VERSION ""

NS_ :

BS_:

BU_: PowertrainControlModule AtmosphericSensor SafetyRestraintSystem2 Aftertreatment_2_GasOutlet Aftertreatment_2_GasIntake DieselParticulateFilterControl Turbocharger SafetyRestraintSystem1 CabDisplay2 Aftertreatment_1_GasOutlet Aftertreatment_1_GasIntake OnBoardDataLogger OffBoardDiagnosticTool2 OffBoardDiagnosticTool1 FileServer ParkingBrakeController SeatController2 FanDriveController SteeringColumnUnit CommunicationUnitRadio CommunicationUnitSatellite CommunicationUnitCellular PropulsionBatteryCharger ChassisController2 ChassisController1 EngineValveControl AuxiliaryHeater2 AuxiliaryHeater1 ClutchUnit RampControl InformationSystem1 SuspensionSystemController2 OilSensor VehicleDynamicStability ExhaustEmissionController TransmissionDisplay2 TransmissionDisplay1 ClimateControl2 WaterPumpController RearAxleSteeringController LightingOperatorControl SeatController1 IgnitionController2 IgnitionController1 TirePressureController CabController2 CabController1 PneumaticSystemController SuspensionSystemController1 HydraulicPumpController EnduranceBrakingSystem RetarderExhaustEngine2 OnBoardDiagnosticUnit HeadwayController RetarderExhaustEngine1 CabDisplay1 ManagementComputer VirtualTerminal OffVehicleGateway PowerTakeOffFront HitchControl AuxiliaryValveControl BodyController TractorTrailerBridge1 StarterSystem ElectricalSystem VehicleSecurity VehicleNavigation AerodynamicControl ElectricalChargingSystem ClimateControl1 TripRecorder InstrumentCluster SuspensionDriveAxle2 SuspensionDriveAxle1 SuspensionSteerAxle SteeringController FuelSystem CruiseControl RetarderDriveline RetarderEngine BrakesDriveAxle2 BrakesDriveAxle1 BrakesSystemController BrakesSteerAxle AxleDrive2 AxleDrive1 AxleSteering PowerTakeOff ShiftConsoleSecondary ShiftConsolePrimary Transmission2 Transmission1 Engine2 Engine1

BO_ 2566612990 MG2IAPL: 8 Vector__XXX
 SG_ TrqLimDueToMachineCharacter_0000 : 38|2@1+ (1,0) [0|3] "" Vector__XXX
 SG_ PLedDueToActiveSpdRateLmt : 36|2@1+ (1,0) [0|3] "" Vector__XXX
 SG_ PLedDueToActiveTrqRateLmt : 34|2@1+ (1,0) [0|3] "" Vector__XXX
 SG_ PLedDueToFaultCondition : 32|2@1+ (1,0) [0|3] "" Vector__XXX
 SG_ PLedDueToMotorTemp : 30|2@1+ (1,0) [0|3] "" Vector__XXX
 SG_ PLedDueToInvTemp : 28|2@1+ (1,0) [0|3] "" Vector__XXX
 SG_ PLedDueToSpdMin : 24|2@1+ (1,0) [0|3] "" Vector__XXX
 SG_ PLedDueToSpdMax : 22|2@1+ (1,0) [0|3] "" Vector__XXX
 SG_ PLedDueToTrqMin : 20|2@1+ (1,0) [0|3] "" Vector__XXX
 SG_ PLedDueToTrqMax : 18|2@1+ (1,0) [0|3] "" Vector__XXX
 SG_ PLedDueToDCSidePwrMin : 16|2@1+ (1,0) [0|3] "" Vector__XXX
 SG_ PLedDueToDCSidePwrMax : 14|2@1+ (1,0) [0|3] "" Vector__XXX
 SG_ PLedDueToMechPwrMin : 12|2@1+ (1,0) [0|3] "" Vector__XXX
 SG_ PLedDueToMechPwrMax : 10|2@1+ (1,0) [0|3] "" Vector__XXX
 SG_ PLedDueToDCSideVMin : 8|2@1+ (1,0) [0|3] "" Vector__XXX
 SG_ PLedDueToDCSideVMax : 6|2@1+ (1,0) [0|3] "" Vector__XXX
 SG_ PLedDueToDCSideCurMin : 4|2@1+ (1,0) [0|3] "" Vector__XXX
 SG_ PLedDueToDCSideCurMax : 2|2@1+ (1,0) [0|3] "" Vector__XXX
 SG_ PLedDueToUndefinedReason : 0|2@1+ (1,0) [0|3] "" Vector__XXX

BO_ 2633721598 VFSSM4NAMES: 104 Vector__XXX
 SG_ ReleaseZone2Name : 768|64@1+ (1,0) [0|255] "" Vector__XXX
 SG_ ReleaseZone1Name : 704|64@1+ (1,0) [0|255] "" Vector__XXX
 SG_ HeatZone2Name : 640|64@1+ (1,0) [0|255] "" Vector__XXX
 SG_ HeatZone1Name : 576|64@1+ (1,0) [0|255] "" Vector__XXX
 SG_ DetectorZone8Name : 512|64@1+ (1,0) [0|255] "" Vector__XXX
 SG_ DetectorZone7Name : 448|64@1+ (1,0) [0|255] "" Vector__XXX
 SG_ DetectorZone6Name : 384|64@1+ (1,0) [0|255] "" Vector__XXX
 SG_ DetectorZone5Name : 320|64@1+ (1,0) [0|255] "" Vector__XXX
 SG_ DetectorZone4Name : 256|64@1+ (1,0) [0|255] "" Vector__XXX
 SG_ DetectorZone3Name : 192|64@1+ (1,0) [0|255] "" Vector__XXX
 SG_ DetectorZone2Name : 128|64@1+ (1,0) [0|255] "" Vector__XXX
 SG_ DetectorZone1Name : 64|64@1+ (1,0) [0|255] "" Vector__XXX
 SG_ Name : 0|64@1+ (1,0) [0|255] "" Vector__XXX

BO_ 2633721342 VFSSM3NAMES: 104 Vector__XXX
 SG_ ReleaseZone2Name : 768|64@1+ (1,0) [0|255] "" Vector__XXX
 SG_ ReleaseZone1Name : 704|64@1+ (1,0) [0|255] "" Vector__XXX
 SG_ HeatZone2Name : 640|64@1+ (1,0) [0|255] "" Vector__XXX
 SG_ HeatZone1Name : 576|64@1+ (1,0) [0|255] "" Vector__XXX
 SG_ DetectorZone8Name : 512|64@1+ (1,0) [0|255] "" Vector__XXX
 SG_ DetectorZone7Name : 448|64@1+ (1,0) [0|255] "" Vector__XXX
 SG_ DetectorZone6Name : 384|64@1+ (1,0) [0|255] "" Vector__XXX
 SG_ DetectorZone5Name : 320|64@1+ (1,0) [0|255] "" Vector__XXX
 SG_ DetectorZone4Name : 256|64@1+ (1,0) [0|255] "" Vector__XXX
 SG_ DetectorZone3Name : 192|64@1+ (1,0) [0|255] "" Vector__XXX
 SG_ DetectorZone2Name : 128|64@1+ (1,0) [0|255] "" Vector__XXX
 SG_ DetectorZone1Name : 64|64@1+ (1,0) [0|255] "" Vector__XXX
 SG_ Name : 0|64@1+ (1,0) [0|255] "" Vector__XXX

BO_ 2633721086 VFSSM2NAMES: 104 Vector__XXX
 SG_ ReleaseZone2Name : 768|64@1+ (1,0) [0|255] "" Vector__XXX
 SG_ ReleaseZone1Name : 704|64@1+ (1,0) [0|255] "" Vector__XXX
 SG_ HeatZone2Name : 640|64@1+ (1,0) [0|255] "" Vector__XXX
 SG_ HeatZone1Name : 576|64@1+ (1,0) [0|255] "" Vector__XXX
 SG_ DetectorZone8Name : 512|64@1+ (1,0) [0|255] "" Vector__XXX
 SG_ DetectorZone7Name : 448|64@1+ (1,0) [0|255] "" Vector__XXX
 SG_ DetectorZone6Name : 384|64@1+ (1,0) [0|255] "" Vector__XXX
 SG_ DetectorZone5Name : 320|64@1+ (1,0) [0|255] "" Vector__XXX
 SG_ DetectorZone4Name : 256|64@1+ (1,0) [0|255] "" Vector__XXX
 SG_ DetectorZone3Name : 192|64@1+ (1,0) [0|255] "" Vector__XXX
 SG_ DetectorZone2Name : 128|64@1+ (1,0) [0|255] "" Vector__XXX
 SG_ DetectorZone1Name : 64|64@1+ (1,0) [0|255] "" Vector__XXX
 SG_ Name : 0|64@1+ (1,0) [0|255] "" Vector__XXX

BO_ 2633720830 VFSSM1NAMES: 104 Vector__XXX
 SG_ ReleaseZone2Name : 768|64@1+ (1,0) [0|255] "" Vector__XXX
 SG_ ReleaseZone1Name : 704|64@1+ (1,0) [0|255] "" Vector__XXX
 SG_ HeatZone2Name : 640|64@1+ (1,0) [0|255] "" Vector__XXX
 SG_ HeatZone1Name : 576|64@1+ (1,0) [0|255] "" Vector__XXX
 SG_ DetectorZone8Name : 512|64@1+ (1,0) [0|255] "" Vector__XXX
 SG_ DetectorZone7Name : 448|64@1+ (1,0) [0|255] "" Vector__XXX
 SG_ DetectorZone6Name : 384|64@1+ (1,0) [0|255] "" Vector__XXX
 SG_ DetectorZone5Name : 320|64@1+ (1,0) [0|255] "" Vector__XXX
 SG_ DetectorZone4Name : 256|64@1+ (1,0) [0|255] "" Vector__XXX
 SG_ DetectorZone3Name : 192|64@1+ (1,0) [0|255] "" Vector__XXX
 SG_ DetectorZone2Name : 128|64@1+ (1,0) [0|255] "" Vector__XXX
 SG_ DetectorZone1Name : 64|64@1+ (1,0) [0|255] "" Vector__XXX
 SG_ Name : 0|64@1+ (1,0) [0|255] "" Vector__XXX

BO_ 2633720574 VFSSM4AUX: 16 Vector__XXX
 SG_ SecondPwrV : 112|16@1+ (0.01,0) [0|642.55] "V" Vector__XXX
 SG_ PrimaryPwrV : 96|16@1+ (0.01,0) [0|642.55] "V" Vector__XXX
 SG_ PressSw2Data : 80|16@1+ (0.01,0) [0|642.55] "V" Vector__XXX
 SG_ PressSw1Data : 64|16@1+ (0.01,0) [0|642.55] "V" Vector__XXX
 SG_ ReleaseZone2Data : 48|16@1+ (0.01,0) [0|642.55] "V" Vector__XXX
 SG_ ReleaseZone1Data : 32|16@1+ (0.01,0) [0|642.55] "V" Vector__XXX
 SG_ HeatZone2Data : 16|16@1+ (0.01,0) [0|642.55] "V" Vector__XXX
 SG_ HeatZone1Data : 0|16@1+ (0.01,0) [0|642.55] "V" Vector__XXX

BO_ 2633720318 VFSSM3AUX: 16 Vector__XXX
 SG_ SecondPwrV : 112|16@1+ (0.01,0) [0|642.55] "V" Vector__XXX
 SG_ PrimaryPwrV : 96|16@1+ (0.01,0) [0|642.55] "V" Vector__XXX
 SG_ PressSw2Data : 80|16@1+ (0.01,0) [0|642.55] "V" Vector__XXX
 SG_ PressSw1Data : 64|16@1+ (0.01,0) [0|642.55] "V" Vector__XXX
 SG_ ReleaseZone2Data : 48|16@1+ (0.01,0) [0|642.55] "V" Vector__XXX
 SG_ ReleaseZone1Data : 32|16@1+ (0.01,0) [0|642.55] "V" Vector__XXX
 SG_ HeatZone2Data : 16|16@1+ (0.01,0) [0|642.55] "V" Vector__XXX
 SG_ HeatZone1Data : 0|16@1+ (0.01,0) [0|642.55] "V" Vector__XXX

BO_ 2633720062 VFSSM2AUX: 16 Vector__XXX
 SG_ SecondPwrV : 112|16@1+ (0.01,0) [0|642.55] "V" Vector__XXX
 SG_ PrimaryPwrV : 96|16@1+ (0.01,0) [0|642.55] "V" Vector__XXX
 SG_ PressSw2Data : 80|16@1+ (0.01,0) [0|642.55] "V" Vector__XXX
 SG_ PressSw1Data : 64|16@1+ (0.01,0) [0|642.55] "V" Vector__XXX
 SG_ ReleaseZone2Data : 48|16@1+ (0.01,0) [0|642.55] "V" Vector__XXX
 SG_ ReleaseZone1Data : 32|16@1+ (0.01,0) [0|642.55] "V" Vector__XXX
 SG_ HeatZone2Data : 16|16@1+ (0.01,0) [0|642.55] "V" Vector__XXX
 SG_ HeatZone1Data : 0|16@1+ (0.01,0) [0|642.55] "V" Vector__XXX

BO_ 2633719806 VFSSM1AUX: 16 Vector__XXX
 SG_ SecondPwrV : 112|16@1+ (0.01,0) [0|642.55] "V" Vector__XXX
 SG_ PrimaryPwrV : 96|16@1+ (0.01,0) [0|642.55] "V" Vector__XXX
 SG_ PressSw2Data : 80|16@1+ (0.01,0) [0|642.55] "V" Vector__XXX
 SG_ PressSw1Data : 64|16@1+ (0.01,0) [0|642.55] "V" Vector__XXX
 SG_ ReleaseZone2Data : 48|16@1+ (0.01,0) [0|642.55] "V" Vector__XXX
 SG_ ReleaseZone1Data : 32|16@1+ (0.01,0) [0|642.55] "V" Vector__XXX
 SG_ HeatZone2Data : 16|16@1+ (0.01,0) [0|642.55] "V" Vector__XXX
 SG_ HeatZone1Data : 0|16@1+ (0.01,0) [0|642.55] "V" Vector__XXX

BO_ 2633719550 VFSSM4DET: 24 Vector__XXX
 SG_ Detector8Data : 176|16@1+ (1,0) [0|255] "" Vector__XXX
 SG_ Detector8DetectorDataSLOT : 172|4@1+ (1,0) [0|15] "" Vector__XXX
 SG_ Detector8DetectorType : 168|4@1+ (1,0) [0|15] "" Vector__XXX
 SG_ Detector7Data : 152|16@1+ (1,0) [0|255] "" Vector__XXX
 SG_ Detector7DetectorDataSLOT : 148|4@1+ (1,0) [0|15] "" Vector__XXX
 SG_ Detector7DetectorType : 144|4@1+ (1,0) [0|15] "" Vector__XXX
 SG_ Detector6Data : 128|16@1+ (1,0) [0|255] "" Vector__XXX
 SG_ Detector6DetectorDataSLOT : 124|4@1+ (1,0) [0|15] "" Vector__XXX
 SG_ Detector6DetectorType : 120|4@1+ (1,0) [0|15] "" Vector__XXX
 SG_ Detector5Data : 104|16@1+ (1,0) [0|255] "" Vector__XXX
 SG_ Detector5DetectorDataSLOT : 100|4@1+ (1,0) [0|15] "" Vector__XXX
 SG_ Detector5DetectorType : 96|4@1+ (1,0) [0|15] "" Vector__XXX
 SG_ Detector4Data : 80|16@1+ (1,0) [0|255] "" Vector__XXX
 SG_ Detector4DetectorDataSLOT : 76|4@1+ (1,0) [0|15] "" Vector__XXX
 SG_ Detector4DetectorType : 72|4@1+ (1,0) [0|15] "" Vector__XXX
 SG_ Detector3Data : 56|16@1+ (1,0) [0|255] "" Vector__XXX
 SG_ Detector3DetectorDataSLOT : 52|4@1+ (1,0) [0|15] "" Vector__XXX
 SG_ Detector3DetectorType : 48|4@1+ (1,0) [0|15] "" Vector__XXX
 SG_ Detector2Data : 32|16@1+ (1,0) [0|255] "" Vector__XXX
 SG_ Detector2DetectorDataSLOT : 28|4@1+ (1,0) [0|15] "" Vector__XXX
 SG_ Detector2DetectorType : 24|4@1+ (1,0) [0|15] "" Vector__XXX
 SG_ Detector1Data : 8|16@1+ (1,0) [0|255] "" Vector__XXX
 SG_ Detector1DetectorDataSLOT : 4|4@1+ (1,0) [0|15] "" Vector__XXX
 SG_ Detector1DetectorType : 0|4@1+ (1,0) [0|15] "" Vector__XXX

BO_ 2633719294 VFSSM3DET: 24 Vector__XXX
 SG_ Detector8Data : 176|16@1+ (1,0) [0|255] "" Vector__XXX
 SG_ Detector8DetectorDataSLOT : 172|4@1+ (1,0) [0|15] "" Vector__XXX
 SG_ Detector8DetectorType : 168|4@1+ (1,0) [0|15] "" Vector__XXX
 SG_ Detector7Data : 152|16@1+ (1,0) [0|255] "" Vector__XXX
 SG_ Detector7DetectorDataSLOT : 148|4@1+ (1,0) [0|15] "" Vector__XXX
 SG_ Detector7DetectorType : 144|4@1+ (1,0) [0|15] "" Vector__XXX
 SG_ Detector6Data : 128|16@1+ (1,0) [0|255] "" Vector__XXX
 SG_ Detector6DetectorDataSLOT : 124|4@1+ (1,0) [0|15] "" Vector__XXX
 SG_ Detector6DetectorType : 120|4@1+ (1,0) [0|15] "" Vector__XXX
 SG_ Detector5Data : 104|16@1+ (1,0) [0|255] "" Vector__XXX
 SG_ Detector5DetectorDataSLOT : 100|4@1+ (1,0) [0|15] "" Vector__XXX
 SG_ Detector5DetectorType : 96|4@1+ (1,0) [0|15] "" Vector__XXX
 SG_ Detector4Data : 80|16@1+ (1,0) [0|255] "" Vector__XXX
 SG_ Detector4DetectorDataSLOT : 76|4@1+ (1,0) [0|15] "" Vector__XXX
 SG_ Detector4DetectorType : 72|4@1+ (1,0) [0|15] "" Vector__XXX
 SG_ Detector3Data : 56|16@1+ (1,0) [0|255] "" Vector__XXX
 SG_ Detector3DetectorDataSLOT : 52|4@1+ (1,0) [0|15] "" Vector__XXX
 SG_ Detector3DetectorType : 48|4@1+ (1,0) [0|15] "" Vector__XXX
 SG_ Detector2Data : 32|16@1+ (1,0) [0|255] "" Vector__XXX
 SG_ Detector2DetectorDataSLOT : 28|4@1+ (1,0) [0|15] "" Vector__XXX
 SG_ Detector2DetectorType : 24|4@1+ (1,0) [0|15] "" Vector__XXX
 SG_ Detector1Data : 8|16@1+ (1,0) [0|255] "" Vector__XXX
 SG_ Detector1DetectorDataSLOT : 4|4@1+ (1,0) [0|15] "" Vector__XXX
 SG_ Detector1DetectorType : 0|4@1+ (1,0) [0|15] "" Vector__XXX

BO_ 2633719038 VFSSM2DET: 24 Vector__XXX
 SG_ Detector8Data : 176|16@1+ (1,0) [0|255] "" Vector__XXX
 SG_ Detector8DetectorDataSLOT : 172|4@1+ (1,0) [0|15] "" Vector__XXX
 SG_ Detector8DetectorType : 168|4@1+ (1,0) [0|15] "" Vector__XXX
 SG_ Detector7Data : 152|16@1+ (1,0) [0|255] "" Vector__XXX
 SG_ Detector7DetectorDataSLOT : 148|4@1+ (1,0) [0|15] "" Vector__XXX
 SG_ Detector7DetectorType : 144|4@1+ (1,0) [0|15] "" Vector__XXX
 SG_ Detector6Data : 128|16@1+ (1,0) [0|255] "" Vector__XXX
 SG_ Detector6DetectorDataSLOT : 124|4@1+ (1,0) [0|15] "" Vector__XXX
 SG_ Detector6DetectorType : 120|4@1+ (1,0) [0|15] "" Vector__XXX
 SG_ Detector5Data : 104|16@1+ (1,0) [0|255] "" Vector__XXX
 SG_ Detector5DetectorDataSLOT : 100|4@1+ (1,0) [0|15] "" Vector__XXX
 SG_ Detector5DetectorType : 96|4@1+ (1,0) [0|15] "" Vector__XXX
 SG_ Detector4Data : 80|16@1+ (1,0) [0|255] "" Vector__XXX
 SG_ Detector4DetectorDataSLOT : 76|4@1+ (1,0) [0|15] "" Vector__XXX
 SG_ Detector4DetectorType : 72|4@1+ (1,0) [0|15] "" Vector__XXX
 SG_ Detector3Data : 56|16@1+ (1,0) [0|255] "" Vector__XXX
 SG_ Detector3DetectorDataSLOT : 52|4@1+ (1,0) [0|15] "" Vector__XXX
 SG_ Detector3DetectorType : 48|4@1+ (1,0) [0|15] "" Vector__XXX
 SG_ Detector2Data : 32|16@1+ (1,0) [0|255] "" Vector__XXX
 SG_ Detector2DetectorDataSLOT : 28|4@1+ (1,0) [0|15] "" Vector__XXX
 SG_ Detector2DetectorType : 24|4@1+ (1,0) [0|15] "" Vector__XXX
 SG_ Detector1Data : 8|16@1+ (1,0) [0|255] "" Vector__XXX
 SG_ Detector1DetectorDataSLOT : 4|4@1+ (1,0) [0|15] "" Vector__XXX
 SG_ Detector1DetectorType : 0|4@1+ (1,0) [0|15] "" Vector__XXX

BO_ 2633718782 VFSSM1DET: 24 Vector__XXX
 SG_ Detector8Data : 176|16@1+ (1,0) [0|255] "" Vector__XXX
 SG_ Detector8DetectorDataSLOT : 172|4@1+ (1,0) [0|15] "" Vector__XXX
 SG_ Detector8DetectorType : 168|4@1+ (1,0) [0|15] "" Vector__XXX
 SG_ Detector7Data : 152|16@1+ (1,0) [0|255] "" Vector__XXX
 SG_ Detector7DetectorDataSLOT : 148|4@1+ (1,0) [0|15] "" Vector__XXX
 SG_ Detector7DetectorType : 144|4@1+ (1,0) [0|15] "" Vector__XXX
 SG_ Detector6Data : 128|16@1+ (1,0) [0|255] "" Vector__XXX
 SG_ Detector6DetectorDataSLOT : 124|4@1+ (1,0) [0|15] "" Vector__XXX
 SG_ Detector6DetectorType : 120|4@1+ (1,0) [0|15] "" Vector__XXX
 SG_ Detector5Data : 104|16@1+ (1,0) [0|255] "" Vector__XXX
 SG_ Detector5DetectorDataSLOT : 100|4@1+ (1,0) [0|15] "" Vector__XXX
 SG_ Detector5DetectorType : 96|4@1+ (1,0) [0|15] "" Vector__XXX
 SG_ Detector4Data : 80|16@1+ (1,0) [0|255] "" Vector__XXX
 SG_ Detector4DetectorDataSLOT : 76|4@1+ (1,0) [0|15] "" Vector__XXX
 SG_ Detector4DetectorType : 72|4@1+ (1,0) [0|15] "" Vector__XXX
 SG_ Detector3Data : 56|16@1+ (1,0) [0|255] "" Vector__XXX
 SG_ Detector3DetectorDataSLOT : 52|4@1+ (1,0) [0|15] "" Vector__XXX
 SG_ Detector3DetectorType : 48|4@1+ (1,0) [0|15] "" Vector__XXX
 SG_ Detector2Data : 32|16@1+ (1,0) [0|255] "" Vector__XXX
 SG_ Detector2DetectorDataSLOT : 28|4@1+ (1,0) [0|15] "" Vector__XXX
 SG_ Detector2DetectorType : 24|4@1+ (1,0) [0|15] "" Vector__XXX
 SG_ Detector1Data : 8|16@1+ (1,0) [0|255] "" Vector__XXX
 SG_ Detector1DetectorDataSLOT : 4|4@1+ (1,0) [0|15] "" Vector__XXX
 SG_ Detector1DetectorType : 0|4@1+ (1,0) [0|15] "" Vector__XXX

BO_ 2566609662 HVESP1CFG: 19 Vector__XXX
 SG_ NomRatedCapacity : 128|24@1+ (0.001,0) [0|16449.535] "kWh" Vector__XXX
 SG_ CellMinVLmt : 120|8@1+ (0.02044,0) [0|5.11] "V" Vector__XXX
 SG_ CellMaxVLmt : 112|8@1+ (0.02044,0) [0|5.11] "V" Vector__XXX
 SG_ RecommendedMinOperatingTemp : 96|16@1+ (0.03125,-273) [-273|1734.96875] "°C" Vector__XXX
 SG_ RecommendedMaxOperatingTemp : 80|16@1+ (0.03125,-273) [-273|1734.96875] "°C" Vector__XXX
 SG_ RecommendedMaxStOfCharge : 64|16@1+ (0.0015625,0) [0|100.3984375] "%" Vector__XXX
 SG_ RecommendedMinStOfCharge : 48|16@1+ (0.0015625,0) [0|100.3984375] "%" Vector__XXX
 SG_ RecommendedMaxOperatingV : 32|16@1+ (0.05,0) [0|3212.75] "V" Vector__XXX
 SG_ RecommendedMinOperatingV : 16|16@1+ (0.05,0) [0|3212.75] "V" Vector__XXX
 SG_ NomV : 0|16@1+ (0.05,0) [0|3212.75] "V" Vector__XXX

BO_ 2633718270 HVESP1HIST: 19 Vector__XXX
 SG_ TotalEnergyOut : 120|32@1+ (1,0) [0|4211081215] "kWh" Vector__XXX
 SG_ TotalEnergyInput : 88|32@1+ (1,0) [0|4211081215] "kWh" Vector__XXX
 SG_ TotalAccumulatedCharge : 56|32@1+ (100,0) [0|421108121500] "Ah" Vector__XXX
 SG_ TotalEnergyThroughput : 24|32@1+ (100,0) [0|421108121500] "Wh" Vector__XXX
 SG_ ContactorOpenUnderLoadCount : 8|16@1+ (1,0) [0|64255] "" Vector__XXX
 SG_ StOfHealth : 0|8@1+ (0.4,0) [0|100] "%" Vector__XXX

BO_ 2566609150 HVESP2CFG: 19 Vector__XXX
 SG_ NomRatedCapacity : 128|24@1+ (0.001,0) [0|16449.535] "kWh" Vector__XXX
 SG_ CellMinVLmt : 120|8@1+ (0.02044,0) [0|5.11] "V" Vector__XXX
 SG_ CellMaxVLmt : 112|8@1+ (0.02044,0) [0|5.11] "V" Vector__XXX
 SG_ RecommendedMinOperatingTemp : 96|16@1+ (0.03125,-273) [-273|1734.96875] "°C" Vector__XXX
 SG_ RecommendedMaxOperatingTemp : 80|16@1+ (0.03125,-273) [-273|1734.96875] "°C" Vector__XXX
 SG_ RecommendedMaxStOfCharge : 64|16@1+ (0.0015625,0) [0|100.3984375] "%" Vector__XXX
 SG_ RecommendedMinStOfCharge : 48|16@1+ (0.0015625,0) [0|100.3984375] "%" Vector__XXX
 SG_ RecommendedMaxOperatingV : 32|16@1+ (0.05,0) [0|3212.75] "V" Vector__XXX
 SG_ RecommendedMinOperatingV : 16|16@1+ (0.05,0) [0|3212.75] "V" Vector__XXX
 SG_ NomV : 0|16@1+ (0.05,0) [0|3212.75] "V" Vector__XXX

BO_ 2633717758 HVESP2HIST: 19 Vector__XXX
 SG_ TotalEnergyOut : 120|32@1+ (1,0) [0|4211081215] "kWh" Vector__XXX
 SG_ TotalEnergyInput : 88|32@1+ (1,0) [0|4211081215] "kWh" Vector__XXX
 SG_ TotalAccumulatedCharge : 56|32@1+ (100,0) [0|421108121500] "Ah" Vector__XXX
 SG_ TotalEnergyThroughput : 24|32@1+ (100,0) [0|421108121500] "Wh" Vector__XXX
 SG_ ContactorOpenUnderLoadCount : 8|16@1+ (1,0) [0|64255] "" Vector__XXX
 SG_ StOfHealth : 0|8@1+ (0.4,0) [0|100] "%" Vector__XXX

BO_ 2566608638 HVESP3CFG: 19 Vector__XXX
 SG_ NomRatedCapacity : 128|24@1+ (0.001,0) [0|16449.535] "kWh" Vector__XXX
 SG_ CellMinVLmt : 120|8@1+ (0.02044,0) [0|5.11] "V" Vector__XXX
 SG_ CellMaxVLmt : 112|8@1+ (0.02044,0) [0|5.11] "V" Vector__XXX
 SG_ RecommendedMinOperatingTemp : 96|16@1+ (0.03125,-273) [-273|1734.96875] "°C" Vector__XXX
 SG_ RecommendedMaxOperatingTemp : 80|16@1+ (0.03125,-273) [-273|1734.96875] "°C" Vector__XXX
 SG_ RecommendedMaxStOfCharge : 64|16@1+ (0.0015625,0) [0|100.3984375] "%" Vector__XXX
 SG_ RecommendedMinStOfCharge : 48|16@1+ (0.0015625,0) [0|100.3984375] "%" Vector__XXX
 SG_ RecommendedMaxOperatingV : 32|16@1+ (0.05,0) [0|3212.75] "V" Vector__XXX
 SG_ RecommendedMinOperatingV : 16|16@1+ (0.05,0) [0|3212.75] "V" Vector__XXX
 SG_ NomV : 0|16@1+ (0.05,0) [0|3212.75] "V" Vector__XXX

BO_ 2633717246 HVESP3HIST: 19 Vector__XXX
 SG_ TotalEnergyOut : 120|32@1+ (1,0) [0|4211081215] "kWh" Vector__XXX
 SG_ TotalEnergyInput : 88|32@1+ (1,0) [0|4211081215] "kWh" Vector__XXX
 SG_ TotalAccumulatedCharge : 56|32@1+ (100,0) [0|421108121500] "Ah" Vector__XXX
 SG_ TotalEnergyThroughput : 24|32@1+ (100,0) [0|421108121500] "Wh" Vector__XXX
 SG_ ContactorOpenUnderLoadCount : 8|16@1+ (1,0) [0|64255] "" Vector__XXX
 SG_ StOfHealth : 0|8@1+ (0.4,0) [0|100] "%" Vector__XXX

BO_ 2566608126 HVESP4CFG: 19 Vector__XXX
 SG_ NomRatedCapacity : 128|24@1+ (0.001,0) [0|16449.535] "kWh" Vector__XXX
 SG_ CellMinVLmt : 120|8@1+ (0.02044,0) [0|5.11] "V" Vector__XXX
 SG_ CellMaxVLmt : 112|8@1+ (0.02044,0) [0|5.11] "V" Vector__XXX
 SG_ RecommendedMinOperatingTemp : 96|16@1+ (0.03125,-273) [-273|1734.96875] "°C" Vector__XXX
 SG_ RecommendedMaxOperatingTemp : 80|16@1+ (0.03125,-273) [-273|1734.96875] "°C" Vector__XXX
 SG_ RecommendedMaxStOfCharge : 64|16@1+ (0.0015625,0) [0|100.3984375] "%" Vector__XXX
 SG_ RecommendedMinStOfCharge : 48|16@1+ (0.0015625,0) [0|100.3984375] "%" Vector__XXX
 SG_ RecommendedMaxOperatingV : 32|16@1+ (0.05,0) [0|3212.75] "V" Vector__XXX
 SG_ RecommendedMinOperatingV : 16|16@1+ (0.05,0) [0|3212.75] "V" Vector__XXX
 SG_ NomV : 0|16@1+ (0.05,0) [0|3212.75] "V" Vector__XXX

BO_ 2633716734 HVESP4HIST: 19 Vector__XXX
 SG_ TotalEnergyOut : 120|32@1+ (1,0) [0|4211081215] "kWh" Vector__XXX
 SG_ TotalEnergyInput : 88|32@1+ (1,0) [0|4211081215] "kWh" Vector__XXX
 SG_ TotalAccumulatedCharge : 56|32@1+ (100,0) [0|421108121500] "Ah" Vector__XXX
 SG_ TotalEnergyThroughput : 24|32@1+ (100,0) [0|421108121500] "Wh" Vector__XXX
 SG_ ContactorOpenUnderLoadCount : 8|16@1+ (1,0) [0|64255] "" Vector__XXX
 SG_ StOfHealth : 0|8@1+ (0.4,0) [0|100] "%" Vector__XXX

BO_ 2566607614 HVESP5CFG: 19 Vector__XXX
 SG_ NomRatedCapacity : 128|24@1+ (0.001,0) [0|16449.535] "kWh" Vector__XXX
 SG_ CellMinVLmt : 120|8@1+ (0.02044,0) [0|5.11] "V" Vector__XXX
 SG_ CellMaxVLmt : 112|8@1+ (0.02044,0) [0|5.11] "V" Vector__XXX
 SG_ RecommendedMinOperatingTemp : 96|16@1+ (0.03125,-273) [-273|1734.96875] "°C" Vector__XXX
 SG_ RecommendedMaxOperatingTemp : 80|16@1+ (0.03125,-273) [-273|1734.96875] "°C" Vector__XXX
 SG_ RecommendedMaxStOfCharge : 64|16@1+ (0.0015625,0) [0|100.3984375] "%" Vector__XXX
 SG_ RecommendedMinStOfCharge : 48|16@1+ (0.0015625,0) [0|100.3984375] "%" Vector__XXX
 SG_ RecommendedMaxOperatingV : 32|16@1+ (0.05,0) [0|3212.75] "V" Vector__XXX
 SG_ RecommendedMinOperatingV : 16|16@1+ (0.05,0) [0|3212.75] "V" Vector__XXX
 SG_ NomV : 0|16@1+ (0.05,0) [0|3212.75] "V" Vector__XXX

BO_ 2633716222 HVESP5HIST: 19 Vector__XXX
 SG_ TotalEnergyOut : 120|32@1+ (1,0) [0|4211081215] "kWh" Vector__XXX
 SG_ TotalEnergyInput : 88|32@1+ (1,0) [0|4211081215] "kWh" Vector__XXX
 SG_ TotalAccumulatedCharge : 56|32@1+ (100,0) [0|421108121500] "Ah" Vector__XXX
 SG_ TotalEnergyThroughput : 24|32@1+ (100,0) [0|421108121500] "Wh" Vector__XXX
 SG_ ContactorOpenUnderLoadCount : 8|16@1+ (1,0) [0|64255] "" Vector__XXX
 SG_ StOfHealth : 0|8@1+ (0.4,0) [0|100] "%" Vector__XXX

BO_ 2566607102 HVESP6CFG: 19 Vector__XXX
 SG_ NomRatedCapacity : 128|24@1+ (0.001,0) [0|16449.535] "kWh" Vector__XXX
 SG_ CellMinVLmt : 120|8@1+ (0.02044,0) [0|5.11] "V" Vector__XXX
 SG_ CellMaxVLmt : 112|8@1+ (0.02044,0) [0|5.11] "V" Vector__XXX
 SG_ RecommendedMinOperatingTemp : 96|16@1+ (0.03125,-273) [-273|1734.96875] "°C" Vector__XXX
 SG_ RecommendedMaxOperatingTemp : 80|16@1+ (0.03125,-273) [-273|1734.96875] "°C" Vector__XXX
 SG_ RecommendedMaxStOfCharge : 64|16@1+ (0.0015625,0) [0|100.3984375] "%" Vector__XXX
 SG_ RecommendedMinStOfCharge : 48|16@1+ (0.0015625,0) [0|100.3984375] "%" Vector__XXX
 SG_ RecommendedMaxOperatingV : 32|16@1+ (0.05,0) [0|3212.75] "V" Vector__XXX
 SG_ RecommendedMinOperatingV : 16|16@1+ (0.05,0) [0|3212.75] "V" Vector__XXX
 SG_ NomV : 0|16@1+ (0.05,0) [0|3212.75] "V" Vector__XXX

BO_ 2633715710 HVESP6HIST: 19 Vector__XXX
 SG_ TotalEnergyOut : 120|32@1+ (1,0) [0|4211081215] "kWh" Vector__XXX
 SG_ TotalEnergyInput : 88|32@1+ (1,0) [0|4211081215] "kWh" Vector__XXX
 SG_ TotalAccumulatedCharge : 56|32@1+ (100,0) [0|421108121500] "Ah" Vector__XXX
 SG_ TotalEnergyThroughput : 24|32@1+ (100,0) [0|421108121500] "Wh" Vector__XXX
 SG_ ContactorOpenUnderLoadCount : 8|16@1+ (1,0) [0|64255] "" Vector__XXX
 SG_ StOfHealth : 0|8@1+ (0.4,0) [0|100] "%" Vector__XXX

BO_ 2499497726 HCI1: 8 Vector__XXX
 SG_ LeverDetentPosStatus : 16|2@1+ (1,0) [0|3] "" Vector__XXX
 SG_ LeverPos : 0|16@1+ (0.005,-150) [-100|100] "%" Vector__XXX

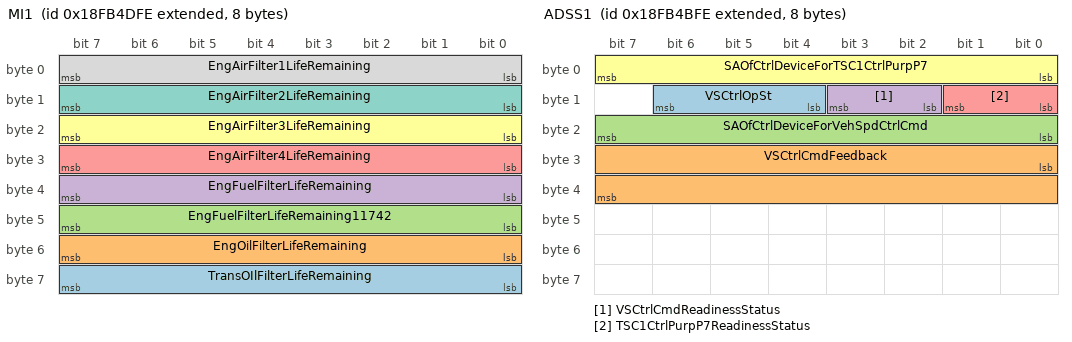
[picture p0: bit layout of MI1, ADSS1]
BO_ 2566606334 MI1: 8 Vector__XXX
 SG_ TransOIlFilterLifeRemaining : 56|8@1+ (0.4,0) [0|100] "%" Vector__XXX
 SG_ EngOilFilterLifeRemaining : 48|8@1+ (0.4,0) [0|100] "%" Vector__XXX
 SG_ EngFuelFilterLifeRemaining11742 : 40|8@1+ (0.4,0) [0|100] "%" Vector__XXX
 SG_ EngFuelFilterLifeRemaining : 32|8@1+ (0.4,0) [0|100] "%" Vector__XXX
 SG_ EngAirFilter4LifeRemaining : 24|8@1+ (0.4,0) [0|100] "%" Vector__XXX
 SG_ EngAirFilter3LifeRemaining : 16|8@1+ (0.4,0) [0|100] "%" Vector__XXX
 SG_ EngAirFilter2LifeRemaining : 8|8@1+ (0.4,0) [0|100] "%" Vector__XXX
 SG_ EngAirFilter1LifeRemaining : 0|8@1+ (0.4,0) [0|100] "%" Vector__XXX

BO_ 2566606078 CCSI2: 8 Vector__XXX
 SG_ A_CCompressorPwr : 16|16@1+ (0.5,0) [0|32127.5] "W" Vector__XXX
 SG_ HtrPwr : 0|16@1+ (2,0) [0|128510] "W" Vector__XXX

BO_ 2566605822 ADSS1: 8 Vector__XXX
 SG_ VSCtrlOpSt : 12|3@1+ (1,0) [0|7] "" Vector__XXX
 SG_ VSCtrlCmdFeedback : 24|16@1+ (0.00390625,0) [0|250.99609375] "km/h" Vector__XXX
 SG_ SAOfCtrlDeviceForVehSpdCtrlCmd : 16|8@1+ (1,0) [0|255] "" Vector__XXX
 SG_ VSCtrlCmdReadinessStatus : 10|2@1+ (1,0) [0|3] "" Vector__XXX
 SG_ TSC1CtrlPurpP7ReadinessStatus : 8|2@1+ (1,0) [0|3] "" Vector__XXX
 SG_ SAOfCtrlDeviceForTSC1CtrlPurpP7 : 0|8@1+ (1,0) [0|255] "" Vector__XXX

BO_ 2566605566 MG3IAPL: 8 Vector__XXX
 SG_ TrqLimDueToMachineCharacter_0001 : 38|2@1+ (1,0) [0|3] "" Vector__XXX
 SG_ PLedDueToActiveSpdRateLmt : 36|2@1+ (1,0) [0|3] "" Vector__XXX
 SG_ PLedDueToActiveTrqRateLmt : 34|2@1+ (1,0) [0|3] "" Vector__XXX
 SG_ PLedDueToFaultCondition : 32|2@1+ (1,0) [0|3] "" Vector__XXX
 SG_ PLedDueToMotorTemp : 30|2@1+ (1,0) [0|3] "" Vector__XXX
 SG_ PLedDueToInvTemp : 28|2@1+ (1,0) [0|3] "" Vector__XXX
 SG_ PLedDueToSpdMin : 24|2@1+ (1,0) [0|3] "" Vector__XXX
 SG_ PLedDueToSpdMax : 22|2@1+ (1,0) [0|3] "" Vector__XXX
 SG_ PLedDueToTrqMin : 20|2@1+ (1,0) [0|3] "" Vector__XXX
 SG_ PLedDueToTrqMax : 18|2@1+ (1,0) [0|3] "" Vector__XXX
 SG_ PLedDueToDCSidePwrMin : 16|2@1+ (1,0) [0|3] "" Vector__XXX
 SG_ PLedDueToDCSidePwrMax : 14|2@1+ (1,0) [0|3] "" Vector__XXX
 SG_ PLedDueToMechPwrMin : 12|2@1+ (1,0) [0|3] "" Vector__XXX
 SG_ PLedDueToMechPwrMax : 10|2@1+ (1,0) [0|3] "" Vector__XXX
 SG_ PLedDueToDCSideVMin : 8|2@1+ (1,0) [0|3] "" Vector__XXX
 SG_ PLedDueToDCSideVMax : 6|2@1+ (1,0) [0|3] "" Vector__XXX
 SG_ PLedDueToDCSideCurMin : 4|2@1+ (1,0) [0|3] "" Vector__XXX
 SG_ PLedDueToDCSideCurMax : 2|2@1+ (1,0) [0|3] "" Vector__XXX
 SG_ PLedDueToUndefinedReason : 0|2@1+ (1,0) [0|3] "" Vector__XXX

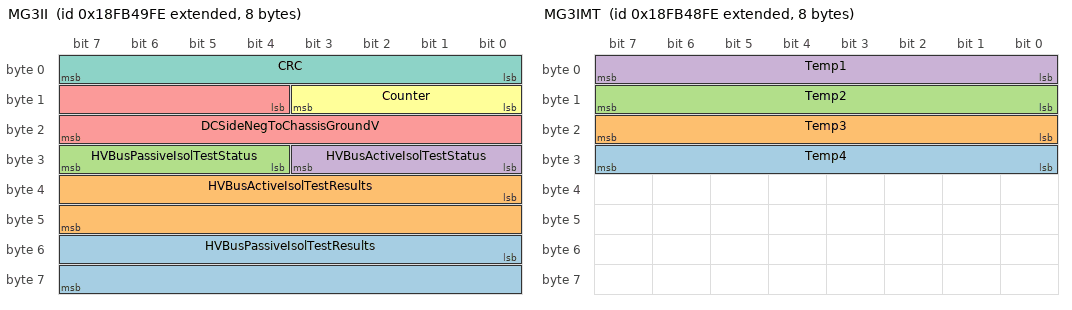
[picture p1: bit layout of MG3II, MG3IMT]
BO_ 2566605310 MG3II: 8 Vector__XXX
 SG_ HVBusPassiveIsolTestResults : 48|16@1+ (0.1,0) [0|6425.5] "Ohm/V" Vector__XXX
 SG_ HVBusActiveIsolTestResults : 32|16@1+ (0.1,0) [0|6425.5] "Ohm/V" Vector__XXX
 SG_ HVBusPassiveIsolTestStatus : 28|4@1+ (1,0) [0|15] "" Vector__XXX
 SG_ HVBusActiveIsolTestStatus : 24|4@1+ (1,0) [0|15] "" Vector__XXX
 SG_ DCSideNegToChassisGroundV : 12|12@1+ (0.0625,-125) [-125|125.9375] "%" Vector__XXX
 SG_ Counter : 8|4@1+ (1,0) [0|15] "" Vector__XXX
 SG_ CRC : 0|8@1+ (1,0) [0|255] "" Vector__XXX

BO_ 2566605054 MG3IMT: 8 Vector__XXX
 SG_ Temp4 : 24|8@1+ (1,-40) [-40|210] "°C" Vector__XXX
 SG_ Temp3 : 16|8@1+ (1,-40) [-40|210] "°C" Vector__XXX
 SG_ Temp2 : 8|8@1+ (1,-40) [-40|210] "°C" Vector__XXX
 SG_ Temp1 : 0|8@1+ (1,-40) [-40|210] "°C" Vector__XXX

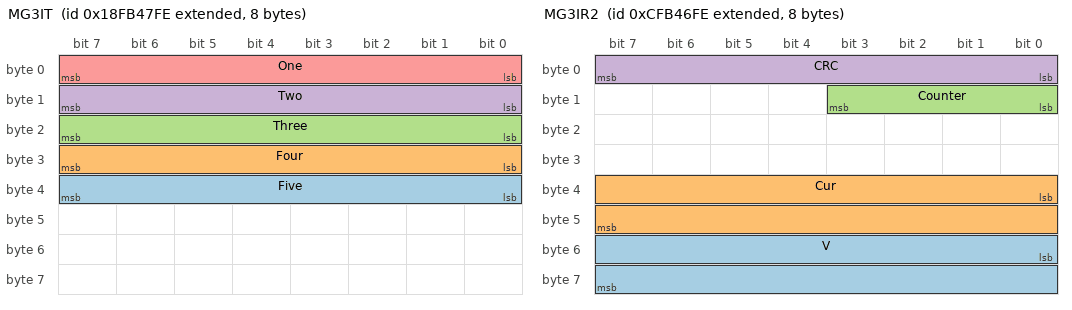
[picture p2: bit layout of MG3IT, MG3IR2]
BO_ 2566604798 MG3IT: 8 Vector__XXX
 SG_ Five : 32|8@1+ (1,-40) [-40|210] "°C" Vector__XXX
 SG_ Four : 24|8@1+ (1,-40) [-40|210] "°C" Vector__XXX
 SG_ Three : 16|8@1+ (1,-40) [-40|210] "°C" Vector__XXX
 SG_ Two : 8|8@1+ (1,-40) [-40|210] "°C" Vector__XXX
 SG_ One : 0|8@1+ (1,-40) [-40|210] "°C" Vector__XXX

BO_ 2365277950 MG3IR2: 8 Vector__XXX
 SG_ V : 48|16@1+ (0.125,0) [0|8031.875] "V" Vector__XXX
 SG_ Cur : 32|16@1+ (0.125,0) [0|8031.875] "A" Vector__XXX
 SG_ Counter : 8|4@1+ (1,0) [0|15] "" Vector__XXX
 SG_ CRC : 0|8@1+ (1,0) [0|255] "" Vector__XXX

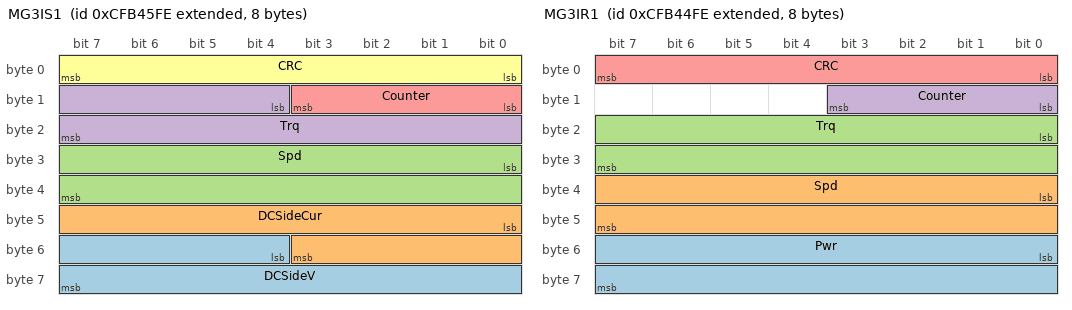
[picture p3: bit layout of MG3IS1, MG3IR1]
BO_ 2365277694 MG3IS1: 8 Vector__XXX
 SG_ DCSideV : 52|12@1+ (0.0625,-125) [-125|125.9375] "%" Vector__XXX
 SG_ DCSideCur : 40|12@1+ (0.0625,-125) [-125|125.9375] "%" Vector__XXX
 SG_ Spd : 24|16@1+ (0.00390625,-125) [-125|125.99609375] "%" Vector__XXX
 SG_ Trq : 12|12@1+ (0.0625,-125) [-125|125.9375] "%" Vector__XXX
 SG_ Counter : 8|4@1+ (1,0) [0|15] "" Vector__XXX
 SG_ CRC : 0|8@1+ (1,0) [0|255] "" Vector__XXX

BO_ 2365277438 MG3IR1: 8 Vector__XXX
 SG_ Pwr : 48|16@1+ (0.0625,0) [0|4015.9375] "kW" Vector__XXX
 SG_ Spd : 32|16@1+ (4,0) [0|257020] "rpm" Vector__XXX
 SG_ Trq : 16|16@1+ (0.5,0) [0|32127.5] "Nm" Vector__XXX
 SG_ Counter : 8|4@1+ (1,0) [0|15] "" Vector__XXX
 SG_ CRC : 0|8@1+ (1,0) [0|255] "" Vector__XXX

BO_ 2566603774 MG4IAPL: 8 Vector__XXX
 SG_ TrqLimDueToMachineCharacter_0002 : 38|2@1+ (1,0) [0|3] "" Vector__XXX
 SG_ PLedDueToActiveSpdRateLmt : 36|2@1+ (1,0) [0|3] "" Vector__XXX
 SG_ PLedDueToActiveTrqRateLmt : 34|2@1+ (1,0) [0|3] "" Vector__XXX
 SG_ PLedDueToFaultCondition : 32|2@1+ (1,0) [0|3] "" Vector__XXX
 SG_ PLedDueToMotorTemp : 30|2@1+ (1,0) [0|3] "" Vector__XXX
 SG_ PLedDueToInvTemp : 28|2@1+ (1,0) [0|3] "" Vector__XXX
 SG_ PLedDueToSpdMin : 24|2@1+ (1,0) [0|3] "" Vector__XXX
 SG_ PLedDueToSpdMax : 22|2@1+ (1,0) [0|3] "" Vector__XXX
 SG_ PLedDueToTrqMin : 20|2@1+ (1,0) [0|3] "" Vector__XXX
 SG_ PLedDueToTrqMax : 18|2@1+ (1,0) [0|3] "" Vector__XXX
 SG_ PLedDueToDCSidePwrMin : 16|2@1+ (1,0) [0|3] "" Vector__XXX
 SG_ PLedDueToDCSidePwrMax : 14|2@1+ (1,0) [0|3] "" Vector__XXX
 SG_ PLedDueToMechPwrMin : 12|2@1+ (1,0) [0|3] "" Vector__XXX
 SG_ PLedDueToMechPwrMax : 10|2@1+ (1,0) [0|3] "" Vector__XXX
 SG_ PLedDueToDCSideVMin : 8|2@1+ (1,0) [0|3] "" Vector__XXX
 SG_ PLedDueToDCSideVMax : 6|2@1+ (1,0) [0|3] "" Vector__XXX
 SG_ PLedDueToDCSideCurMin : 4|2@1+ (1,0) [0|3] "" Vector__XXX
 SG_ PLedDueToDCSideCurMax : 2|2@1+ (1,0) [0|3] "" Vector__XXX
 SG_ PLedDueToUndefinedReason : 0|2@1+ (1,0) [0|3] "" Vector__XXX

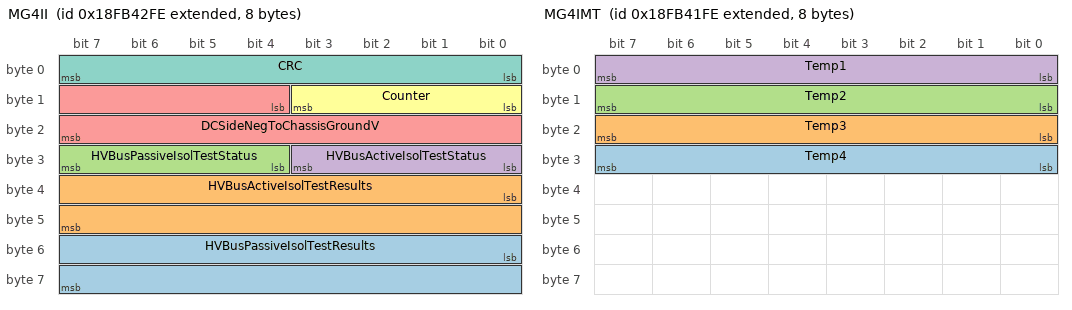
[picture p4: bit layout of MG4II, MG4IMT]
BO_ 2566603518 MG4II: 8 Vector__XXX
 SG_ HVBusPassiveIsolTestResults : 48|16@1+ (0.1,0) [0|6425.5] "Ohm/V" Vector__XXX
 SG_ HVBusActiveIsolTestResults : 32|16@1+ (0.1,0) [0|6425.5] "Ohm/V" Vector__XXX
 SG_ HVBusPassiveIsolTestStatus : 28|4@1+ (1,0) [0|15] "" Vector__XXX
 SG_ HVBusActiveIsolTestStatus : 24|4@1+ (1,0) [0|15] "" Vector__XXX
 SG_ DCSideNegToChassisGroundV : 12|12@1+ (0.0625,-125) [-125|125.9375] "%" Vector__XXX
 SG_ Counter : 8|4@1+ (1,0) [0|15] "" Vector__XXX
 SG_ CRC : 0|8@1+ (1,0) [0|255] "" Vector__XXX

BO_ 2566603262 MG4IMT: 8 Vector__XXX
 SG_ Temp4 : 24|8@1+ (1,-40) [-40|210] "°C" Vector__XXX
 SG_ Temp3 : 16|8@1+ (1,-40) [-40|210] "°C" Vector__XXX
 SG_ Temp2 : 8|8@1+ (1,-40) [-40|210] "°C" Vector__XXX
 SG_ Temp1 : 0|8@1+ (1,-40) [-40|210] "°C" Vector__XXX

CM_ BO_ 2566612990 "Motor/Generator 2 Inverter Active Power Limits
Sent by this Motor/Generator Inverter instance and contains the current operating conditions of the inverter.  This message would be received by a controller application that is responsible for ...";
CM_ SG_ 2566612990 TrqLimDueToMachineCharacter_0000 "Output torque is being limited due to SPN 9062 [Torque] approaching or exceeding a motor design characteristic.  For example, for permanent magnet machines, this would be in the field weakening area.
00b = No torque limit for this reason
01b = ...";
CM_ SG_ 2566612990 PLedDueToActiveSpdRateLmt "Output power is being limited due to exceeding internally defined speed rate limit(s) or SPN 10834 [Inverter Rate Limits Request Absolute Speed Rate Limit].
00b = No power limit for this reason
01b = Power limited for this reason
10b = Error
11b ...";
CM_ SG_ 2566612990 PLedDueToActiveTrqRateLmt "Output power is being limited due to exceeding internally defined torque rate limit(s) or SPN 10835 [Inverter Rate Limits Request Absolute Torque Rate Limit].
00b = No power limit for this reason
01b = Power limited for this reason
10b = Error
 ...";
CM_ SG_ 2566612990 PLedDueToFaultCondition "Output power is being limited due to an fault condition that requires a torque limitation to prevent further damage (e.g. “limp home mode”).  For example, this could be in case of temperature sensor defects.  Typically, this parameter would be ...";
CM_ SG_ 2566612990 PLedDueToMotorTemp "Output power is being limited due to one or more motor temperature(s), see SPNs 9060 and 10286 through 10288 [Motor Temperature 1-4] approaching or exceeding internally defined limit(s).
00b = No power limit for this reason
01b = Power limited for ...";
CM_ SG_ 2566612990 PLedDueToInvTemp "Output power is being limited due to one or more inverter temperature(s), see SPNs 10282 through 10285 [Inverter Temperature 1-4] approaching or exceeding internally defined limit(s).
00b = No power limit for this reason
01b = Power limited for ...";
CM_ SG_ 2566612990 PLedDueToSpdMin "Output power is being limited due to SPN 9058 [Speed] approaching or falling below the SPN 10265 [Inverter Limits Active Speed Minimum].

00b = No power limit for this reason
01b = Power limited for this reason
10b = Error
11b = Not Available";
CM_ SG_ 2566612990 PLedDueToSpdMax "Output power is being limited due to SPN 9058 [Speed] approaching or exceeding the SPN 10264 [Inverter Limits Active Speed Maximum].

00b = No power limit for this reason
01b = Power limited for this reason
10b = Error
11b = Not Available";
CM_ SG_ 2566612990 PLedDueToTrqMin "Output power is being limited due to SPN 9062 [Torque] approaching or falling below the SPN 10263 [Inverter Limits Active Torque Minimum].

00b = No power limit for this reason
01b = Power limited for this reason
10b = Error
11b = Not Available";
CM_ SG_ 2566612990 PLedDueToTrqMax "Output power is being limited due to SPN 9062 [Torque] approaching or exceeding the SPN 10262 [Inverter Limits Active Torque Maximum].

00b = No power limit for this reason
01b = Power limited for this reason
10b = Error
11b = Not Available";
CM_ SG_ 2566612990 PLedDueToDCSidePwrMin "Output power is being limited due to DC Side Power (product of SPN 10241 [Inverter DC Side Current] and SPN 9102 [Inverter DC Side Voltage]) approaching or falling below the SPN 10253 [Inverter Limits Active DC Side Power Minimum].
00b = No power ...";
CM_ SG_ 2566612990 PLedDueToDCSidePwrMax "Output power is being limited due to DC Side Power (product of SPN 10241 [Inverter DC Side Current] and SPN 9102 [Inverter DC Side Voltage]) approaching or exceeding the SPN 10252 [Inverter Limits Active DC Side Power Maximum].
00b = No power limit ...";
CM_ SG_ 2566612990 PLedDueToMechPwrMin "Output power is being limited due to Mechanical Power (product of SPN 9062 [Torque] and SPN 9058 [Speed]) approaching or falling below the SPN 10251 [Inverter Limits Active Mechanical Power Minimum].
00b = No power limit for this reason
01b = ...";
CM_ SG_ 2566612990 PLedDueToMechPwrMax "Output power is being limited due to Mechanical Power (product of SPN 9062 [Torque] and SPN 9058 [Speed]) approaching or exceeding the SPN 10250 [Inverter Limits Active Mechanical Power Maximum].
00b = No power limit for this reason
01b = Power ...";
CM_ SG_ 2566612990 PLedDueToDCSideVMin "Output power is being limited due to SPN 9102 [Inverter DC Side Voltage] approaching or falling below the SPN 10279 [Inverter Limits Active DC Side Voltage Minimum].
00b = No power limit for this reason
01b = Power limited for this reason
10b = ...";
CM_ SG_ 2566612990 PLedDueToDCSideVMax "Output power is being limited due to SPN 9102 [Inverter DC Side Voltage] approaching or exceeding the SPN 10278 [Inverter Limits Active DC Side Voltage Maximum].
00b = No power limit for this reason
01b = Power limited for this reason
10b = Error
 ...";
CM_ SG_ 2566612990 PLedDueToDCSideCurMin "Output power is being limited due to SPN 10241 [Inverter DC Side Current] approaching or falling below the SPN 10281 [Inverter Limits Active DC Side Current Minimum].
00b = No power limit for this reason
01b = Power limited for this reason
10b = ...";
CM_ SG_ 2566612990 PLedDueToDCSideCurMax "Output power is being limited due to SPN 10241 [Inverter DC Side Current] approaching or exceeding the SPN 10280 [Inverter Limits Active DC Side Current Maximum].
00b = No power limit for this reason
01b = Power limited for this reason
10b = ...";
CM_ SG_ 2566612990 PLedDueToUndefinedReason "Output power is being limited due to an undefined reason.

00b = No power limit for this reason
01b = Power limited for this reason
10b = Error
11b = Not Available";
CM_ BO_ 2633721598 "Vehicle Fire Suppression System Module 4 Names
Reports system specific names for the VFSS module, detector zones, and release zones for Module (or system zone) 4. These names are assigned by the vehicle OEM as a part of the system configuration.";
CM_ SG_ 2633721598 ReleaseZone2Name "Descriptive name for release zone 2 of module 4.";
CM_ SG_ 2633721598 ReleaseZone1Name "Descriptive name for release zone 1 of module 4.";
CM_ SG_ 2633721598 HeatZone2Name "Descriptive name for heat zone 2 of module 4.";
CM_ SG_ 2633721598 HeatZone1Name "Descriptive name for heat zone 1 of module 4.";
CM_ SG_ 2633721598 DetectorZone8Name "Descriptive name for detector zone 8 of module 4.";
CM_ SG_ 2633721598 DetectorZone7Name "Descriptive name for detector zone 7 of module 4.";
CM_ SG_ 2633721598 DetectorZone6Name "Descriptive name for detector zone 6 of module 4.";
CM_ SG_ 2633721598 DetectorZone5Name "Descriptive name for detector zone 5 of module 4.";
CM_ SG_ 2633721598 DetectorZone4Name "Descriptive name for detector zone 4 of module 4.";
CM_ SG_ 2633721598 DetectorZone3Name "Descriptive name for detector zone 3 of module 4.";
CM_ SG_ 2633721598 DetectorZone2Name "Descriptive name for detector zone 2 of module 4.";
CM_ SG_ 2633721598 DetectorZone1Name "Descriptive name for detector zone 1 of module 4.";
CM_ SG_ 2633721598 Name "Descriptive name for the VFSS module/zone 4.";
CM_ BO_ 2633721342 "Vehicle Fire Suppression System Module 3 Names
Reports system specific names for the VFSS module, detector zones, and release zones for Module (or system zone) 3. These names are assigned by the vehicle OEM as a part of the system configuration.";
CM_ SG_ 2633721342 ReleaseZone2Name "Descriptive name for release zone 2 of module 3.";
CM_ SG_ 2633721342 ReleaseZone1Name "Descriptive name for release zone 1 of module 3.";
CM_ SG_ 2633721342 HeatZone2Name "Descriptive name for heat zone 2 of module 3.";
CM_ SG_ 2633721342 HeatZone1Name "Descriptive name for heat zone 1 of module 3.";
CM_ SG_ 2633721342 DetectorZone8Name "Descriptive name for detector zone 8 of module 3.";
CM_ SG_ 2633721342 DetectorZone7Name "Descriptive name for detector zone 7 of module 3.";
CM_ SG_ 2633721342 DetectorZone6Name "Descriptive name for detector zone 6 of module 3.";
CM_ SG_ 2633721342 DetectorZone5Name "Descriptive name for detector zone 5 of module 3.";
CM_ SG_ 2633721342 DetectorZone4Name "Descriptive name for detector zone 4 of module 3.";
CM_ SG_ 2633721342 DetectorZone3Name "Descriptive name for detector zone 3 of module 3.";
CM_ SG_ 2633721342 DetectorZone2Name "Descriptive name for detector zone 2 of module 3.";
CM_ SG_ 2633721342 DetectorZone1Name "Descriptive name for detector zone 1 of module 3.";
CM_ SG_ 2633721342 Name "Descriptive name for the VFSS module/zone 3.";
CM_ BO_ 2633721086 "Vehicle Fire Suppression System Module 2 Names
Reports system specific names for the VFSS module, detector zones, and release zones for Module (or system zone) 2. These names are assigned by the vehicle OEM as a part of the system configuration.";
CM_ SG_ 2633721086 ReleaseZone2Name "Descriptive name for release zone 2 of module 2.";
CM_ SG_ 2633721086 ReleaseZone1Name "Descriptive name for release zone 1 of module 2.";
CM_ SG_ 2633721086 HeatZone2Name "Descriptive name for heat zone 2 of module 2.";
CM_ SG_ 2633721086 HeatZone1Name "Descriptive name for heat zone 1 of module 2.";
CM_ SG_ 2633721086 DetectorZone8Name "Descriptive name for detector zone 8 of module 2.";
CM_ SG_ 2633721086 DetectorZone7Name "Descriptive name for detector zone 7 of module 2.";
CM_ SG_ 2633721086 DetectorZone6Name "Descriptive name for detector zone 6 of module 2.";
CM_ SG_ 2633721086 DetectorZone5Name "Descriptive name for detector zone 5 of module 2.";
CM_ SG_ 2633721086 DetectorZone4Name "Descriptive name for detector zone 4 of module 2.";
CM_ SG_ 2633721086 DetectorZone3Name "Descriptive name for detector zone 3 of module 2.";
CM_ SG_ 2633721086 DetectorZone2Name "Descriptive name for detector zone 2 of module 2.";
CM_ SG_ 2633721086 DetectorZone1Name "Descriptive name for detector zone 1 of module 2.";
CM_ SG_ 2633721086 Name "Descriptive name for the VFSS module/zone 2.";
CM_ BO_ 2633720830 "Vehicle Fire Suppression System Module 1 Names
Reports system specific names for the VFSS module, detector zones, and release zones for Module (or system zone) 1. These names are assigned by the vehicle OEM as a part of the system configuration.";
CM_ SG_ 2633720830 ReleaseZone2Name "Descriptive name for release zone 2 of module 1.";
CM_ SG_ 2633720830 ReleaseZone1Name "Descriptive name for release zone 1 of module 1.";
CM_ SG_ 2633720830 HeatZone2Name "Descriptive name for heat zone 2 of module 1.";
CM_ SG_ 2633720830 HeatZone1Name "Descriptive name for heat zone 1 of module 1.";
CM_ SG_ 2633720830 DetectorZone8Name "Descriptive name for detector zone 8 of module 1.";
CM_ SG_ 2633720830 DetectorZone7Name "Descriptive name for detector zone 7 of module 1.";
CM_ SG_ 2633720830 DetectorZone6Name "Descriptive name for detector zone 6 of module 1.";
CM_ SG_ 2633720830 DetectorZone5Name "Descriptive name for detector zone 5 of module 1.";
CM_ SG_ 2633720830 DetectorZone4Name "Descriptive name for detector zone 4 of module 1.";
CM_ SG_ 2633720830 DetectorZone3Name "Descriptive name for detector zone 3 of module 1.";
CM_ SG_ 2633720830 DetectorZone2Name "Descriptive name for detector zone 2 of module 1.";
CM_ SG_ 2633720830 DetectorZone1Name "Descriptive name for detector zone 1 of module 1.";
CM_ SG_ 2633720830 Name "Descriptive name for the VFSS module/zone 1.";
CM_ BO_ 2633720574 "Vehicle Fire Suppression System Module 4 Auxilliary Data
Reports the auxilliary zone supervisory values for Module (or system zone) 4.";
CM_ SG_ 2633720574 SecondPwrV "Current measured value for secondary power voltage of module 4.";
CM_ SG_ 2633720574 PrimaryPwrV "Current measured value for primary power voltage of module 4.";
CM_ SG_ 2633720574 PressSw2Data "Current measured value for pressure switch 2 of module 4.";
CM_ SG_ 2633720574 PressSw1Data "Current measured value for pressure switch 1 of module 4.";
CM_ SG_ 2633720574 ReleaseZone2Data "Current measured value for release zone 2 of module 4.";
CM_ SG_ 2633720574 ReleaseZone1Data "Current measured value for release zone 1 of module 4.";
CM_ SG_ 2633720574 HeatZone2Data "Current measured value for heat zone 2 of module 4.";
CM_ SG_ 2633720574 HeatZone1Data "Current measured value for heat zone 1 of module 4.";
CM_ BO_ 2633720318 "Vehicle Fire Suppression System Module 3 Auxilliary Data
Reports the auxilliary zone supervisory values for Module (or system zone) 3.";
CM_ SG_ 2633720318 SecondPwrV "Current measured value for secondary power voltage of module 3.";
CM_ SG_ 2633720318 PrimaryPwrV "Current measured value for primary power voltage of module 3.";
CM_ SG_ 2633720318 PressSw2Data "Current measured value for pressure switch 2 of module 3.";
CM_ SG_ 2633720318 PressSw1Data "Current measured value for pressure switch 1 of module 3.";
CM_ SG_ 2633720318 ReleaseZone2Data "Current measured value for release zone 2 of module 3.";
CM_ SG_ 2633720318 ReleaseZone1Data "Current measured value for release zone 1 of module 3.";
CM_ SG_ 2633720318 HeatZone2Data "Current measured value for heat zone 2 of module 3.";
CM_ SG_ 2633720318 HeatZone1Data "Current measured value for heat zone 1 of module 3.";
CM_ BO_ 2633720062 "Vehicle Fire Suppression System Module 2 Auxilliary Data
Reports the auxilliary zone supervisory values for Module (or system zone) 2.";
CM_ SG_ 2633720062 SecondPwrV "Current measured value for secondary power voltage of module 2.";
CM_ SG_ 2633720062 PrimaryPwrV "Current measured value for primary power voltage of module 2.";
CM_ SG_ 2633720062 PressSw2Data "Current measured value for pressure switch 2 of module 2.";
CM_ SG_ 2633720062 PressSw1Data "Current measured value for pressure switch 1 of module 2.";
CM_ SG_ 2633720062 ReleaseZone2Data "Current measured value for release zone 2 of module 2.";
CM_ SG_ 2633720062 ReleaseZone1Data "Current measured value for release zone 1 of module 2.";
CM_ SG_ 2633720062 HeatZone2Data "Current measured value for heat zone 2 of module 2.";
CM_ SG_ 2633720062 HeatZone1Data "Current measured value for heat zone 1 of module 2.";
CM_ BO_ 2633719806 "Vehicle Fire Suppression System Module 1 Auxilliary Data
Reports the auxilliary zone supervisory values for Module (or system zone) 1.";
CM_ SG_ 2633719806 SecondPwrV "Current measured value for secondary power voltage of module 1.";
CM_ SG_ 2633719806 PrimaryPwrV "Current measured value for primary power voltage of module 1.";
CM_ SG_ 2633719806 PressSw2Data "Current measured value for pressure switch 2 of module 1.";
CM_ SG_ 2633719806 PressSw1Data "Current measured value for pressure switch 1 of module 1.";
CM_ SG_ 2633719806 ReleaseZone2Data "Current measured value for release zone 2 of module 1.";
CM_ SG_ 2633719806 ReleaseZone1Data "Current measured value for release zone 1 of module 1.";
CM_ SG_ 2633719806 HeatZone2Data "Current measured value for heat zone 2 of module 1.";
CM_ SG_ 2633719806 HeatZone1Data "Current measured value for heat zone 1 of module 1.";
CM_ BO_ 2633719550 "Vehicle Fire Suppression System Module 4 Detector Data
Reports the current detector sensor values for up to 8 detectors associated to Module (or system zone) 4.   The data for each detector identifies the detector type, the detector data SLOT, and ...";
CM_ SG_ 2633719550 Detector8Data "Current measured value for detector 8 of module 4, encoded per the SAE J1939 SLOT specified in SPN 10939 (VFSS Module 4 Detector 8 Detector Data SLOT) .";
CM_ SG_ 2633719550 Detector8DetectorDataSLOT "The SAE SLOT encoding used for data reported in SPN 10871 (VFSS Module 4 Detector 8 Data) for this detector instance of this module.
0 = SAEev03 (voltage)
1 = SAEpc07 (percent)
2 = SAEtp02 (temperature)
3 = SAEpr12 (pressure)
4 = SAE reserved
 ...";
CM_ SG_ 2633719550 Detector8DetectorType "The type of detector for detector 8 of module 4.
0 = Analog thermal sensor
1 = Analog gas sensor
2 = Analog optical sensor
3 = Heat detector
4 = Manual release switch
5 = SAE Reserved
6 = SAE Reserved
7 = SAE Reserved
8 = SAE Reserved
9 = ...";
CM_ SG_ 2633719550 Detector7Data "Current measured value for detector 7 of module 4, encoded per the SAE J1939 SLOT specified in SPN 10936 (VFSS Module 4 Detector 7 Detector Data SLOT) .";
CM_ SG_ 2633719550 Detector7DetectorDataSLOT "The SAE SLOT encoding used for data reported in SPN 10871 (VFSS Module 4 Detector 7 Data) for this detector instance of this module.
0 = SAEev03 (voltage)
1 = SAEpc07 (percent)
2 = SAEtp02 (temperature)
3 = SAEpr12 (pressure)
4 = SAE reserved
 ...";
CM_ SG_ 2633719550 Detector7DetectorType "The type of detector for detector 7 of module 4.
0 = Analog thermal sensor
1 = Analog gas sensor
2 = Analog optical sensor
3 = Heat detector
4 = Manual release switch
5 = SAE Reserved
6 = SAE Reserved
7 = SAE Reserved
8 = SAE Reserved
9 = ...";
CM_ SG_ 2633719550 Detector6Data "Current measured value for detector 6 of module 4, encoded per the SAE J1939 SLOT specified in SPN 10933 (VFSS Module 4 Detector 6 Detector Data SLOT) .";
CM_ SG_ 2633719550 Detector6DetectorDataSLOT "The SAE SLOT encoding used for data reported in SPN 10871 (VFSS Module 4 Detector 6 Data) for this detector instance of this module.
0 = SAEev03 (voltage)
1 = SAEpc07 (percent)
2 = SAEtp02 (temperature)
3 = SAEpr12 (pressure)
4 = SAE reserved
 ...";
CM_ SG_ 2633719550 Detector6DetectorType "The type of detector for detector 6 of module 4.
0 = Analog thermal sensor
1 = Analog gas sensor
2 = Analog optical sensor
3 = Heat detector
4 = Manual release switch
5 = SAE Reserved
6 = SAE Reserved
7 = SAE Reserved
8 = SAE Reserved
9 = ...";
CM_ SG_ 2633719550 Detector5Data "Current measured value for detector 5 of module 4, encoded per the SAE J1939 SLOT specified in SPN 10930 (VFSS Module 4 Detector 5 Detector Data SLOT) .";
CM_ SG_ 2633719550 Detector5DetectorDataSLOT "The SAE SLOT encoding used for data reported in SPN 10871 (VFSS Module 4 Detector 5 Data) for this detector instance of this module.
0 = SAEev03 (voltage)
1 = SAEpc07 (percent)
2 = SAEtp02 (temperature)
3 = SAEpr12 (pressure)
4 = SAE reserved
 ...";
CM_ SG_ 2633719550 Detector5DetectorType "The type of detector for detector 5 of module 4.
0 = Analog thermal sensor
1 = Analog gas sensor
2 = Analog optical sensor
3 = Heat detector
4 = Manual release switch
5 = SAE Reserved
6 = SAE Reserved
7 = SAE Reserved
8 = SAE Reserved
9 = ...";
CM_ SG_ 2633719550 Detector4Data "Current measured value for detector 4 of module 4, encoded per the SAE J1939 SLOT specified in SPN 10927 (VFSS Module 4 Detector 4 Detector Data SLOT) .";
CM_ SG_ 2633719550 Detector4DetectorDataSLOT "The SAE SLOT encoding used for data reported in SPN 10871 (VFSS Module 4 Detector 4 Data) for this detector instance of this module.
0 = SAEev03 (voltage)
1 = SAEpc07 (percent)
2 = SAEtp02 (temperature)
3 = SAEpr12 (pressure)
4 = SAE reserved
 ...";
CM_ SG_ 2633719550 Detector4DetectorType "The type of detector for detector 4 of module 4.
0 = Analog thermal sensor
1 = Analog gas sensor
2 = Analog optical sensor
3 = Heat detector
4 = Manual release switch
5 = SAE Reserved
6 = SAE Reserved
7 = SAE Reserved
8 = SAE Reserved
9 = ...";
CM_ SG_ 2633719550 Detector3Data "Current measured value for detector 3 of module 4, encoded per the SAE J1939 SLOT specified in SPN 10924 (VFSS Module 4 Detector 3 Detector Data SLOT) .";
CM_ SG_ 2633719550 Detector3DetectorDataSLOT "The SAE SLOT encoding used for data reported in SPN 10871 (VFSS Module 4 Detector 3 Data) for this detector instance of this module.
0 = SAEev03 (voltage)
1 = SAEpc07 (percent)
2 = SAEtp02 (temperature)
3 = SAEpr12 (pressure)
4 = SAE reserved
 ...";
CM_ SG_ 2633719550 Detector3DetectorType "The type of detector for detector 3 of module 4.
0 = Analog thermal sensor
1 = Analog gas sensor
2 = Analog optical sensor
3 = Heat detector
4 = Manual release switch
5 = SAE Reserved
6 = SAE Reserved
7 = SAE Reserved
8 = SAE Reserved
9 = ...";
CM_ SG_ 2633719550 Detector2Data "Current measured value for detector 2 of module 4, encoded per the SAE J1939 SLOT specified in SPN 10921 (VFSS Module 4 Detector 2 Detector Data SLOT) .";
CM_ SG_ 2633719550 Detector2DetectorDataSLOT "The SAE SLOT encoding used for data reported in SPN 10871 (VFSS Module 4 Detector 2 Data) for this detector instance of this module.
0 = SAEev03 (voltage)
1 = SAEpc07 (percent)
2 = SAEtp02 (temperature)
3 = SAEpr12 (pressure)
4 = SAE reserved
 ...";
CM_ SG_ 2633719550 Detector2DetectorType "The type of detector for detector 2 of module 4.
0 = Analog thermal sensor
1 = Analog gas sensor
2 = Analog optical sensor
3 = Heat detector
4 = Manual release switch
5 = SAE Reserved
6 = SAE Reserved
7 = SAE Reserved
8 = SAE Reserved
9 = ...";
CM_ SG_ 2633719550 Detector1Data "Current measured value for detector 1 of module 4, encoded per the SAE J1939 SLOT specified in SPN 10918 (VFSS Module 4 Detector 1 Detector Data SLOT) .";
CM_ SG_ 2633719550 Detector1DetectorDataSLOT "The SAE SLOT encoding used for data reported in SPN 10871 (VFSS Module 4 Detector 1 Data) for this detector instance of this module.
0 = SAEev03 (voltage)
1 = SAEpc07 (percent)
2 = SAEtp02 (temperature)
3 = SAEpr12 (pressure)
4 = SAE reserved
 ...";
CM_ SG_ 2633719550 Detector1DetectorType "The type of detector for detector 1 of module 4.
0 = Analog thermal sensor
1 = Analog gas sensor
2 = Analog optical sensor
3 = Heat detector
4 = Manual release switch
5 = SAE Reserved
6 = SAE Reserved
7 = SAE Reserved
8 = SAE Reserved
9 = ...";
CM_ BO_ 2633719294 "Vehicle Fire Suppression System Module 3 Detector Data
Reports the current detector sensor values for up to 8 detectors associated to Module (or system zone) 3.   The data for each detector identifies the detector type, the detector data SLOT, and ...";
CM_ SG_ 2633719294 Detector8Data "Current measured value for detector 1 of module 3, encoded per the SAE J1939 SLOT specified in SPN 10915 (VFSS Module 3 Detector 18Detector Data SLOT) .";
CM_ SG_ 2633719294 Detector8DetectorDataSLOT "The SAE SLOT encoding used for data reported in SPN 10871 (VFSS Module 3 Detector 8 Data) for this detector instance of this module.
0 = SAEev03 (voltage)
1 = SAEpc07 (percent)
2 = SAEtp02 (temperature)
3 = SAEpr12 (pressure)
4 = SAE reserved
 ...";
CM_ SG_ 2633719294 Detector8DetectorType "The type of detector for detector 8 of module 3.
0 = Analog thermal sensor
1 = Analog gas sensor
2 = Analog optical sensor
3 = Heat detector
4 = Manual release switch
5 = SAE Reserved
6 = SAE Reserved
7 = SAE Reserved
8 = SAE Reserved
9 = ...";
CM_ SG_ 2633719294 Detector7Data "Current measured value for detector 7 of module 3, encoded per the SAE J1939 SLOT specified in SPN 10914 (VFSS Module 3 Detector 7 Detector Data SLOT) .";
CM_ SG_ 2633719294 Detector7DetectorDataSLOT "The SAE SLOT encoding used for data reported in SPN 10871 (VFSS Module 3 Detector 7 Data) for this detector instance of this module.
0 = SAEev03 (voltage)
1 = SAEpc07 (percent)
2 = SAEtp02 (temperature)
3 = SAEpr12 (pressure)
4 = SAE reserved
 ...";
CM_ SG_ 2633719294 Detector7DetectorType "The type of detector for detector 7 of module 3.
0 = Analog thermal sensor
1 = Analog gas sensor
2 = Analog optical sensor
3 = Heat detector
4 = Manual release switch
5 = SAE Reserved
6 = SAE Reserved
7 = SAE Reserved
8 = SAE Reserved
9 = ...";
CM_ SG_ 2633719294 Detector6Data "Current measured value for detector 6 of module 3, encoded per the SAE J1939 SLOT specified in SPN 10909 (VFSS Module 3 Detector 6 Detector Data SLOT) .";
CM_ SG_ 2633719294 Detector6DetectorDataSLOT "The SAE SLOT encoding used for data reported in SPN 10871 (VFSS Module 3 Detector 6 Data) for this detector instance of this module.
0 = SAEev03 (voltage)
1 = SAEpc07 (percent)
2 = SAEtp02 (temperature)
3 = SAEpr12 (pressure)
4 = SAE reserved
 ...";
CM_ SG_ 2633719294 Detector6DetectorType "The type of detector for detector 6 of module 3.
0 = Analog thermal sensor
1 = Analog gas sensor
2 = Analog optical sensor
3 = Heat detector
4 = Manual release switch
5 = SAE Reserved
6 = SAE Reserved
7 = SAE Reserved
8 = SAE Reserved
9 = ...";
CM_ SG_ 2633719294 Detector5Data "Current measured value for detector 5 of module 3, encoded per the SAE J1939 SLOT specified in SPN 10906 (VFSS Module 3 Detector 5 Detector Data SLOT) .";
CM_ SG_ 2633719294 Detector5DetectorDataSLOT "The SAE SLOT encoding used for data reported in SPN 10871 (VFSS Module 3 Detector 5 Data) for this detector instance of this module.
0 = SAEev03 (voltage)
1 = SAEpc07 (percent)
2 = SAEtp02 (temperature)
3 = SAEpr12 (pressure)
4 = SAE reserved
 ...";
CM_ SG_ 2633719294 Detector5DetectorType "The type of detector for detector 5 of module 3.
0 = Analog thermal sensor
1 = Analog gas sensor
2 = Analog optical sensor
3 = Heat detector
4 = Manual release switch
5 = SAE Reserved
6 = SAE Reserved
7 = SAE Reserved
8 = SAE Reserved
9 = ...";
CM_ SG_ 2633719294 Detector4Data "Current measured value for detector 4 of module 3, encoded per the SAE J1939 SLOT specified in SPN 10903 (VFSS Module 3 Detector 4 Detector Data SLOT) .";
CM_ SG_ 2633719294 Detector4DetectorDataSLOT "The SAE SLOT encoding used for data reported in SPN 10871 (VFSS Module 3 Detector 4 Data) for this detector instance of this module.
0 = SAEev03 (voltage)
1 = SAEpc07 (percent)
2 = SAEtp02 (temperature)
3 = SAEpr12 (pressure)
4 = SAE reserved
 ...";
CM_ SG_ 2633719294 Detector4DetectorType "The type of detector for detector 4 of module 3.
0 = Analog thermal sensor
1 = Analog gas sensor
2 = Analog optical sensor
3 = Heat detector
4 = Manual release switch
5 = SAE Reserved
6 = SAE Reserved
7 = SAE Reserved
8 = SAE Reserved
9 = ...";
CM_ SG_ 2633719294 Detector3Data "Current measured value for detector 3 of module 3, encoded per the SAE J1939 SLOT specified in SPN 10900 (VFSS Module 3 Detector 3 Detector Data SLOT) .";
CM_ SG_ 2633719294 Detector3DetectorDataSLOT "The SAE SLOT encoding used for data reported in SPN 10871 (VFSS Module 3 Detector 3 Data) for this detector instance of this module.
0 = SAEev03 (voltage)
1 = SAEpc07 (percent)
2 = SAEtp02 (temperature)
3 = SAEpr12 (pressure)
4 = SAE reserved
 ...";
CM_ SG_ 2633719294 Detector3DetectorType "The type of detector for detector 3 of module 3.
0 = Analog thermal sensor
1 = Analog gas sensor
2 = Analog optical sensor
3 = Heat detector
4 = Manual release switch
5 = SAE Reserved
6 = SAE Reserved
7 = SAE Reserved
8 = SAE Reserved
9 = ...";
CM_ SG_ 2633719294 Detector2Data "Current measured value for detector 2 of module 3, encoded per the SAE J1939 SLOT specified in SPN 10897 (VFSS Module 3 Detector 2 Detector Data SLOT) .";
CM_ SG_ 2633719294 Detector2DetectorDataSLOT "The SAE SLOT encoding used for data reported in SPN 10871 (VFSS Module 3 Detector 2 Data) for this detector instance of this module.
0 = SAEev03 (voltage)
1 = SAEpc07 (percent)
2 = SAEtp02 (temperature)
3 = SAEpr12 (pressure)
4 = SAE reserved
 ...";
CM_ SG_ 2633719294 Detector2DetectorType "The type of detector for detector 2 of module 3.
0 = Analog thermal sensor
1 = Analog gas sensor
2 = Analog optical sensor
3 = Heat detector
4 = Manual release switch
5 = SAE Reserved
6 = SAE Reserved
7 = SAE Reserved
8 = SAE Reserved
9 = ...";
CM_ SG_ 2633719294 Detector1Data "Current measured value for detector 1 of module 3, encoded per the SAE J1939 SLOT specified in SPN 10894 (VFSS Module 3 Detector 1 Detector Data SLOT) .";
CM_ SG_ 2633719294 Detector1DetectorDataSLOT "The SAE SLOT encoding used for data reported in SPN 10871 (VFSS Module 3 Detector 1 Data) for this detector instance of this module.
0 = SAEev03 (voltage)
1 = SAEpc07 (percent)
2 = SAEtp02 (temperature)
3 = SAEpr12 (pressure)
4 = SAE reserved
 ...";
CM_ SG_ 2633719294 Detector1DetectorType "The type of detector for detector 1 of module 3.
0 = Analog thermal sensor
1 = Analog gas sensor
2 = Analog optical sensor
3 = Heat detector
4 = Manual release switch
5 = SAE Reserved
6 = SAE Reserved
7 = SAE Reserved
8 = SAE Reserved
9 = ...";
CM_ BO_ 2633719038 "Vehicle Fire Suppression System Module 2 Detector Data
Reports the current detector sensor values for up to 8 detectors associated to Module (or system zone) 2.   The data for each detector identifies the detector type, the detector data SLOT, and ...";
CM_ SG_ 2633719038 Detector8Data "Current measured value for detector 8 of module 2, encoded per the SAE J1939 SLOT specified in SPN 10891 (VFSS Module 2 Detector 8 Detector Data SLOT) .";
CM_ SG_ 2633719038 Detector8DetectorDataSLOT "The SAE SLOT encoding used for data reported in SPN 10871 (VFSS Module 2 Detector 8 Data) for this detector instance of this module.
0 = SAEev03 (voltage)
1 = SAEpc07 (percent)
2 = SAEtp02 (temperature)
3 = SAEpr12 (pressure)
4 = SAE reserved
 ...";
CM_ SG_ 2633719038 Detector8DetectorType "The type of detector for detector 8 of module 2.
0 = Analog thermal sensor
1 = Analog gas sensor
2 = Analog optical sensor
3 = Heat detector
4 = Manual release switch
5 = SAE Reserved
6 = SAE Reserved
7 = SAE Reserved
8 = SAE Reserved
9 = ...";
CM_ SG_ 2633719038 Detector7Data "Current measured value for detector 7 of module 2, encoded per the SAE J1939 SLOT specified in SPN 10888 (VFSS Module 2 Detector 7 Detector Data SLOT) .";
CM_ SG_ 2633719038 Detector7DetectorDataSLOT "The SAE SLOT encoding used for data reported in SPN 10871 (VFSS Module 2 Detector 7 Data) for this detector instance of this module.
0 = SAEev03 (voltage)
1 = SAEpc07 (percent)
2 = SAEtp02 (temperature)
3 = SAEpr12 (pressure)
4 = SAE reserved
 ...";
CM_ SG_ 2633719038 Detector7DetectorType "The type of detector for detector 7 of module 2.
0 = Analog thermal sensor
1 = Analog gas sensor
2 = Analog optical sensor
3 = Heat detector
4 = Manual release switch
5 = SAE Reserved
6 = SAE Reserved
7 = SAE Reserved
8 = SAE Reserved
9 = ...";
CM_ SG_ 2633719038 Detector6Data "Current measured value for detector 6 of module 2, encoded per the SAE J1939 SLOT specified in SPN 10885 (VFSS Module 2 Detector 6 Detector Data SLOT) .";
CM_ SG_ 2633719038 Detector6DetectorDataSLOT "The SAE SLOT encoding used for data reported in SPN 10871 (VFSS Module 2 Detector 6 Data) for this detector instance of this module.
0 = SAEev03 (voltage)
1 = SAEpc07 (percent)
2 = SAEtp02 (temperature)
3 = SAEpr12 (pressure)
4 = SAE reserved
 ...";
CM_ SG_ 2633719038 Detector6DetectorType "The type of detector for detector 6 of module 2.
0 = Analog thermal sensor
1 = Analog gas sensor
2 = Analog optical sensor
3 = Heat detector
4 = Manual release switch
5 = SAE Reserved
6 = SAE Reserved
7 = SAE Reserved
8 = SAE Reserved
9 = ...";
CM_ SG_ 2633719038 Detector5Data "Current measured value for detector 5 of module 2, encoded per the SAE J1939 SLOT specified in SPN 10882 (VFSS Module 2 Detector 5 Detector Data SLOT) .";
CM_ SG_ 2633719038 Detector5DetectorDataSLOT "The SAE SLOT encoding used for data reported in SPN 10871 (VFSS Module 2 Detector 5 Data) for this detector instance of this module.
0 = SAEev03 (voltage)
1 = SAEpc07 (percent)
2 = SAEtp02 (temperature)
3 = SAEpr12 (pressure)
4 = SAE reserved
 ...";
CM_ SG_ 2633719038 Detector5DetectorType "The type of detector for detector 5 of module 2.
0 = Analog thermal sensor
1 = Analog gas sensor
2 = Analog optical sensor
3 = Heat detector
4 = Manual release switch
5 = SAE Reserved
6 = SAE Reserved
7 = SAE Reserved
8 = SAE Reserved
9 = ...";
CM_ SG_ 2633719038 Detector4Data "Current measured value for detector 4 of module 2, encoded per the SAE J1939 SLOT specified in SPN 10879 (VFSS Module 2 Detector 4 Detector Data SLOT) .";
CM_ SG_ 2633719038 Detector4DetectorDataSLOT "The SAE SLOT encoding used for data reported in SPN 10871 (VFSS Module 2 Detector 4 Data) for this detector instance of this module.
0 = SAEev03 (voltage)
1 = SAEpc07 (percent)
2 = SAEtp02 (temperature)
3 = SAEpr12 (pressure)
4 = SAE reserved
 ...";
CM_ SG_ 2633719038 Detector4DetectorType "The type of detector for detector 4 of module 2.
0 = Analog thermal sensor
1 = Analog gas sensor
2 = Analog optical sensor
3 = Heat detector
4 = Manual release switch
5 = SAE Reserved
6 = SAE Reserved
7 = SAE Reserved
8 = SAE Reserved
9 = ...";
CM_ SG_ 2633719038 Detector3Data "Current measured value for detector 3 of module 2, encoded per the SAE J1939 SLOT specified in SPN 10876 (VFSS Module 2 Detector 3 Detector Data SLOT) .";
CM_ SG_ 2633719038 Detector3DetectorDataSLOT "The SAE SLOT encoding used for data reported in SPN 10871 (VFSS Module 2 Detector 3 Data) for this detector instance of this module.
0 = SAEev03 (voltage)
1 = SAEpc07 (percent)
2 = SAEtp02 (temperature)
3 = SAEpr12 (pressure)
4 = SAE reserved
 ...";
CM_ SG_ 2633719038 Detector3DetectorType "The type of detector for detector 3 of module 2.
0 = Analog thermal sensor
1 = Analog gas sensor
2 = Analog optical sensor
3 = Heat detector
4 = Manual release switch
5 = SAE Reserved
6 = SAE Reserved
7 = SAE Reserved
8 = SAE Reserved
9 = ...";
CM_ SG_ 2633719038 Detector2Data "Current measured value for detector 2 of module 2, encoded per the SAE J1939 SLOT specified in SPN 10873 (VFSS Module 2 Detector 2 Detector Data SLOT) .";
CM_ SG_ 2633719038 Detector2DetectorDataSLOT "The SAE SLOT encoding used for data reported in SPN 10871 (VFSS Module 2 Detector 2 Data) for this detector instance of this module.
0 = SAEev03 (voltage)
1 = SAEpc07 (percent)
2 = SAEtp02 (temperature)
3 = SAEpr12 (pressure)
4 = SAE reserved
 ...";
CM_ SG_ 2633719038 Detector2DetectorType "The type of detector for detector 2 of module 2.
0 = Analog thermal sensor
1 = Analog gas sensor
2 = Analog optical sensor
3 = Heat detector
4 = Manual release switch
5 = SAE Reserved
6 = SAE Reserved
7 = SAE Reserved
8 = SAE Reserved
9 = ...";
CM_ SG_ 2633719038 Detector1Data "Current measured value for detector 1 of module 2, encoded per the SAE J1939 SLOT specified in SPN 10870 (VFSS Module 2 Detector 1 Detector Data SLOT) .";
CM_ SG_ 2633719038 Detector1DetectorDataSLOT "The SAE SLOT encoding used for data reported in SPN 10871 (VFSS Module 2 Detector 1 Data) for this detector instance of this module.
0 = SAEev03 (voltage)
1 = SAEpc07 (percent)
2 = SAEtp02 (temperature)
3 = SAEpr12 (pressure)
4 = SAE reserved
 ...";
CM_ SG_ 2633719038 Detector1DetectorType "The type of detector for detector 1 of module 2.
0 = Analog thermal sensor
1 = Analog gas sensor
2 = Analog optical sensor
3 = Heat detector
4 = Manual release switch
5 = SAE Reserved
6 = SAE Reserved
7 = SAE Reserved
8 = SAE Reserved
9 = ...";
CM_ BO_ 2633718782 "Vehicle Fire Suppression System Module 1 Detector Data
Reports the current detector sensor values for up to 8 detectors associated to Module (or system zone) 1.   The data for each detector identifies the detector type, the detector data SLOT, and ...";
CM_ SG_ 2633718782 Detector8Data "Current measured value for detector 8 of module 1, encoded per the SAE J1939 SLOT specified in SPN 10867 (VFSS Module 1 Detector 8 Detector Data SLOT) .";
CM_ SG_ 2633718782 Detector8DetectorDataSLOT "The SAE SLOT encoding used for data reported in SPN 10868 (VFSS Module 1 Detector 8 Data) for this detector instance of this module.
0 = SAEev03 (voltage)
1 = SAEpc07 (percent)
2 = SAEtp02 (temperature)
3 = SAEpr12 (pressure)
4 = SAE reserved
 ...";
CM_ SG_ 2633718782 Detector8DetectorType "The type of detector for detector 8 of module 1.
0 = Analog thermal sensor
1 = Analog gas sensor
2 = Analog optical sensor
3 = Heat detector
4 = Manual release switch
5 = SAE Reserved
6 = SAE Reserved
7 = SAE Reserved
8 = SAE Reserved
9 = ...";
CM_ SG_ 2633718782 Detector7Data "Current measured value for detector 7 of module 1, encoded per the SAE J1939 SLOT specified in SPN 10864 (VFSS Module 1 Detector 7 Detector Data SLOT) .";
CM_ SG_ 2633718782 Detector7DetectorDataSLOT "The SAE SLOT encoding used for data reported in SPN 10865 (VFSS Module 1 Detector 7 Data) for this detector instance of this module.
0 = SAEev03 (voltage)
1 = SAEpc07 (percent)
2 = SAEtp02 (temperature)
3 = SAEpr12 (pressure)
4 = SAE reserved
 ...";
CM_ SG_ 2633718782 Detector7DetectorType "The type of detector for detector 7 of module 1.
0 = Analog thermal sensor
1 = Analog gas sensor
2 = Analog optical sensor
3 = Heat detector
4 = Manual release switch
5 = SAE Reserved
6 = SAE Reserved
7 = SAE Reserved
8 = SAE Reserved
9 = ...";
CM_ SG_ 2633718782 Detector6Data "Current measured value for detector 6 of module 1, encoded per the SAE J1939 SLOT specified in SPN 10861 (VFSS Module 1 Detector 6 Detector Data SLOT) .";
CM_ SG_ 2633718782 Detector6DetectorDataSLOT "The SAE SLOT encoding used for data reported in SPN 10861 (VFSS Module 1 Detector 6 Data) for this detector instance of this module.
0 = SAEev03 (voltage)
1 = SAEpc07 (percent)
2 = SAEtp02 (temperature)
3 = SAEpr12 (pressure)
4 = SAE reserved
 ...";
CM_ SG_ 2633718782 Detector6DetectorType "The type of detector for detector 6 of module 1.
0 = Analog thermal sensor
1 = Analog gas sensor
2 = Analog optical sensor
3 = Heat detector
4 = Manual release switch
5 = SAE Reserved
6 = SAE Reserved
7 = SAE Reserved
8 = SAE Reserved
9 = ...";
CM_ SG_ 2633718782 Detector5Data "Current measured value for detector 5 of module 1, encoded per the SAE J1939 SLOT specified in SPN 10858 (VFSS Module 1 Detector 5 Detector Data SLOT) .";
CM_ SG_ 2633718782 Detector5DetectorDataSLOT "The SAE SLOT encoding used for data reported in SPN 10859 (VFSS Module 1 Detector 5 Data) for this detector instance of this module.
0 = SAEev03 (voltage)
1 = SAEpc07 (percent)
2 = SAEtp02 (temperature)
3 = SAEpr12 (pressure)
4 = SAE reserved
 ...";
CM_ SG_ 2633718782 Detector5DetectorType "The type of detector for detector 5 of module 1.
0 = Analog thermal sensor
1 = Analog gas sensor
2 = Analog optical sensor
3 = Heat detector
4 = Manual release switch
5 = SAE Reserved
6 = SAE Reserved
7 = SAE Reserved
8 = SAE Reserved
9 = ...";
CM_ SG_ 2633718782 Detector4Data "Current measured value for detector 4 of module 1, encoded per the SAE J1939 SLOT specified in SPN 10855 (VFSS Module 1 Detector 4 Detector Data SLOT) .";
CM_ SG_ 2633718782 Detector4DetectorDataSLOT "The SAE SLOT encoding used for data reported in SPN 10856 (VFSS Module 1 Detector 4 Data) for this detector instance of this module.
0 = SAEev03 (voltage)
1 = SAEpc07 (percent)
2 = SAEtp02 (temperature)
3 = SAEpr12 (pressure)
4 = SAE reserved
 ...";
CM_ SG_ 2633718782 Detector4DetectorType "The type of detector for detector 4 of module 1.
0 = Analog thermal sensor
1 = Analog gas sensor
2 = Analog optical sensor
3 = Heat detector
4 = Manual release switch
5 = SAE Reserved
6 = SAE Reserved
7 = SAE Reserved
8 = SAE Reserved
9 = ...";
CM_ SG_ 2633718782 Detector3Data "Current measured value for detector 3 of module 1, encoded per the SAE J1939 SLOT specified in SPN 10852 (VFSS Module 1 Detector 3 Detector Data SLOT) .";
CM_ SG_ 2633718782 Detector3DetectorDataSLOT "The SAE SLOT encoding used for data reported in SPN 10853 (VFSS Module 1 Detector 3 Data) for this detector instance of this module.
0 = SAEev03 (voltage)
1 = SAEpc07 (percent)
2 = SAEtp02 (temperature)
3 = SAEpr12 (pressure)
4 = SAE reserved
 ...";
CM_ SG_ 2633718782 Detector3DetectorType "The type of detector for detector 3 of module 1.
0 = Analog thermal sensor
1 = Analog gas sensor
2 = Analog optical sensor
3 = Heat detector
4 = Manual release switch
5 = SAE Reserved
6 = SAE Reserved
7 = SAE Reserved
8 = SAE Reserved
9 = ...";
CM_ SG_ 2633718782 Detector2Data "Current measured value for detector 1 of module 2, encoded per the SAE J1939 SLOT specified in SPN 10849 (VFSS Module 1 Detector 2 Detector Data SLOT) .";
CM_ SG_ 2633718782 Detector2DetectorDataSLOT "The SAE SLOT encoding used for data reported in SPN 10848 (VFSS Module 1 Detector 2 Data) for this detector instance of this module.
0 = SAEev03 (voltage)
1 = SAEpc07 (percent)
2 = SAEtp02 (temperature)
3 = SAEpr12 (pressure)
4 = SAE reserved
 ...";
CM_ SG_ 2633718782 Detector2DetectorType "The type of detector for detector 2 of module 1.
0 = Analog thermal sensor
1 = Analog gas sensor
2 = Analog optical sensor
3 = Heat detector
4 = Manual release switch
5 = SAE Reserved
6 = SAE Reserved
7 = SAE Reserved
8 = SAE Reserved
9 = ...";
CM_ SG_ 2633718782 Detector1Data "Current measured value for detector 1 of module 1, encoded per the SAE J1939 SLOT specified in SPN 10846 (VFSS Module 1 Detector 1 Detector Data SLOT) .";
CM_ SG_ 2633718782 Detector1DetectorDataSLOT "The SAE SLOT encoding used for data reported in SPN 10847 (VFSS Module 1 Detector 1 Data) for this detector instance of this module.
0 = SAEev03 (voltage)
1 = SAEpc07 (percent)
2 = SAEtp02 (temperature)
3 = SAEpr12 (pressure)
4 = SAE reserved
 ...";
CM_ SG_ 2633718782 Detector1DetectorType "The type of detector for detector 1 of module 1.
0 = Analog thermal sensor
1 = Analog gas sensor
2 = Analog optical sensor
3 = Heat detector
4 = Manual release switch
5 = SAE Reserved
6 = SAE Reserved
7 = SAE Reserved
8 = SAE Reserved
9 = ...";
CM_ BO_ 2566609662 "High Voltage Energy Storage Pack 1 Configuration
Configuration data for High Voltage Energy Storage Pack 1.  Note that configuration data should not dynamically change during vehicle operation.";
CM_ SG_ 2566609662 NomRatedCapacity "Per the HVES manufacturer, this is the manufacturer's nominal rated capacity of this instance of the energy storage system.  The rated capacity does not change over the life of the HVES.
This parameter is for one of multiple packs in an HVESS.  If ...";
CM_ SG_ 2566609662 CellMinVLmt "Per the HVES manufacturer, this is the minimum cell voltage for this High Voltage Energy Storage Pack instance operation.  Operating below this value may damage HVES hardware, or compromise HVES life.
This parameter is for one of multiple packs in ...";
CM_ SG_ 2566609662 CellMaxVLmt "Per the HVES manufacturer, this is the maximum cell voltage for this High Voltage Energy Storage Pack instance operation.  Operating above this value may damage HVES hardware, or compromise HVES life.
This parameter is for one of multiple packs in ...";
CM_ SG_ 2566609662 RecommendedMinOperatingTemp "Per the HVES manufacturer, this is the recommended minimum temperature for this High Voltage Energy Storage Pack instance operation.  Operating below this value may damage HVES hardware, or compromise HVES life.
This parameter is for one of ...";
CM_ SG_ 2566609662 RecommendedMaxOperatingTemp "Per the HVES manufacturer, this is the recommended maximum temperature for this High Voltage Energy Storage Pack instance operation.  Operating above this value may damage HVES hardware, or compromise HVES life.
This parameter is for one of ...";
CM_ SG_ 2566609662 RecommendedMaxStOfCharge "Per the HVES manufacturer, this is the recommended maximum state of charge for this High Voltage Energy Storage Pack instance operation.  Operating above this value may compromise HVES life.
This parameter is for one of multiple packs in an HVESS ...";
CM_ SG_ 2566609662 RecommendedMinStOfCharge "Per the HVES manufacturer, this is the recommended minimum state of charge for this High Voltage Energy Storage Pack instance operation.  Operating below this value may compromise HVES life.
This parameter is for one of multiple packs in an HVESS ...";
CM_ SG_ 2566609662 RecommendedMaxOperatingV "Per the HVES manufacturer, this is the maximum recommended voltage level for this High Voltage Energy Storage Pack instance operation.  Operating above this value may compromise HVES life.
This parameter is for one of multiple packs in an HVESS ...";
CM_ SG_ 2566609662 RecommendedMinOperatingV "Per the HVES manufacturer, this is the minimum recommended voltage level for this High Voltage Energy Storage Pack instance operation.  Operating below this value may compromise HVES life.
This parameter is for one of multiple packs in an HVESS ...";
CM_ SG_ 2566609662 NomV "Per the HVES manufacturer, this is the nominal operating voltage of this High Voltage Energy Storage Pack instance, e.g. “300V” or “600V”.
This parameter is for one of multiple packs in an HVESS.  If there is only one pack in the system, the HVESS ...";
CM_ BO_ 2633718270 "High Voltage Energy Storage Pack 1 History
Historical data for High Voltage Energy Storage Pack 1.";
CM_ SG_ 2633718270 TotalEnergyOut "The cumulative energy which has flowed out of this High Voltage Energy Storage Pack instance over the lifetime of the battery pack. This parameter is the sum of the Energy out of this HVES instance. This value is reset when the pack is replaced. For ...";
CM_ SG_ 2633718270 TotalEnergyInput "The cumulative energy which has flowed into this High Voltage Energy Storage Pack instance over the lifetime of the battery pack. This parameter is the sum of the Energy into this HVES instance.
This value is reset when the pack is replaced. For ...";
CM_ SG_ 2633718270 TotalAccumulatedCharge "The total accumulated amp hours which have flowed through this High Voltage Energy Storage Pack instance.  This parameter is the sum of the absolute values of the Ampere hours into and out of this HVES instance.
This parameter is for one of ...";
CM_ SG_ 2633718270 TotalEnergyThroughput "The total energy throughput which has flowed through this High Voltage Energy Storage Pack instance.  This parameter is the sum of the absolute values of the Energy into and out of this HVES instance.
This parameter is for one of multiple packs in ...";
CM_ SG_ 2633718270 ContactorOpenUnderLoadCount "This signal represents the number of times the contactors inside this High Voltage Energy Storage Pack instance have opened while current is flowing through them.  The current level (that determines if an opening event will be counted) shall be ...";
CM_ SG_ 2633718270 StOfHealth "This signal represents the expected remaining \"Life\" of this High Voltage Energy Storage Pack instance, in percent.  Battery life is a manufacturer-specific measure of how well the energy storage system is functioning relative to its nominal (rated) ...";
CM_ BO_ 2566609150 "High Voltage Energy Storage Pack 2 Configuration
Configuration data for High Voltage Energy Storage Pack 2.  Note that configuration data should not dynamically change during vehicle operation.";
CM_ SG_ 2566609150 NomRatedCapacity "Per the HVES manufacturer, this is the manufacturer's nominal rated capacity of this instance of the energy storage system.  The rated capacity does not change over the life of the HVES.
This parameter is for one of multiple packs in an HVESS.  If ...";
CM_ SG_ 2566609150 CellMinVLmt "Per the HVES manufacturer, this is the minimum cell voltage for this High Voltage Energy Storage Pack instance operation.  Operating below this value may damage HVES hardware, or compromise HVES life.
This parameter is for one of multiple packs in ...";
CM_ SG_ 2566609150 CellMaxVLmt "Per the HVES manufacturer, this is the maximum cell voltage for this High Voltage Energy Storage Pack instance operation.  Operating above this value may damage HVES hardware, or compromise HVES life.
This parameter is for one of multiple packs in ...";
CM_ SG_ 2566609150 RecommendedMinOperatingTemp "Per the HVES manufacturer, this is the recommended minimum temperature for this High Voltage Energy Storage Pack instance operation.  Operating below this value may damage HVES hardware, or compromise HVES life.
This parameter is for one of ...";
CM_ SG_ 2566609150 RecommendedMaxOperatingTemp "Per the HVES manufacturer, this is the recommended maximum temperature for this High Voltage Energy Storage Pack instance operation.  Operating above this value may damage HVES hardware, or compromise HVES life.
This parameter is for one of ...";
CM_ SG_ 2566609150 RecommendedMaxStOfCharge "Per the HVES manufacturer, this is the recommended maximum state of charge for this High Voltage Energy Storage Pack instance operation.  Operating above this value may compromise HVES life.
This parameter is for one of multiple packs in an HVESS ...";
CM_ SG_ 2566609150 RecommendedMinStOfCharge "Per the HVES manufacturer, this is the recommended minimum state of charge for this High Voltage Energy Storage Pack instance operation.  Operating below this value may compromise HVES life.
This parameter is for one of multiple packs in an HVESS ...";
CM_ SG_ 2566609150 RecommendedMaxOperatingV "Per the HVES manufacturer, this is the maximum recommended voltage level for this High Voltage Energy Storage Pack instance operation.  Operating above this value may compromise HVES life.
This parameter is for one of multiple packs in an HVESS ...";
CM_ SG_ 2566609150 RecommendedMinOperatingV "Per the HVES manufacturer, this is the minimum recommended voltage level for this High Voltage Energy Storage Pack instance operation.  Operating below this value may compromise HVES life.
This parameter is for one of multiple packs in an HVESS ...";
CM_ SG_ 2566609150 NomV "Per the HVES manufacturer, this is the nominal operating voltage of this High Voltage Energy Storage Pack instance, e.g. “300V” or “600V”.
This parameter is for one of multiple packs in an HVESS.  If there is only one pack in the system, the HVESS ...";
CM_ BO_ 2633717758 "High Voltage Energy Storage Pack 2 History
Historical data for High Voltage Energy Storage Pack 2.";
CM_ SG_ 2633717758 TotalEnergyOut "The cumulative energy which has flowed out of this High Voltage Energy Storage Pack instance over the lifetime of the battery pack. This parameter is the sum of the Energy out of this HVES instance. This value is reset when the pack is replaced. For ...";
CM_ SG_ 2633717758 TotalEnergyInput "The cumulative energy which has flowed into this High Voltage Energy Storage Pack instance over the lifetime of the battery pack. This parameter is the sum of the Energy into this HVES instance.
This value is reset when the pack is replaced. For ...";
CM_ SG_ 2633717758 TotalAccumulatedCharge "The total accumulated amp hours which have flowed through this High Voltage Energy Storage Pack instance.  This parameter is the sum of the absolute values of the Ampere hours into and out of this HVES instance.
This parameter is for one of ...";
CM_ SG_ 2633717758 TotalEnergyThroughput "The total energy throughput which has flowed through this High Voltage Energy Storage Pack instance.  This parameter is the sum of the absolute values of the Energy into and out of this HVES instance.
This parameter is for one of multiple packs in ...";
CM_ SG_ 2633717758 ContactorOpenUnderLoadCount "This signal represents the number of times the contactors inside this High Voltage Energy Storage Pack instance have opened while current is flowing through them.  The current level (that determines if an opening event will be counted) shall be ...";
CM_ SG_ 2633717758 StOfHealth "This signal represents the expected remaining \"Life\" of this High Voltage Energy Storage Pack instance, in percent.  Battery life is a manufacturer-specific measure of how well the energy storage system is functioning relative to its nominal (rated) ...";
CM_ BO_ 2566608638 "High Voltage Energy Storage Pack 3 Configuration
Configuration data for High Voltage Energy Storage Pack 3.  Note that configuration data should not dynamically change during vehicle operation.";
CM_ SG_ 2566608638 NomRatedCapacity "Per the HVES manufacturer, this is the manufacturer's nominal rated capacity of this instance of the energy storage system.  The rated capacity does not change over the life of the HVES.
This parameter is for one of multiple packs in an HVESS.  If ...";
CM_ SG_ 2566608638 CellMinVLmt "Per the HVES manufacturer, this is the minimum cell voltage for this High Voltage Energy Storage Pack instance operation.  Operating below this value may damage HVES hardware, or compromise HVES life.
This parameter is for one of multiple packs in ...";
CM_ SG_ 2566608638 CellMaxVLmt "Per the HVES manufacturer, this is the maximum cell voltage for this High Voltage Energy Storage Pack instance operation.  Operating above this value may damage HVES hardware, or compromise HVES life.
This parameter is for one of multiple packs in ...";
CM_ SG_ 2566608638 RecommendedMinOperatingTemp "Per the HVES manufacturer, this is the recommended minimum temperature for this High Voltage Energy Storage Pack instance operation.  Operating below this value may damage HVES hardware, or compromise HVES life.
This parameter is for one of ...";
CM_ SG_ 2566608638 RecommendedMaxOperatingTemp "Per the HVES manufacturer, this is the recommended maximum temperature for this High Voltage Energy Storage Pack instance operation.  Operating above this value may damage HVES hardware, or compromise HVES life.
This parameter is for one of ...";
CM_ SG_ 2566608638 RecommendedMaxStOfCharge "Per the HVES manufacturer, this is the recommended maximum state of charge for this High Voltage Energy Storage Pack instance operation.  Operating above this value may compromise HVES life.
This parameter is for one of multiple packs in an HVESS ...";
CM_ SG_ 2566608638 RecommendedMinStOfCharge "Per the HVES manufacturer, this is the recommended minimum state of charge for this High Voltage Energy Storage Pack instance operation.  Operating below this value may compromise HVES life.
This parameter is for one of multiple packs in an HVESS ...";
CM_ SG_ 2566608638 RecommendedMaxOperatingV "Per the HVES manufacturer, this is the maximum recommended voltage level for this High Voltage Energy Storage Pack instance operation.  Operating above this value may compromise HVES life.
This parameter is for one of multiple packs in an HVESS ...";
CM_ SG_ 2566608638 RecommendedMinOperatingV "Per the HVES manufacturer, this is the minimum recommended voltage level for this High Voltage Energy Storage Pack instance operation.  Operating below this value may compromise HVES life.
This parameter is for one of multiple packs in an HVESS ...";
CM_ SG_ 2566608638 NomV "Per the HVES manufacturer, this is the nominal operating voltage of this High Voltage Energy Storage Pack instance, e.g. “300V” or “600V”.
This parameter is for one of multiple packs in an HVESS.  If there is only one pack in the system, the HVESS ...";
CM_ BO_ 2633717246 "High Voltage Energy Storage Pack 3 History
Historical data for High Voltage Energy Storage Pack 3.";
CM_ SG_ 2633717246 TotalEnergyOut "The cumulative energy which has flowed out of this High Voltage Energy Storage Pack instance over the lifetime of the battery pack. This parameter is the sum of the Energy out of this HVES instance. This value is reset when the pack is replaced. For ...";
CM_ SG_ 2633717246 TotalEnergyInput "The cumulative energy which has flowed into this High Voltage Energy Storage Pack instance over the lifetime of the battery pack. This parameter is the sum of the Energy into this HVES instance.
This value is reset when the pack is replaced. For ...";
CM_ SG_ 2633717246 TotalAccumulatedCharge "The total accumulated amp hours which have flowed through this High Voltage Energy Storage Pack instance.  This parameter is the sum of the absolute values of the Ampere hours into and out of this HVES instance.
This parameter is for one of ...";
CM_ SG_ 2633717246 TotalEnergyThroughput "The total energy throughput which has flowed through this High Voltage Energy Storage Pack instance.  This parameter is the sum of the absolute values of the Energy into and out of this HVES instance.
This parameter is for one of multiple packs in ...";
CM_ SG_ 2633717246 ContactorOpenUnderLoadCount "This signal represents the number of times the contactors inside this High Voltage Energy Storage Pack instance have opened while current is flowing through them.  The current level (that determines if an opening event will be counted) shall be ...";
CM_ SG_ 2633717246 StOfHealth "This signal represents the expected remaining \"Life\" of this High Voltage Energy Storage Pack instance, in percent.  Battery life is a manufacturer-specific measure of how well the energy storage system is functioning relative to its nominal (rated) ...";
CM_ BO_ 2566608126 "High Voltage Energy Storage Pack 4 Configuration
Configuration data for High Voltage Energy Storage Pack 4.  Note that configuration data should not dynamically change during vehicle operation.";
CM_ SG_ 2566608126 NomRatedCapacity "Per the HVES manufacturer, this is the manufacturer's nominal rated capacity of this instance of the energy storage system.  The rated capacity does not change over the life of the HVES.
This parameter is for one of multiple packs in an HVESS.  If ...";
CM_ SG_ 2566608126 CellMinVLmt "Per the HVES manufacturer, this is the minimum cell voltage for this High Voltage Energy Storage Pack instance operation.  Operating below this value may damage HVES hardware, or compromise HVES life.
This parameter is for one of multiple packs in ...";
CM_ SG_ 2566608126 CellMaxVLmt "Per the HVES manufacturer, this is the maximum cell voltage for this High Voltage Energy Storage Pack instance operation.  Operating above this value may damage HVES hardware, or compromise HVES life.
This parameter is for one of multiple packs in ...";
CM_ SG_ 2566608126 RecommendedMinOperatingTemp "Per the HVES manufacturer, this is the recommended minimum temperature for this High Voltage Energy Storage Pack instance operation.  Operating below this value may damage HVES hardware, or compromise HVES life.
This parameter is for one of ...";
CM_ SG_ 2566608126 RecommendedMaxOperatingTemp "Per the HVES manufacturer, this is the recommended maximum temperature for this High Voltage Energy Storage Pack instance operation.  Operating above this value may damage HVES hardware, or compromise HVES life.
This parameter is for one of ...";
CM_ SG_ 2566608126 RecommendedMaxStOfCharge "Per the HVES manufacturer, this is the recommended maximum state of charge for this High Voltage Energy Storage Pack instance operation.  Operating above this value may compromise HVES life.
This parameter is for one of multiple packs in an HVESS ...";
CM_ SG_ 2566608126 RecommendedMinStOfCharge "Per the HVES manufacturer, this is the recommended minimum state of charge for this High Voltage Energy Storage Pack instance operation.  Operating below this value may compromise HVES life.
This parameter is for one of multiple packs in an HVESS ...";
CM_ SG_ 2566608126 RecommendedMaxOperatingV "Per the HVES manufacturer, this is the maximum recommended voltage level for this High Voltage Energy Storage Pack instance operation.  Operating above this value may compromise HVES life.
This parameter is for one of multiple packs in an HVESS ...";
CM_ SG_ 2566608126 RecommendedMinOperatingV "Per the HVES manufacturer, this is the minimum recommended voltage level for this High Voltage Energy Storage Pack instance operation.  Operating below this value may compromise HVES life.
This parameter is for one of multiple packs in an HVESS ...";
CM_ SG_ 2566608126 NomV "Per the HVES manufacturer, this is the nominal operating voltage of this High Voltage Energy Storage Pack instance, e.g. “300V” or “600V”.
This parameter is for one of multiple packs in an HVESS.  If there is only one pack in the system, the HVESS ...";
CM_ BO_ 2633716734 "High Voltage Energy Storage Pack 4 History
Historical data for High Voltage Energy Storage Pack 4.";
CM_ SG_ 2633716734 TotalEnergyOut "The cumulative energy which has flowed out of this High Voltage Energy Storage Pack instance over the lifetime of the battery pack. This parameter is the sum of the Energy out of this HVES instance. This value is reset when the pack is replaced. For ...";
CM_ SG_ 2633716734 TotalEnergyInput "The cumulative energy which has flowed into this High Voltage Energy Storage Pack instance over the lifetime of the battery pack. This parameter is the sum of the Energy into this HVES instance.
This value is reset when the pack is replaced. For ...";
CM_ SG_ 2633716734 TotalAccumulatedCharge "The total accumulated amp hours which have flowed through this High Voltage Energy Storage Pack instance.  This parameter is the sum of the absolute values of the Ampere hours into and out of this HVES instance.
This parameter is for one of ...";
CM_ SG_ 2633716734 TotalEnergyThroughput "The total energy throughput which has flowed through this High Voltage Energy Storage Pack instance.  This parameter is the sum of the absolute values of the Energy into and out of this HVES instance.
This parameter is for one of multiple packs in ...";
CM_ SG_ 2633716734 ContactorOpenUnderLoadCount "This signal represents the number of times the contactors inside this High Voltage Energy Storage Pack instance have opened while current is flowing through them.  The current level (that determines if an opening event will be counted) shall be ...";
CM_ SG_ 2633716734 StOfHealth "This signal represents the expected remaining \"Life\" of this High Voltage Energy Storage Pack instance, in percent.  Battery life is a manufacturer-specific measure of how well the energy storage system is functioning relative to its nominal (rated) ...";
CM_ BO_ 2566607614 "High Voltage Energy Storage Pack 5 Configuration
Configuration data for High Voltage Energy Storage Pack 5.  Note that configuration data should not dynamically change during vehicle operation.";
CM_ SG_ 2566607614 NomRatedCapacity "Per the HVES manufacturer, this is the manufacturer's nominal rated capacity of this instance of the energy storage system.  The rated capacity does not change over the life of the HVES.
This parameter is for one of multiple packs in an HVESS.  If ...";
CM_ SG_ 2566607614 CellMinVLmt "Per the HVES manufacturer, this is the minimum cell voltage for this High Voltage Energy Storage Pack instance operation.  Operating below this value may damage HVES hardware, or compromise HVES life.
This parameter is for one of multiple packs in ...";
CM_ SG_ 2566607614 CellMaxVLmt "Per the HVES manufacturer, this is the maximum cell voltage for this High Voltage Energy Storage Pack instance operation.  Operating above this value may damage HVES hardware, or compromise HVES life.
This parameter is for one of multiple packs in ...";
CM_ SG_ 2566607614 RecommendedMinOperatingTemp "Per the HVES manufacturer, this is the recommended minimum temperature for this High Voltage Energy Storage Pack instance operation.  Operating below this value may damage HVES hardware, or compromise HVES life.
This parameter is for one of ...";
CM_ SG_ 2566607614 RecommendedMaxOperatingTemp "Per the HVES manufacturer, this is the recommended maximum temperature for this High Voltage Energy Storage Pack instance operation.  Operating above this value may damage HVES hardware, or compromise HVES life.
This parameter is for one of ...";
CM_ SG_ 2566607614 RecommendedMaxStOfCharge "Per the HVES manufacturer, this is the recommended maximum state of charge for this High Voltage Energy Storage Pack instance operation.  Operating above this value may compromise HVES life.
This parameter is for one of multiple packs in an HVESS ...";
CM_ SG_ 2566607614 RecommendedMinStOfCharge "Per the HVES manufacturer, this is the recommended minimum state of charge for this High Voltage Energy Storage Pack instance operation.  Operating below this value may compromise HVES life.
This parameter is for one of multiple packs in an HVESS ...";
CM_ SG_ 2566607614 RecommendedMaxOperatingV "Per the HVES manufacturer, this is the maximum recommended voltage level for this High Voltage Energy Storage Pack instance operation.  Operating above this value may compromise HVES life.
This parameter is for one of multiple packs in an HVESS ...";
CM_ SG_ 2566607614 RecommendedMinOperatingV "Per the HVES manufacturer, this is the minimum recommended voltage level for this High Voltage Energy Storage Pack instance operation.  Operating below this value may compromise HVES life.
This parameter is for one of multiple packs in an HVESS ...";
CM_ SG_ 2566607614 NomV "Per the HVES manufacturer, this is the nominal operating voltage of this High Voltage Energy Storage Pack instance, e.g. “300V” or “600V”.
This parameter is for one of multiple packs in an HVESS.  If there is only one pack in the system, the HVESS ...";
CM_ BO_ 2633716222 "High Voltage Energy Storage Pack 5 History
Historical data for High Voltage Energy Storage Pack 5.";
CM_ SG_ 2633716222 TotalEnergyOut "The cumulative energy which has flowed out of this High Voltage Energy Storage Pack instance over the lifetime of the battery pack. This parameter is the sum of the Energy out of this HVES instance. This value is reset when the pack is replaced. For ...";
CM_ SG_ 2633716222 TotalEnergyInput "The cumulative energy which has flowed into this High Voltage Energy Storage Pack instance over the lifetime of the battery pack. This parameter is the sum of the Energy into this HVES instance.
This value is reset when the pack is replaced. For ...";
CM_ SG_ 2633716222 TotalAccumulatedCharge "The total accumulated amp hours which have flowed through this High Voltage Energy Storage Pack instance.  This parameter is the sum of the absolute values of the Ampere hours into and out of this HVES instance.
This parameter is for one of ...";
CM_ SG_ 2633716222 TotalEnergyThroughput "The total energy throughput which has flowed through this High Voltage Energy Storage Pack instance.  This parameter is the sum of the absolute values of the Energy into and out of this HVES instance.
This parameter is for one of multiple packs in ...";
CM_ SG_ 2633716222 ContactorOpenUnderLoadCount "This signal represents the number of times the contactors inside this High Voltage Energy Storage Pack instance have opened while current is flowing through them.  The current level (that determines if an opening event will be counted) shall be ...";
CM_ SG_ 2633716222 StOfHealth "This signal represents the expected remaining \"Life\" of this High Voltage Energy Storage Pack instance, in percent.  Battery life is a manufacturer-specific measure of how well the energy storage system is functioning relative to its nominal (rated) ...";
CM_ BO_ 2566607102 "High Voltage Energy Storage Pack 6 Configuration
Configuration data for High Voltage Energy Storage Pack 6.  Note that configuration data should not dynamically change during vehicle operation.";
CM_ SG_ 2566607102 NomRatedCapacity "Per the HVES manufacturer, this is the manufacturer's nominal rated capacity of this instance of the energy storage system.  The rated capacity does not change over the life of the HVES.
This parameter is for one of multiple packs in an HVESS.  If ...";
CM_ SG_ 2566607102 CellMinVLmt "Per the HVES manufacturer, this is the minimum cell voltage for this High Voltage Energy Storage Pack instance operation.  Operating below this value may damage HVES hardware, or compromise HVES life.
This parameter is for one of multiple packs in ...";
CM_ SG_ 2566607102 CellMaxVLmt "Per the HVES manufacturer, this is the maximum cell voltage for this High Voltage Energy Storage Pack instance operation.  Operating above this value may damage HVES hardware, or compromise HVES life.
This parameter is for one of multiple packs in ...";
CM_ SG_ 2566607102 RecommendedMinOperatingTemp "Per the HVES manufacturer, this is the recommended minimum temperature for this High Voltage Energy Storage Pack instance operation.  Operating below this value may damage HVES hardware, or compromise HVES life.
This parameter is for one of ...";
CM_ SG_ 2566607102 RecommendedMaxOperatingTemp "Per the HVES manufacturer, this is the recommended maximum temperature for this High Voltage Energy Storage Pack instance operation.  Operating above this value may damage HVES hardware, or compromise HVES life.
This parameter is for one of ...";
CM_ SG_ 2566607102 RecommendedMaxStOfCharge "Per the HVES manufacturer, this is the recommended maximum state of charge for this High Voltage Energy Storage Pack instance operation.  Operating above this value may compromise HVES life.
This parameter is for one of multiple packs in an HVESS ...";
CM_ SG_ 2566607102 RecommendedMinStOfCharge "Per the HVES manufacturer, this is the recommended minimum state of charge for this High Voltage Energy Storage Pack instance operation.  Operating below this value may compromise HVES life.
This parameter is for one of multiple packs in an HVESS ...";
CM_ SG_ 2566607102 RecommendedMaxOperatingV "Per the HVES manufacturer, this is the maximum recommended voltage level for this High Voltage Energy Storage Pack instance operation.  Operating above this value may compromise HVES life.
This parameter is for one of multiple packs in an HVESS ...";
CM_ SG_ 2566607102 RecommendedMinOperatingV "Per the HVES manufacturer, this is the minimum recommended voltage level for this High Voltage Energy Storage Pack instance operation.  Operating below this value may compromise HVES life.
This parameter is for one of multiple packs in an HVESS ...";
CM_ SG_ 2566607102 NomV "Per the HVES manufacturer, this is the nominal operating voltage of this High Voltage Energy Storage Pack instance, e.g. “300V” or “600V”.
This parameter is for one of multiple packs in an HVESS.  If there is only one pack in the system, the HVESS ...";
CM_ BO_ 2633715710 "High Voltage Energy Storage Pack 6 History
Historical data for High Voltage Energy Storage Pack 6.";
CM_ SG_ 2633715710 TotalEnergyOut "The cumulative energy which has flowed out of this High Voltage Energy Storage Pack instance over the lifetime of the battery pack. This parameter is the sum of the Energy out of this HVES instance. This value is reset when the pack is replaced. For ...";
CM_ SG_ 2633715710 TotalEnergyInput "The cumulative energy which has flowed into this High Voltage Energy Storage Pack instance over the lifetime of the battery pack. This parameter is the sum of the Energy into this HVES instance.  This value is reset when the pack is replaced. For ...";
CM_ SG_ 2633715710 TotalAccumulatedCharge "The total accumulated amp hours which have flowed through this High Voltage Energy Storage Pack instance.  This parameter is the sum of the absolute values of the Ampere hours into and out of this HVES instance.
This parameter is for one of ...";
CM_ SG_ 2633715710 TotalEnergyThroughput "The total energy throughput which has flowed through this High Voltage Energy Storage Pack instance.  This parameter is the sum of the absolute values of the Energy into and out of this HVES instance.
This parameter is for one of multiple packs in ...";
CM_ SG_ 2633715710 ContactorOpenUnderLoadCount "This signal represents the number of times the contactors inside this High Voltage Energy Storage Pack instance have opened while current is flowing through them.  The current level (that determines if an opening event will be counted) shall be ...";
CM_ SG_ 2633715710 StOfHealth "This signal represents the expected remaining \"Life\" of this High Voltage Energy Storage Pack instance, in percent.  Battery life is a manufacturer-specific measure of how well the energy storage system is functioning relative to its nominal (rated) ...";
CM_ BO_ 2499497726 "Hoist Control Information
Hoist operation commands from the hoist lever which defines the operator intended hoist operation.";
CM_ SG_ 2499497726 LeverDetentPosStatus "The status of the hoist lever (used for a dump body) in the detent position for either direction of travel.  

00b = Not in the Detent Position
01b = In the Detent Position
10b = Error Indicator
11b = Not Available";
CM_ SG_ 2499497726 LeverPos "The position of the operator's hoist control lever (used for a dump body) relative to travel from a neutral (center) position.
Position value of 0 indicates the lever is in the neutral (central) position where no hoist movement is requested ...";
CM_ BO_ 2566606334 "Maintenance Information
Used to transmit maintenance information of a machine.";
CM_ SG_ 2566606334 TransOIlFilterLifeRemaining "Signal which indicates an actual life remaining in percent of the transmission oil filter.  0% represents no life remaining in the filter and 100% represents a new filter with full life remaining.";
CM_ SG_ 2566606334 EngOilFilterLifeRemaining "Signal which indicates an actual life remaining in percent of the engine oil filter.  0% represents no life remaining in the filter and 100% represents a new filter with full life remaining.";
CM_ SG_ 2566606334 EngFuelFilterLifeRemaining11742 "Signal which indicates an actual life remaining in percent of the engine suction side fuel filter.  0% represents no life remaining in the filter and 100% represents a new filter with full life remaining.";
CM_ SG_ 2566606334 EngFuelFilterLifeRemaining "Signal which indicates an actual life remaining in percent of the engine fuel filter.  0% represents no life remaining in the filter and 100% represents a new filter with full life remaining.";
CM_ SG_ 2566606334 EngAirFilter4LifeRemaining "Signal which indicates an actual life remaining in percent of the engine air filter #4. 0% represents no life remaining in the filter and 100% represents a new filter with full life remaining.";
CM_ SG_ 2566606334 EngAirFilter3LifeRemaining "Signal which indicates an actual life remaining in percent of the engine air filter #3. 0% represents no life remaining in the filter and 100% represents a new filter with full life remaining.";
CM_ SG_ 2566606334 EngAirFilter2LifeRemaining "Signal which indicates an actual life remaining in percent of the engine air filter #2. 0% represents no life remaining in the filter and 100% represents a new filter with full life remaining.";
CM_ SG_ 2566606334 EngAirFilter1LifeRemaining "Signal which indicates an actual life remaining in percent of the engine air filter #1. 0% represents no life remaining in the filter and 100% represents a new filter with full life remaining.";
CM_ BO_ 2566606078 "Cab Climate System Information 2
This message contains measurement and condition information from cab HVAC components.";
CM_ SG_ 2566606078 A_CCompressorPwr "Electrical power consumed by the Cab A/C Compressor.";
CM_ SG_ 2566606078 HtrPwr "Electrical power consumed by the cab heater.";
CM_ BO_ 2566605822 "Automated Driving System Status 1
Sent by a controller application which is under control of an automated driving system.";
CM_ SG_ 2566605822 VSCtrlOpSt "Used to indicate the operation status of the application responding to the ADS Vehicle Speed Control Command (SPN 15248).
000b = ADS Vehicle Speed Control Command Not Active
001b = Maximum Positive Torque
010b = Normal Mode
011b = Maximum ...";
CM_ SG_ 2566605822 VSCtrlCmdFeedback "This parameter represents the current vehicle speed commanded by the automated driving system (ADS) via ADS Vehicle Speed Control Command (SPN 15248).

Note: 0xFB00 denotes no ADS Vehicle Speed Control is being commanded.";
CM_ SG_ 2566605822 SAOfCtrlDeviceForVehSpdCtrlCmd "The receiving application is currently acting upon the ADS Vehicle Speed Control Command (SPN 15248) of the automated driving system (ADS) from this source address.
Note:
254 (FEh) indicates this parameter is supported, but ADS Vehicle Speed ...";
CM_ SG_ 2566605822 VSCtrlCmdReadinessStatus "Used to indicate the recipient's state of readiness for responding to ADS Vehicle Speed Control Command (SPN 15248) of the automated driving system (ADS).

00b = Not Ready
01b = Ready
10b = Error
11b = Not Available";
CM_ SG_ 2566605822 TSC1CtrlPurpP7ReadinessStatus "This parameter is used to indicate an application's state of readiness for responding to TSC1 Control Purpose P7 (see SPN 3350) messages.

00b = Not Ready
01b = Ready
10b = Error
11b = Not Available/Not Supported.";
CM_ SG_ 2566605822 SAOfCtrlDeviceForTSC1CtrlPurpP7 "THe source address of the SAE J1939 device that is currently sending a TSC1 message with control purpose P7 that is actively controlling or limiting the power system output.
254 (FEh) indicates this parameter is supported, but no device is ...";
CM_ BO_ 2566605566 "Motor/Generator 3 Inverter Active Power Limits
Sent by this Motor/Generator Inverter instance and contains the current operating conditions of the inverter.  This message would be received by a controller application that is responsible for ...";
CM_ SG_ 2566605566 TrqLimDueToMachineCharacter_0001 "Output torque is being limited due to SPN 11803 [Torque] approaching or exceeding a motor design characteristic.  For example, for permanent magnet machines, this would be in the field weakening area.
00b = No torque limit for this reason
01b = ...";
CM_ SG_ 2566605566 PLedDueToActiveSpdRateLmt "Output power is being limited due to exceeding internally defined speed rate limit(s) or SPN 11906 [Inverter Rate Limits Request Absolute Speed Rate Limit].
00b = No power limit for this reason
01b = Power limited for this reason
10b = Error
11b ...";
CM_ SG_ 2566605566 PLedDueToActiveTrqRateLmt "Output power is being limited due to exceeding internally defined torque rate limit(s) or SPN 11907 [Inverter Rate Limits Request Absolute Torque Rate Limit].
00b = No power limit for this reason
01b = Power limited for this reason
10b = Error
 ...";
CM_ SG_ 2566605566 PLedDueToFaultCondition "Output power is being limited due to an fault condition that requires a torque limitation to prevent further damage (e.g. “limp home mode”).  For example, this could be in case of temperature sensor defects.  Typically, this parameter would be ...";
CM_ SG_ 2566605566 PLedDueToMotorTemp "Output power is being limited due to one or more motor temperature(s), see SPNs 11802 and 11871 through 11873 [Motor Temperature 1-4] approaching or exceeding internally defined limit(s).
00b = No power limit for this reason
01b = Power limited ...";
CM_ SG_ 2566605566 PLedDueToInvTemp "Output power is being limited due to one or more inverter temperature(s), see SPNs 11867 through 11870 [Inverter Temperature 1-4] approaching or exceeding internally defined limit(s).
00b = No power limit for this reason
01b = Power limited for ...";
CM_ SG_ 2566605566 PLedDueToSpdMin "Output power is being limited due to SPN 11801 [Speed] approaching or falling below the SPN 11850 [Inverter Limits Active Speed Minimum].

00b = No power limit for this reason
01b = Power limited for this reason
10b = Error
11b = Not Available";
CM_ SG_ 2566605566 PLedDueToSpdMax "Output power is being limited due to SPN 11801 [Speed] approaching or exceeding the SPN 11849 [Inverter Limits Active Speed Maximum].

00b = No power limit for this reason
01b = Power limited for this reason
10b = Error
11b = Not Available";
CM_ SG_ 2566605566 PLedDueToTrqMin "Output power is being limited due to SPN 11803 [Torque] approaching or falling below the SPN 11848 [Inverter Limits Active Torque Minimum].
00b = No power limit for this reason
01b = Power limited for this reason
10b = Error
11b = Not Available
 ...";
CM_ SG_ 2566605566 PLedDueToTrqMax "Output power is being limited due to SPN 11803 [Torque] approaching or exceeding the SPN 11847 [Inverter Limits Active Torque Maximum].

00b = No power limit for this reason
01b = Power limited for this reason
10b = Error
11b = Not Available";
CM_ SG_ 2566605566 PLedDueToDCSidePwrMin "Output power is being limited due to DC Side Power (product of SPN 11826 [Inverter DC Side Current] and SPN 11804 [Inverter DC Side Voltage]) approaching or falling below the SPN 11838 [Inverter Limits Active DC Side Power Minimum].
00b = No power ...";
CM_ SG_ 2566605566 PLedDueToDCSidePwrMax "Output power is being limited due to DC Side Power (product of SPN 11826 [Inverter DC Side Current] and SPN 11804 [Inverter DC Side Voltage]) approaching or exceeding the SPN 11837 [Inverter Limits Active DC Side Power Maximum].
00b = No power ...";
CM_ SG_ 2566605566 PLedDueToMechPwrMin "Output power is being limited due to Mechanical Power (product of SPN 11803 [Torque] and SPN 11801 [Speed]) approaching or falling below the SPN 11836 [Inverter Limits Active Mechanical Power Minimum].
00b = No power limit for this reason
01b = ...";
CM_ SG_ 2566605566 PLedDueToMechPwrMax "Output power is being limited due to Mechanical Power (product of SPN 11803 [Torque] and SPN 11801 [Speed]) approaching or exceeding the SPN 11835 [Inverter Limits Active Mechanical Power Maximum].
00b = No power limit for this reason
01b = Power ...";
CM_ SG_ 2566605566 PLedDueToDCSideVMin "Output power is being limited due to SPN 11804 [Inverter DC Side Voltage] approaching or falling below the SPN 11864 [Inverter Limits Active DC Side Voltage Minimum].
00b = No power limit for this reason
01b = Power limited for this reason
10b = ...";
CM_ SG_ 2566605566 PLedDueToDCSideVMax "Output power is being limited due to SPN 11804 [Inverter DC Side Voltage] approaching or exceeding the SPN 11863 [Inverter Limits Active DC Side Voltage Maximum].
00b = No power limit for this reason
01b = Power limited for this reason
10b = ...";
CM_ SG_ 2566605566 PLedDueToDCSideCurMin "Output power is being limited due to SPN 11826 [Inverter DC Side Current] approaching or falling below the SPN 11866 [Inverter Limits Active DC Side Current Minimum].
00b = No power limit for this reason
01b = Power limited for this reason
10b = ...";
CM_ SG_ 2566605566 PLedDueToDCSideCurMax "Output power is being limited due to SPN 11826 [Inverter DC Side Current] approaching or exceeding the SPN 11865 [Inverter Limits Active DC Side Current Maximum].
00b = No power limit for this reason
01b = Power limited for this reason
10b = ...";
CM_ SG_ 2566605566 PLedDueToUndefinedReason "Output power is being limited due to an undefined reason.

00b = No power limit for this reason
01b = Power limited for this reason
10b = Error
11b = Not Available";
CM_ BO_ 2566605310 "Motor/Generator 3 Inverter Isolation Integrity
The electrical isolation Integrity status of the Inverter.  Some examples of use would be for a hybrid or electric vehicle propulsion motor or generator.";
CM_ SG_ 2566605310 HVBusPassiveIsolTestResults "The isolation resistance that resulted from the High-Voltage Bus Passive Isolation Test.
See SPN 11886 [High-Voltage Bus Passive Isolation Test Status] for test status and SPN 11879 [High-Voltage Bus Passive Isolation Test Command] for the command ...";
CM_ SG_ 2566605310 HVBusActiveIsolTestResults "The isolation resistance that resulted from the High-Voltage Bus Active Isolation Test.
See SPN 11885 [High-Voltage Bus Active Isolation Test Status] for test status and SPN 11878 [High-Voltage Bus Active Isolation Test Command] for the command to ...";
CM_ SG_ 2566605310 HVBusPassiveIsolTestStatus "Status of the high-voltage bus electrical passive isolation test as performed by this instance of the Motor/Generator.
0000b = No test requested / No test in process
0001b = Test requested but not yet in process
0010b = Test in process
0011b = ...";
CM_ SG_ 2566605310 HVBusActiveIsolTestStatus "Status of the high-voltage bus electrical active isolation test as performed by this instance of the Motor/Generator.
0000b = No test requested / No test in process
0001b = Test requested but not yet in process
0010b = Test in process
0011b = ...";
CM_ SG_ 2566605310 DCSideNegToChassisGroundV "The voltage level of the high voltage DC side, as measured by the inverter between the negative side of the High Voltage DC Side input and the chassis of the inverter enclosure.  This voltage can be used for system level monitoring of DC Side High ...";
CM_ SG_ 2566605310 Counter "The message counter is used to detect situations where the transmitting ECU malfunction repeats the same frame all the time. The receiver of the information may use the counter parameter to detect this situation. The transmitting device will ...";
CM_ SG_ 2566605310 CRC "The CRC is defined as follows:
• Length: 8 bits
• Polynomial: x^8+x^5+x^3+x^2+x+1
• Initial Value: FFh
• Input Data Reflection: Not reflected
• Result Data Reflection: Not reflected
• XOR value: FFh
SAE makes no claim of the functional safety ...";
CM_ BO_ 2566605054 "Motor/Generator 3 Inverter Motor Temperature
Motor Temperature Status Message";
CM_ SG_ 2566605054 Temp4 "The exact location of this temperature can be defined by the manufacturer.  It is intended to located somewhere on the motor.";
CM_ SG_ 2566605054 Temp3 "The exact location of this temperature can be defined by the manufacturer.  It is intended to located somewhere on the motor.";
CM_ SG_ 2566605054 Temp2 "The exact location of this temperature can be defined by the manufacturer.  It is intended to located somewhere on the motor.";
CM_ SG_ 2566605054 Temp1 "The exact location of this temperature can be defined by the manufacturer.  It is intended to located somewhere on the motor.";
CM_ BO_ 2566604798 "Motor/Generator 3 Inverter Temperature
Inverter Temperature Status Message";
CM_ SG_ 2566604798 Five "The exact location of this temperature can be defined by the manufacturer. It is intended to be located somewhere on the inverter.";
CM_ SG_ 2566604798 Four "The exact location of this temperature can be defined by the manufacturer.  It is intended to be located somewhere on the inverter.";
CM_ SG_ 2566604798 Three "The exact location of this temperature can be defined by the manufacturer.  It is intended to be located somewhere on the inverter.";
CM_ SG_ 2566604798 Two "The exact location of this temperature can be defined by the manufacturer.  It is intended to be located somewhere on the inverter.";
CM_ SG_ 2566604798 One "The exact location of this temperature can be defined by the manufacturer.  It is intended to be located somewhere on the inverter.";
CM_ BO_ 2365277950 "Motor/Generator 3 Inverter Reference 2
The electrical reference values from this inverter.";
CM_ SG_ 2365277950 V "This value is used for converting inverter voltage in percent to units of Volts (RMS or DC).
(Value in Volts) = (Percent Value)/(100%) * (Reference Voltage)
For example, if this parameter has a value of 400 V and the percent value is equal to 75%, ...";
CM_ SG_ 2365277950 Cur "This value is used for converting inverter current in percent to units of Amps (RMS or DC).
(Value in Amps) = (Percent Value)/(100%) * (Reference Current)
For example, if this parameter has a value of 200 A and the percent value is equal to 75%, ...";
CM_ SG_ 2365277950 Counter "The message counter is used to detect situations where the transmitting ECU malfunction repeats the same frame all the time. The receiver of the information may use the counter parameter to detect this situation. The transmitting device will ...";
CM_ SG_ 2365277950 CRC "The CRC is defined as follows:
• Length: 8 bits
• Polynomial: x^8+x^5+x^3+x^2+x+1
• Initial Value: FFh
• Input Data Reflection: Not reflected
• Result Data Reflection: Not reflected
• XOR value: FFh
SAE makes no claim of the functional safety ...";
CM_ BO_ 2365277694 "Motor/Generator 3 Inverter Status 1
First Status Message from the Inverter.  Some examples of use would be for a hybrid or electric vehicle propulsion motor or generator.";
CM_ SG_ 2365277694 DCSideV "The measured or estimated DC side voltage.  

Refer to SPN 11854 [Reference Voltage] to convert % to Volts.";
CM_ SG_ 2365277694 DCSideCur "This is the DC side current of the inverter.
Refer to SPN 11853 [Reference Current] to convert % to Amps.
While motoring, the current is defined as positive.  For example, in a hybrid propulsion system, positive current flows from the HVES through ...";
CM_ SG_ 2365277694 Spd "The measured or estimated motor speed.  This refers to the motor rotor output and excludes any gearbox that may be attached to the motor.   

Refer to SPN 11822 [Reference Speed] to convert % to rpm.";
CM_ SG_ 2365277694 Trq "The measured or estimated motor torque.  This refers to the motor rotor output and excludes any gearbox that may be attached to the motor.
Refer to SPN 11821 [Reference Torque] to convert % to Nm.
The motor is generating when SPN 11801 [Speed] and ...";
CM_ SG_ 2365277694 Counter "The message counter is used to detect situations where the transmitting ECU malfunction repeats the same frame all the time. The receiver of the information may use the counter parameter to detect this situation. The transmitting device will ...";
CM_ SG_ 2365277694 CRC "The CRC is defined as follows:
• Length: 8 bits
• Polynomial: x^8+x^5+x^3+x^2+x+1
• Initial Value: FFh
• Input Data Reflection: Not reflected
• Result Data Reflection: Not reflected
• XOR value: FFh
SAE makes no claim of the functional safety ...";
CM_ BO_ 2365277438 "Motor/Generator 3 Inverter Reference 1
The torque and speed reference values from this inverter.";
CM_ SG_ 2365277438 Pwr "This value is used for converting power in percent to units of kW.  It is applicable to both mechanical and electrical power.
(Value in kW) = (Percent Value)/(100%) * (Reference Power)
For example, if this parameter has a value of 400 kW and the ...";
CM_ SG_ 2365277438 Spd "This value is used for converting Speed in percent to units of rpm.
Value in rpm = (Percent Value)/(100%) * (Reference Speed)
For example, if this parameter has a value of 8192 rpm and the percent value is equal to 75%, then the value in rpm will ...";
CM_ SG_ 2365277438 Trq "This value is used for converting torque in percent to units of Nm.
Value in Nm = (Percent Value)/(100%) * (Reference Torque)
For example, if this parameter has a value of 400 Nm and the percent value is equal to 75%, then the value in Nm will be ...";
CM_ SG_ 2365277438 Counter "The message counter is used to detect situations where the transmitting ECU malfunction repeats the same frame all the time. The receiver of the information may use the counter parameter to detect this situation. The transmitting device will ...";
CM_ SG_ 2365277438 CRC "The CRC is defined as follows:
• Length: 8 bits
• Polynomial: x^8+x^5+x^3+x^2+x+1
• Initial Value: FFh
• Input Data Reflection: Not reflected
• Result Data Reflection: Not reflected
• XOR value: FFh
SAE makes no claim of the functional safety ...";
CM_ BO_ 2566603774 "Motor/Generator 4 Inverter Active Power Limits
Sent by this Motor/Generator Inverter instance and contains the current operating conditions of the inverter.  This message would be received by a controller application that is responsible for ...";
CM_ SG_ 2566603774 TrqLimDueToMachineCharacter_0002 "Output torque is being limited due to SPN 11921 [Torque] approaching or exceeding a motor design characteristic.  For example, for permanent magnet machines, this would be in the field weakening area.
00b = No torque limit for this reason
01b = ...";
CM_ SG_ 2566603774 PLedDueToActiveSpdRateLmt "Output power is being limited due to exceeding internally defined speed rate limit(s) or SPN 12024 [Inverter Rate Limits Request Absolute Speed Rate Limit].
00b = No power limit for this reason
01b = Power limited for this reason
10b = Error
11b ...";
CM_ SG_ 2566603774 PLedDueToActiveTrqRateLmt "Output power is being limited due to exceeding internally defined torque rate limit(s) or SPN 12025 [Inverter Rate Limits Request Absolute Torque Rate Limit].
00b = No power limit for this reason
01b = Power limited for this reason
10b = Error
 ...";
CM_ SG_ 2566603774 PLedDueToFaultCondition "Output power is being limited due to an fault condition that requires a torque limitation to prevent further damage (e.g. “limp home mode”).  For example, this could be in case of temperature sensor defects.  Typically, this parameter would be ...";
CM_ SG_ 2566603774 PLedDueToMotorTemp "Output power is being limited due to one or more motor temperature(s), see SPNs 11920 and 11989 through 11991 [Motor Temperature 1-4] approaching or exceeding internally defined limit(s).
00b = No power limit for this reason
01b = Power limited ...";
CM_ SG_ 2566603774 PLedDueToInvTemp "Output power is being limited due to one or more inverter temperature(s), see SPNs 11985 through 11988 [Inverter Temperature 1-4] approaching or exceeding internally defined limit(s).
00b = No power limit for this reason
01b = Power limited for ...";
CM_ SG_ 2566603774 PLedDueToSpdMin "Output power is being limited due to SPN 11919 [Speed] approaching or falling below the SPN 11968 [Inverter Limits Active Speed Minimum].

00b = No power limit for this reason
01b = Power limited for this reason
10b = Error
11b = Not Available";
CM_ SG_ 2566603774 PLedDueToSpdMax "Output power is being limited due to SPN 11919 [Speed] approaching or exceeding the SPN 11967 [Inverter Limits Active Speed Maximum].

00b = No power limit for this reason
01b = Power limited for this reason
10b = Error
11b = Not Available";
CM_ SG_ 2566603774 PLedDueToTrqMin "Output power is being limited due to SPN 11921 [Torque] approaching or falling below the SPN 11966 [Inverter Limits Active Torque Minimum].
00b = No power limit for this reason
01b = Power limited for this reason
10b = Error
11b = Not Available
 ...";
CM_ SG_ 2566603774 PLedDueToTrqMax "Output power is being limited due to SPN 11921 [Torque] approaching or exceeding the SPN 11965 [Inverter Limits Active Torque Maximum].

00b = No power limit for this reason
01b = Power limited for this reason
10b = Error
11b = Not Available";
CM_ SG_ 2566603774 PLedDueToDCSidePwrMin "Output power is being limited due to DC Side Power (product of SPN 11944 [Inverter DC Side Current] and SPN 11922 [Inverter DC Side Voltage]) approaching or falling below the SPN 11956 [Inverter Limits Active DC Side Power Minimum].
00b = No power ...";
CM_ SG_ 2566603774 PLedDueToDCSidePwrMax "Output power is being limited due to DC Side Power (product of SPN 11944 [Inverter DC Side Current] and SPN 11922 [Inverter DC Side Voltage]) approaching or exceeding the SPN 11955 [Inverter Limits Active DC Side Power Maximum].
00b = No power ...";
CM_ SG_ 2566603774 PLedDueToMechPwrMin "Output power is being limited due to Mechanical Power (product of SPN 11921 [Torque] and SPN 11919 [Speed]) approaching or falling below the SPN 11954 [Inverter Limits Active Mechanical Power Minimum].
00b = No power limit for this reason
01b = ...";
CM_ SG_ 2566603774 PLedDueToMechPwrMax "Output power is being limited due to Mechanical Power (product of SPN 11921 [Torque] and SPN 11919 [Speed]) approaching or exceeding the SPN 11953 [Inverter Limits Active Mechanical Power Maximum].
00b = No power limit for this reason
01b = Power ...";
CM_ SG_ 2566603774 PLedDueToDCSideVMin "Output power is being limited due to SPN 11922 [Inverter DC Side Voltage] approaching or falling below the SPN 11982 [Inverter Limits Active DC Side Voltage Minimum].
00b = No power limit for this reason
01b = Power limited for this reason
10b = ...";
CM_ SG_ 2566603774 PLedDueToDCSideVMax "Output power is being limited due to SPN 11922 [Inverter DC Side Voltage] approaching or exceeding the SPN 11981 [Inverter Limits Active DC Side Voltage Maximum].
00b = No power limit for this reason
01b = Power limited for this reason
10b = ...";
CM_ SG_ 2566603774 PLedDueToDCSideCurMin "Output power is being limited due to SPN 11944 [Inverter DC Side Current] approaching or falling below the SPN 11984 [Inverter Limits Active DC Side Current Minimum].
00b = No power limit for this reason
01b = Power limited for this reason
10b = ...";
CM_ SG_ 2566603774 PLedDueToDCSideCurMax "Output power is being limited due to SPN 11944 [Inverter DC Side Current] approaching or exceeding the SPN 11983 [Inverter Limits Active DC Side Current Maximum].
00b = No power limit for this reason
01b = Power limited for this reason
10b = ...";
CM_ SG_ 2566603774 PLedDueToUndefinedReason "Output power is being limited due to an undefined reason.

00b = No power limit for this reason
01b = Power limited for this reason
10b = Error
11b = Not Available";
CM_ BO_ 2566603518 "Motor/Generator 4 Inverter Isolation Integrity
The electrical isolation Integrity status of the Inverter.  Some examples of use would be for a hybrid or electric vehicle propulsion motor or generator.";
CM_ SG_ 2566603518 HVBusPassiveIsolTestResults "The isolation resistance that resulted from the High-Voltage Bus Passive Isolation Test.
See SPN 12004 [High-Voltage Bus Passive Isolation Test Status] for test status and SPN 11997 [High-Voltage Bus Passive Isolation Test Command] for the command ...";
CM_ SG_ 2566603518 HVBusActiveIsolTestResults "The isolation resistance that resulted from the High-Voltage Bus Active Isolation Test.
See SPN 12003 [High-Voltage Bus Active Isolation Test Status] for test status and SPN 11996 [High-Voltage Bus Active Isolation Test Command] for the command to ...";
CM_ SG_ 2566603518 HVBusPassiveIsolTestStatus "Status of the high-voltage bus electrical passive isolation test as performed by this instance of the Motor/Generator.
0000b = No test requested / No test in process
0001b = Test requested but not yet in process
0010b = Test in process
0011b = ...";
CM_ SG_ 2566603518 HVBusActiveIsolTestStatus "Status of the high-voltage bus electrical active isolation test as performed by this instance of the Motor/Generator.
0000b = No test requested / No test in process
0001b = Test requested but not yet in process
0010b = Test in process
0011b = ...";
CM_ SG_ 2566603518 DCSideNegToChassisGroundV "The voltage level of the high voltage DC side, as measured by the inverter between the negative side of the High Voltage DC Side input and the chassis of the inverter enclosure.  This voltage can be used for system level monitoring of DC Side High ...";
CM_ SG_ 2566603518 Counter "The message counter is used to detect situations where the transmitting ECU malfunction repeats the same frame all the time. The receiver of the information may use the counter parameter to detect this situation. The transmitting device will ...";
CM_ SG_ 2566603518 CRC "The CRC is defined as follows:
• Length: 8 bits
• Polynomial: x^8+x^5+x^3+x^2+x+1
• Initial Value: FFh
• Input Data Reflection: Not reflected
• Result Data Reflection: Not reflected
• XOR value: FFh
SAE makes no claim of the functional safety ...";
CM_ BO_ 2566603262 "Motor/Generator 4 Inverter Motor Temperature
Motor Temperature Status Message";
CM_ SG_ 2566603262 Temp4 "The exact location of this temperature can be defined by the manufacturer.  It is intended to located somewhere on the motor.";
CM_ SG_ 2566603262 Temp3 "The exact location of this temperature can be defined by the manufacturer.  It is intended to located somewhere on the motor.";
CM_ SG_ 2566603262 Temp2 "The exact location of this temperature can be defined by the manufacturer.  It is intended to located somewhere on the motor.";
CM_ SG_ 2566603262 Temp1 "The exact location of this temperature can be defined by the manufacturer.  It is intended to located somewhere on the motor.";
BA_DEF_ SG_  "GenSigInactiveValue" INT 0 0;
BA_DEF_ SG_  "SigType" ENUM  "Default","Range","RangeSigned","ASCII","Discrete","Control","ReferencePGN","DTC","StringDelimiter","StringLength","StringLengthControl","MessageCounter","MessageChecksum";
BA_DEF_ SG_  "GenSigStartValue" INT 0 2147483647;
BA_DEF_ SG_  "GenSigSendType" ENUM  "Cyclic","OnWrite","OnWriteWithRepetition","OnChange","OnChangeWithRepetition","IfActive","IfActiveWithRepetition","NoSigSendType";
BA_DEF_ SG_  "GenSigILSupport" ENUM  "No","Yes";
BA_DEF_ SG_  "SPN" INT 0 524287;
BA_DEF_ BO_  "J1939CPgSendTimeout" INT -1 3600000;
BA_DEF_ BO_  "J1939CPgTOS" INT 0 7;
BA_DEF_ BO_  "J1939PgAppearanceOnBus" ENUM  "Default","CAN_Extended","CANFD_Extended";
BA_DEF_ BO_  "FsJ1939UseCrcAndCounter" STRING ;
BA_DEF_ BO_  "TpJ1939VarDlc" ENUM  "No","Yes";
BA_DEF_ BO_  "GenMsgNrOfRepetition" INT 0 1000000;
BA_DEF_ BO_  "GenMsgCycleTimeFast" INT 0 3600000;
BA_DEF_ BO_  "GenMsgFastOnStart" INT 0 100000;
BA_DEF_ BO_  "GenMsgStartDelayTime" INT 0 100000;
BA_DEF_ BO_  "GenMsgILSupport" ENUM  "No","Yes";
BA_DEF_ BO_  "GenMsgDelayTime" INT 0 1000;
BA_DEF_ BO_  "GenMsgRequestable" INT 0 1;
BA_DEF_ BO_  "GenMsgSendType" ENUM  "cyclic","NotUsed","NotUsed","NotUsed","NotUsed","NotUsed","NotUsed","IfActive","noMsgSendType";
BA_DEF_ BO_  "VFrameFormat" ENUM  "StandardCAN","ExtendedCAN","reserved","J1939PG","reserved","reserved","reserved","reserved","reserved","reserved","reserved","reserved","reserved","reserved","StandardCAN_FD","ExtendedCAN_FD";
BA_DEF_ BO_  "SingleFrame" INT 0 1;
BA_DEF_ BO_  "GenMsgCycleTime" INT 0 3600000;
BA_DEF_ SG_  "SystemSignalLongSymbol" STRING ;
BA_DEF_DEF_  "GenSigInactiveValue" 0;
BA_DEF_DEF_  "SigType" "Default";
BA_DEF_DEF_  "GenSigStartValue" 0;
BA_DEF_DEF_  "GenSigSendType" "NoSigSendType";
BA_DEF_DEF_  "GenSigILSupport" "Yes";
BA_DEF_DEF_  "SPN" 0;
BA_DEF_DEF_  "J1939CPgSendTimeout" -1;
BA_DEF_DEF_  "J1939CPgTOS" 2;
BA_DEF_DEF_  "J1939PgAppearanceOnBus" "Default";
BA_DEF_DEF_  "FsJ1939UseCrcAndCounter" "";
BA_DEF_DEF_  "TpJ1939VarDlc" "No";
BA_DEF_DEF_  "GenMsgNrOfRepetition" 0;
BA_DEF_DEF_  "GenMsgCycleTimeFast" 0;
BA_DEF_DEF_  "GenMsgFastOnStart" 0;
BA_DEF_DEF_  "GenMsgStartDelayTime" 0;
BA_DEF_DEF_  "GenMsgILSupport" "Yes";
BA_DEF_DEF_  "GenMsgDelayTime" 0;
BA_DEF_DEF_  "GenMsgRequestable" 1;
BA_DEF_DEF_  "GenMsgSendType" "noMsgSendType";
BA_DEF_DEF_  "VFrameFormat" "J1939PG";
BA_DEF_DEF_  "SingleFrame" 1;
BA_DEF_DEF_  "GenMsgCycleTime" 0;
BA_DEF_DEF_  "SystemSignalLongSymbol" "";
BA_ "GenMsgDelayTime" BO_ 2566612990 100;
BA_ "GenMsgSendType" BO_ 2566612990 0;
BA_ "GenMsgCycleTime" BO_ 2566612990 1000;
BA_ "GenMsgDelayTime" BO_ 2499497726 50;
BA_ "GenMsgSendType" BO_ 2499497726 0;
BA_ "GenMsgCycleTime" BO_ 2499497726 250;
BA_ "GenMsgSendType" BO_ 2566606334 0;
BA_ "GenMsgCycleTime" BO_ 2566606334 1000;
BA_ "GenMsgSendType" BO_ 2566606078 0;
BA_ "GenMsgCycleTime" BO_ 2566606078 1000;
BA_ "GenMsgDelayTime" BO_ 2566605822 100;
BA_ "GenMsgSendType" BO_ 2566605822 0;
BA_ "GenMsgCycleTime" BO_ 2566605822 1000;
BA_ "GenMsgDelayTime" BO_ 2566605566 100;
BA_ "GenMsgSendType" BO_ 2566605566 0;
BA_ "GenMsgCycleTime" BO_ 2566605566 1000;
BA_ "FsJ1939UseCrcAndCounter" BO_ 2566605310 "Bc";
BA_ "GenMsgSendType" BO_ 2566605310 0;
BA_ "GenMsgCycleTime" BO_ 2566605310 250;
BA_ "GenMsgSendType" BO_ 2566605054 0;
BA_ "GenMsgCycleTime" BO_ 2566605054 1000;
BA_ "GenMsgSendType" BO_ 2566604798 0;
BA_ "GenMsgCycleTime" BO_ 2566604798 1000;
BA_ "FsJ1939UseCrcAndCounter" BO_ 2365277950 "Bc";
BA_ "GenMsgSendType" BO_ 2365277950 0;
BA_ "GenMsgCycleTime" BO_ 2365277950 1000;
BA_ "FsJ1939UseCrcAndCounter" BO_ 2365277694 "Bc";
BA_ "GenMsgSendType" BO_ 2365277694 0;
BA_ "GenMsgCycleTime" BO_ 2365277694 10;
BA_ "FsJ1939UseCrcAndCounter" BO_ 2365277438 "Bc";
BA_ "GenMsgSendType" BO_ 2365277438 0;
BA_ "GenMsgCycleTime" BO_ 2365277438 1000;
BA_ "GenMsgDelayTime" BO_ 2566603774 100;
BA_ "GenMsgSendType" BO_ 2566603774 0;
BA_ "GenMsgCycleTime" BO_ 2566603774 1000;
BA_ "FsJ1939UseCrcAndCounter" BO_ 2566603518 "Bc";
BA_ "GenMsgSendType" BO_ 2566603518 0;
BA_ "GenMsgCycleTime" BO_ 2566603518 250;
BA_ "GenMsgSendType" BO_ 2566603262 0;
BA_ "GenMsgCycleTime" BO_ 2566603262 1000;
BA_ "SigType" SG_ 2566612990 TrqLimDueToMachineCharacter_0000 4;
BA_ "SPN" SG_ 2566612990 TrqLimDueToMachineCharacter_0000 13048;
BA_ "SystemSignalLongSymbol" SG_ 2566612990 TrqLimDueToMachineCharacter_0000 "TrqLimDueToMachineCharacteristics";
BA_ "SigType" SG_ 2566612990 PLedDueToActiveSpdRateLmt 4;
BA_ "SPN" SG_ 2566612990 PLedDueToActiveSpdRateLmt 13047;
BA_ "SigType" SG_ 2566612990 PLedDueToActiveTrqRateLmt 4;
BA_ "SPN" SG_ 2566612990 PLedDueToActiveTrqRateLmt 13046;
BA_ "SigType" SG_ 2566612990 PLedDueToFaultCondition 4;
BA_ "SPN" SG_ 2566612990 PLedDueToFaultCondition 13045;
BA_ "SigType" SG_ 2566612990 PLedDueToMotorTemp 4;
BA_ "SPN" SG_ 2566612990 PLedDueToMotorTemp 10831;
BA_ "SigType" SG_ 2566612990 PLedDueToInvTemp 4;
BA_ "SPN" SG_ 2566612990 PLedDueToInvTemp 10830;
BA_ "SigType" SG_ 2566612990 PLedDueToSpdMin 4;
BA_ "SPN" SG_ 2566612990 PLedDueToSpdMin 10829;
BA_ "SigType" SG_ 2566612990 PLedDueToSpdMax 4;
BA_ "SPN" SG_ 2566612990 PLedDueToSpdMax 10828;
BA_ "SigType" SG_ 2566612990 PLedDueToTrqMin 4;
BA_ "SPN" SG_ 2566612990 PLedDueToTrqMin 10827;
BA_ "SigType" SG_ 2566612990 PLedDueToTrqMax 4;
BA_ "SPN" SG_ 2566612990 PLedDueToTrqMax 10826;
BA_ "SigType" SG_ 2566612990 PLedDueToDCSidePwrMin 4;
BA_ "SPN" SG_ 2566612990 PLedDueToDCSidePwrMin 10825;
BA_ "SigType" SG_ 2566612990 PLedDueToDCSidePwrMax 4;
BA_ "SPN" SG_ 2566612990 PLedDueToDCSidePwrMax 10824;
BA_ "SigType" SG_ 2566612990 PLedDueToMechPwrMin 4;
BA_ "SPN" SG_ 2566612990 PLedDueToMechPwrMin 10823;
BA_ "SigType" SG_ 2566612990 PLedDueToMechPwrMax 4;
BA_ "SPN" SG_ 2566612990 PLedDueToMechPwrMax 10822;
BA_ "SigType" SG_ 2566612990 PLedDueToDCSideVMin 4;
BA_ "SPN" SG_ 2566612990 PLedDueToDCSideVMin 10821;
BA_ "SigType" SG_ 2566612990 PLedDueToDCSideVMax 4;
BA_ "SPN" SG_ 2566612990 PLedDueToDCSideVMax 10820;
BA_ "SigType" SG_ 2566612990 PLedDueToDCSideCurMin 4;
BA_ "SPN" SG_ 2566612990 PLedDueToDCSideCurMin 10819;
BA_ "SigType" SG_ 2566612990 PLedDueToDCSideCurMax 4;
BA_ "SPN" SG_ 2566612990 PLedDueToDCSideCurMax 10818;
BA_ "SigType" SG_ 2566612990 PLedDueToUndefinedReason 4;
BA_ "SPN" SG_ 2566612990 PLedDueToUndefinedReason 10817;
BA_ "SPN" SG_ 2633721598 ReleaseZone2Name 11024;
BA_ "SPN" SG_ 2633721598 ReleaseZone1Name 11023;
BA_ "SPN" SG_ 2633721598 HeatZone2Name 11022;
BA_ "SPN" SG_ 2633721598 HeatZone1Name 11021;
BA_ "SPN" SG_ 2633721598 DetectorZone8Name 11020;
BA_ "SPN" SG_ 2633721598 DetectorZone7Name 11019;
BA_ "SPN" SG_ 2633721598 DetectorZone6Name 11018;
BA_ "SPN" SG_ 2633721598 DetectorZone5Name 11017;
BA_ "SPN" SG_ 2633721598 DetectorZone4Name 11016;
BA_ "SPN" SG_ 2633721598 DetectorZone3Name 11015;
BA_ "SPN" SG_ 2633721598 DetectorZone2Name 11014;
BA_ "SPN" SG_ 2633721598 DetectorZone1Name 11013;
BA_ "SPN" SG_ 2633721598 Name 11012;
BA_ "SPN" SG_ 2633721342 ReleaseZone2Name 11011;
BA_ "SPN" SG_ 2633721342 ReleaseZone1Name 11010;
BA_ "SPN" SG_ 2633721342 HeatZone2Name 11009;
BA_ "SPN" SG_ 2633721342 HeatZone1Name 11008;
BA_ "SPN" SG_ 2633721342 DetectorZone8Name 11007;
BA_ "SPN" SG_ 2633721342 DetectorZone7Name 11006;
BA_ "SPN" SG_ 2633721342 DetectorZone6Name 11005;
BA_ "SPN" SG_ 2633721342 DetectorZone5Name 11004;
BA_ "SPN" SG_ 2633721342 DetectorZone4Name 11003;
BA_ "SPN" SG_ 2633721342 DetectorZone3Name 11002;
BA_ "SPN" SG_ 2633721342 DetectorZone2Name 11001;
BA_ "SPN" SG_ 2633721342 DetectorZone1Name 11000;
BA_ "SPN" SG_ 2633721342 Name 10999;
BA_ "SPN" SG_ 2633721086 ReleaseZone2Name 10998;
BA_ "SPN" SG_ 2633721086 ReleaseZone1Name 10997;
BA_ "SPN" SG_ 2633721086 HeatZone2Name 10996;
BA_ "SPN" SG_ 2633721086 HeatZone1Name 10995;
BA_ "SPN" SG_ 2633721086 DetectorZone8Name 10994;
BA_ "SPN" SG_ 2633721086 DetectorZone7Name 10993;
BA_ "SPN" SG_ 2633721086 DetectorZone6Name 10992;
BA_ "SPN" SG_ 2633721086 DetectorZone5Name 10991;
BA_ "SPN" SG_ 2633721086 DetectorZone4Name 10990;
BA_ "SPN" SG_ 2633721086 DetectorZone3Name 10989;
BA_ "SPN" SG_ 2633721086 DetectorZone2Name 10988;
BA_ "SPN" SG_ 2633721086 DetectorZone1Name 10987;
BA_ "SPN" SG_ 2633721086 Name 10986;
BA_ "SPN" SG_ 2633720830 ReleaseZone2Name 10985;
BA_ "SPN" SG_ 2633720830 ReleaseZone1Name 10984;
BA_ "SPN" SG_ 2633720830 HeatZone2Name 10983;
BA_ "SPN" SG_ 2633720830 HeatZone1Name 10982;
BA_ "SPN" SG_ 2633720830 DetectorZone8Name 10981;
BA_ "SPN" SG_ 2633720830 DetectorZone7Name 10980;
BA_ "SPN" SG_ 2633720830 DetectorZone6Name 10979;
BA_ "SPN" SG_ 2633720830 DetectorZone5Name 10978;
BA_ "SPN" SG_ 2633720830 DetectorZone4Name 10977;
BA_ "SPN" SG_ 2633720830 DetectorZone3Name 10976;
BA_ "SPN" SG_ 2633720830 DetectorZone2Name 10975;
BA_ "SPN" SG_ 2633720830 DetectorZone1Name 10974;
BA_ "SPN" SG_ 2633720830 Name 10973;
BA_ "SigType" SG_ 2633720574 SecondPwrV 1;
BA_ "SPN" SG_ 2633720574 SecondPwrV 10972;
BA_ "SigType" SG_ 2633720574 PrimaryPwrV 1;
BA_ "SPN" SG_ 2633720574 PrimaryPwrV 10971;
BA_ "SigType" SG_ 2633720574 PressSw2Data 1;
BA_ "SPN" SG_ 2633720574 PressSw2Data 10970;
BA_ "SigType" SG_ 2633720574 PressSw1Data 1;
BA_ "SPN" SG_ 2633720574 PressSw1Data 10969;
BA_ "SigType" SG_ 2633720574 ReleaseZone2Data 1;
BA_ "SPN" SG_ 2633720574 ReleaseZone2Data 10968;
BA_ "SigType" SG_ 2633720574 ReleaseZone1Data 1;
BA_ "SPN" SG_ 2633720574 ReleaseZone1Data 10967;
BA_ "SigType" SG_ 2633720574 HeatZone2Data 1;
BA_ "SPN" SG_ 2633720574 HeatZone2Data 10966;
BA_ "SigType" SG_ 2633720574 HeatZone1Data 1;
BA_ "SPN" SG_ 2633720574 HeatZone1Data 10965;
BA_ "SigType" SG_ 2633720318 SecondPwrV 1;
BA_ "SPN" SG_ 2633720318 SecondPwrV 10964;
BA_ "SigType" SG_ 2633720318 PrimaryPwrV 1;
BA_ "SPN" SG_ 2633720318 PrimaryPwrV 10963;
BA_ "SigType" SG_ 2633720318 PressSw2Data 1;
BA_ "SPN" SG_ 2633720318 PressSw2Data 10962;
BA_ "SigType" SG_ 2633720318 PressSw1Data 1;
BA_ "SPN" SG_ 2633720318 PressSw1Data 10961;
BA_ "SigType" SG_ 2633720318 ReleaseZone2Data 1;
BA_ "SPN" SG_ 2633720318 ReleaseZone2Data 10960;
BA_ "SigType" SG_ 2633720318 ReleaseZone1Data 1;
BA_ "SPN" SG_ 2633720318 ReleaseZone1Data 10959;
BA_ "SigType" SG_ 2633720318 HeatZone2Data 1;
BA_ "SPN" SG_ 2633720318 HeatZone2Data 10958;
BA_ "SigType" SG_ 2633720318 HeatZone1Data 1;
BA_ "SPN" SG_ 2633720318 HeatZone1Data 10957;
BA_ "SigType" SG_ 2633720062 SecondPwrV 1;
BA_ "SPN" SG_ 2633720062 SecondPwrV 10956;
BA_ "SigType" SG_ 2633720062 PrimaryPwrV 1;
BA_ "SPN" SG_ 2633720062 PrimaryPwrV 10955;
BA_ "SigType" SG_ 2633720062 PressSw2Data 1;
BA_ "SPN" SG_ 2633720062 PressSw2Data 10954;
BA_ "SigType" SG_ 2633720062 PressSw1Data 1;
BA_ "SPN" SG_ 2633720062 PressSw1Data 10953;
BA_ "SigType" SG_ 2633720062 ReleaseZone2Data 1;
BA_ "SPN" SG_ 2633720062 ReleaseZone2Data 10952;
BA_ "SigType" SG_ 2633720062 ReleaseZone1Data 1;
BA_ "SPN" SG_ 2633720062 ReleaseZone1Data 10951;
BA_ "SigType" SG_ 2633720062 HeatZone2Data 1;
BA_ "SPN" SG_ 2633720062 HeatZone2Data 10950;
BA_ "SigType" SG_ 2633720062 HeatZone1Data 1;
BA_ "SPN" SG_ 2633720062 HeatZone1Data 10949;
BA_ "SigType" SG_ 2633719806 SecondPwrV 1;
BA_ "SPN" SG_ 2633719806 SecondPwrV 10948;
BA_ "SigType" SG_ 2633719806 PrimaryPwrV 1;
BA_ "SPN" SG_ 2633719806 PrimaryPwrV 10947;
BA_ "SigType" SG_ 2633719806 PressSw2Data 1;
BA_ "SPN" SG_ 2633719806 PressSw2Data 10946;
BA_ "SigType" SG_ 2633719806 PressSw1Data 1;
BA_ "SPN" SG_ 2633719806 PressSw1Data 10945;
BA_ "SigType" SG_ 2633719806 ReleaseZone2Data 1;
BA_ "SPN" SG_ 2633719806 ReleaseZone2Data 10944;
BA_ "SigType" SG_ 2633719806 ReleaseZone1Data 1;
BA_ "SPN" SG_ 2633719806 ReleaseZone1Data 10943;
BA_ "SigType" SG_ 2633719806 HeatZone2Data 1;
BA_ "SPN" SG_ 2633719806 HeatZone2Data 10942;
BA_ "SigType" SG_ 2633719806 HeatZone1Data 1;
BA_ "SPN" SG_ 2633719806 HeatZone1Data 10941;
BA_ "SigType" SG_ 2633719550 Detector8Data 1;
BA_ "SPN" SG_ 2633719550 Detector8Data 10940;
BA_ "SPN" SG_ 2633719550 Detector8DetectorDataSLOT 10939;
BA_ "SPN" SG_ 2633719550 Detector8DetectorType 10938;
BA_ "SigType" SG_ 2633719550 Detector7Data 1;
BA_ "SPN" SG_ 2633719550 Detector7Data 10937;
BA_ "SPN" SG_ 2633719550 Detector7DetectorDataSLOT 10936;
BA_ "SPN" SG_ 2633719550 Detector7DetectorType 10935;
BA_ "SigType" SG_ 2633719550 Detector6Data 1;
BA_ "SPN" SG_ 2633719550 Detector6Data 10934;
BA_ "SPN" SG_ 2633719550 Detector6DetectorDataSLOT 10933;
BA_ "SPN" SG_ 2633719550 Detector6DetectorType 10932;
BA_ "SigType" SG_ 2633719550 Detector5Data 1;
BA_ "SPN" SG_ 2633719550 Detector5Data 10931;
BA_ "SPN" SG_ 2633719550 Detector5DetectorDataSLOT 10930;
BA_ "SPN" SG_ 2633719550 Detector5DetectorType 10929;
BA_ "SigType" SG_ 2633719550 Detector4Data 1;
BA_ "SPN" SG_ 2633719550 Detector4Data 10928;
BA_ "SPN" SG_ 2633719550 Detector4DetectorDataSLOT 10927;
BA_ "SPN" SG_ 2633719550 Detector4DetectorType 10926;
BA_ "SigType" SG_ 2633719550 Detector3Data 1;
BA_ "SPN" SG_ 2633719550 Detector3Data 10925;
BA_ "SPN" SG_ 2633719550 Detector3DetectorDataSLOT 10924;
BA_ "SPN" SG_ 2633719550 Detector3DetectorType 10923;
BA_ "SigType" SG_ 2633719550 Detector2Data 1;
BA_ "SPN" SG_ 2633719550 Detector2Data 10922;
BA_ "SPN" SG_ 2633719550 Detector2DetectorDataSLOT 10921;
BA_ "SPN" SG_ 2633719550 Detector2DetectorType 10920;
BA_ "SigType" SG_ 2633719550 Detector1Data 1;
BA_ "SPN" SG_ 2633719550 Detector1Data 10919;
BA_ "SPN" SG_ 2633719550 Detector1DetectorDataSLOT 10918;
BA_ "SPN" SG_ 2633719550 Detector1DetectorType 10917;
BA_ "SigType" SG_ 2633719294 Detector8Data 1;
BA_ "SPN" SG_ 2633719294 Detector8Data 10916;
BA_ "SPN" SG_ 2633719294 Detector8DetectorDataSLOT 10915;
BA_ "SPN" SG_ 2633719294 Detector8DetectorType 10914;
BA_ "SigType" SG_ 2633719294 Detector7Data 1;
BA_ "SPN" SG_ 2633719294 Detector7Data 10913;
BA_ "SPN" SG_ 2633719294 Detector7DetectorDataSLOT 10912;
BA_ "SPN" SG_ 2633719294 Detector7DetectorType 10911;
BA_ "SigType" SG_ 2633719294 Detector6Data 1;
BA_ "SPN" SG_ 2633719294 Detector6Data 10910;
BA_ "SPN" SG_ 2633719294 Detector6DetectorDataSLOT 10909;
BA_ "SPN" SG_ 2633719294 Detector6DetectorType 10908;
BA_ "SigType" SG_ 2633719294 Detector5Data 1;
BA_ "SPN" SG_ 2633719294 Detector5Data 10907;
BA_ "SPN" SG_ 2633719294 Detector5DetectorDataSLOT 10906;
BA_ "SPN" SG_ 2633719294 Detector5DetectorType 10905;
BA_ "SigType" SG_ 2633719294 Detector4Data 1;
BA_ "SPN" SG_ 2633719294 Detector4Data 10904;
BA_ "SPN" SG_ 2633719294 Detector4DetectorDataSLOT 10903;
BA_ "SPN" SG_ 2633719294 Detector4DetectorType 10902;
BA_ "SigType" SG_ 2633719294 Detector3Data 1;
BA_ "SPN" SG_ 2633719294 Detector3Data 10901;
BA_ "SPN" SG_ 2633719294 Detector3DetectorDataSLOT 10900;
BA_ "SPN" SG_ 2633719294 Detector3DetectorType 10899;
BA_ "SigType" SG_ 2633719294 Detector2Data 1;
BA_ "SPN" SG_ 2633719294 Detector2Data 10898;
BA_ "SPN" SG_ 2633719294 Detector2DetectorDataSLOT 10897;
BA_ "SPN" SG_ 2633719294 Detector2DetectorType 10896;
BA_ "SigType" SG_ 2633719294 Detector1Data 1;
BA_ "SPN" SG_ 2633719294 Detector1Data 10895;
BA_ "SPN" SG_ 2633719294 Detector1DetectorDataSLOT 10894;
BA_ "SPN" SG_ 2633719294 Detector1DetectorType 10893;
BA_ "SigType" SG_ 2633719038 Detector8Data 1;
BA_ "SPN" SG_ 2633719038 Detector8Data 10892;
BA_ "SPN" SG_ 2633719038 Detector8DetectorDataSLOT 10891;
BA_ "SPN" SG_ 2633719038 Detector8DetectorType 10890;
BA_ "SigType" SG_ 2633719038 Detector7Data 1;
BA_ "SPN" SG_ 2633719038 Detector7Data 10889;
BA_ "SPN" SG_ 2633719038 Detector7DetectorDataSLOT 10888;
BA_ "SPN" SG_ 2633719038 Detector7DetectorType 10887;
BA_ "SigType" SG_ 2633719038 Detector6Data 1;
BA_ "SPN" SG_ 2633719038 Detector6Data 10886;
BA_ "SPN" SG_ 2633719038 Detector6DetectorDataSLOT 10885;
BA_ "SPN" SG_ 2633719038 Detector6DetectorType 10884;
BA_ "SigType" SG_ 2633719038 Detector5Data 1;
BA_ "SPN" SG_ 2633719038 Detector5Data 10883;
BA_ "SPN" SG_ 2633719038 Detector5DetectorDataSLOT 10882;
BA_ "SPN" SG_ 2633719038 Detector5DetectorType 10881;
BA_ "SigType" SG_ 2633719038 Detector4Data 1;
BA_ "SPN" SG_ 2633719038 Detector4Data 10880;
BA_ "SPN" SG_ 2633719038 Detector4DetectorDataSLOT 10879;
BA_ "SPN" SG_ 2633719038 Detector4DetectorType 10878;
BA_ "SigType" SG_ 2633719038 Detector3Data 1;
BA_ "SPN" SG_ 2633719038 Detector3Data 10877;
BA_ "SPN" SG_ 2633719038 Detector3DetectorDataSLOT 10876;
BA_ "SPN" SG_ 2633719038 Detector3DetectorType 10875;
BA_ "SigType" SG_ 2633719038 Detector2Data 1;
BA_ "SPN" SG_ 2633719038 Detector2Data 10874;
BA_ "SPN" SG_ 2633719038 Detector2DetectorDataSLOT 10873;
BA_ "SPN" SG_ 2633719038 Detector2DetectorType 10872;
BA_ "SigType" SG_ 2633719038 Detector1Data 1;
BA_ "SPN" SG_ 2633719038 Detector1Data 10871;
BA_ "SPN" SG_ 2633719038 Detector1DetectorDataSLOT 10870;
BA_ "SPN" SG_ 2633719038 Detector1DetectorType 10869;
BA_ "SigType" SG_ 2633718782 Detector8Data 1;
BA_ "SPN" SG_ 2633718782 Detector8Data 10868;
BA_ "SPN" SG_ 2633718782 Detector8DetectorDataSLOT 10867;
BA_ "SPN" SG_ 2633718782 Detector8DetectorType 10866;
BA_ "SigType" SG_ 2633718782 Detector7Data 1;
BA_ "SPN" SG_ 2633718782 Detector7Data 10865;
BA_ "SPN" SG_ 2633718782 Detector7DetectorDataSLOT 10864;
BA_ "SPN" SG_ 2633718782 Detector7DetectorType 10863;
BA_ "SigType" SG_ 2633718782 Detector6Data 1;
BA_ "SPN" SG_ 2633718782 Detector6Data 10862;
BA_ "SPN" SG_ 2633718782 Detector6DetectorDataSLOT 10861;
BA_ "SPN" SG_ 2633718782 Detector6DetectorType 10860;
BA_ "SigType" SG_ 2633718782 Detector5Data 1;
BA_ "SPN" SG_ 2633718782 Detector5Data 10859;
BA_ "SPN" SG_ 2633718782 Detector5DetectorDataSLOT 10858;
BA_ "SPN" SG_ 2633718782 Detector5DetectorType 10857;
BA_ "SigType" SG_ 2633718782 Detector4Data 1;
BA_ "SPN" SG_ 2633718782 Detector4Data 10856;
BA_ "SPN" SG_ 2633718782 Detector4DetectorDataSLOT 10855;
BA_ "SPN" SG_ 2633718782 Detector4DetectorType 10854;
BA_ "SigType" SG_ 2633718782 Detector3Data 1;
BA_ "SPN" SG_ 2633718782 Detector3Data 10853;
BA_ "SPN" SG_ 2633718782 Detector3DetectorDataSLOT 10852;
BA_ "SPN" SG_ 2633718782 Detector3DetectorType 10851;
BA_ "SigType" SG_ 2633718782 Detector2Data 1;
BA_ "SPN" SG_ 2633718782 Detector2Data 10850;
BA_ "SPN" SG_ 2633718782 Detector2DetectorDataSLOT 10849;
BA_ "SPN" SG_ 2633718782 Detector2DetectorType 10848;
BA_ "SigType" SG_ 2633718782 Detector1Data 1;
BA_ "SPN" SG_ 2633718782 Detector1Data 10847;
BA_ "SPN" SG_ 2633718782 Detector1DetectorDataSLOT 10846;
BA_ "SPN" SG_ 2633718782 Detector1DetectorType 10845;
BA_ "SPN" SG_ 2566609662 NomRatedCapacity 15261;
BA_ "SigType" SG_ 2566609662 CellMinVLmt 1;
BA_ "SPN" SG_ 2566609662 CellMinVLmt 11140;
BA_ "SigType" SG_ 2566609662 CellMaxVLmt 1;
BA_ "SPN" SG_ 2566609662 CellMaxVLmt 11139;
BA_ "SigType" SG_ 2566609662 RecommendedMinOperatingTemp 1;
BA_ "SPN" SG_ 2566609662 RecommendedMinOperatingTemp 11138;
BA_ "SigType" SG_ 2566609662 RecommendedMaxOperatingTemp 1;
BA_ "SPN" SG_ 2566609662 RecommendedMaxOperatingTemp 11137;
BA_ "SigType" SG_ 2566609662 RecommendedMaxStOfCharge 1;
BA_ "SPN" SG_ 2566609662 RecommendedMaxStOfCharge 11136;
BA_ "SigType" SG_ 2566609662 RecommendedMinStOfCharge 1;
BA_ "SPN" SG_ 2566609662 RecommendedMinStOfCharge 11135;
BA_ "SigType" SG_ 2566609662 RecommendedMaxOperatingV 1;
BA_ "SPN" SG_ 2566609662 RecommendedMaxOperatingV 11134;
BA_ "SigType" SG_ 2566609662 RecommendedMinOperatingV 1;
BA_ "SPN" SG_ 2566609662 RecommendedMinOperatingV 11133;
BA_ "SigType" SG_ 2566609662 NomV 1;
BA_ "SPN" SG_ 2566609662 NomV 11132;
BA_ "SigType" SG_ 2633718270 TotalEnergyOut 1;
BA_ "SPN" SG_ 2633718270 TotalEnergyOut 13368;
BA_ "SigType" SG_ 2633718270 TotalEnergyInput 1;
BA_ "SPN" SG_ 2633718270 TotalEnergyInput 13367;
BA_ "SigType" SG_ 2633718270 TotalAccumulatedCharge 1;
BA_ "SPN" SG_ 2633718270 TotalAccumulatedCharge 11144;
BA_ "SigType" SG_ 2633718270 TotalEnergyThroughput 1;
BA_ "SPN" SG_ 2633718270 TotalEnergyThroughput 11143;
BA_ "SigType" SG_ 2633718270 ContactorOpenUnderLoadCount 1;
BA_ "SPN" SG_ 2633718270 ContactorOpenUnderLoadCount 11142;
BA_ "SigType" SG_ 2633718270 StOfHealth 1;
BA_ "SPN" SG_ 2633718270 StOfHealth 11141;
BA_ "SPN" SG_ 2566609150 NomRatedCapacity 15260;
BA_ "SigType" SG_ 2566609150 CellMinVLmt 1;
BA_ "SPN" SG_ 2566609150 CellMinVLmt 11256;
BA_ "SigType" SG_ 2566609150 CellMaxVLmt 1;
BA_ "SPN" SG_ 2566609150 CellMaxVLmt 11255;
BA_ "SigType" SG_ 2566609150 RecommendedMinOperatingTemp 1;
BA_ "SPN" SG_ 2566609150 RecommendedMinOperatingTemp 11254;
BA_ "SigType" SG_ 2566609150 RecommendedMaxOperatingTemp 1;
BA_ "SPN" SG_ 2566609150 RecommendedMaxOperatingTemp 11253;
BA_ "SigType" SG_ 2566609150 RecommendedMaxStOfCharge 1;
BA_ "SPN" SG_ 2566609150 RecommendedMaxStOfCharge 11252;
BA_ "SigType" SG_ 2566609150 RecommendedMinStOfCharge 1;
BA_ "SPN" SG_ 2566609150 RecommendedMinStOfCharge 11251;
BA_ "SigType" SG_ 2566609150 RecommendedMaxOperatingV 1;
BA_ "SPN" SG_ 2566609150 RecommendedMaxOperatingV 11250;
BA_ "SigType" SG_ 2566609150 RecommendedMinOperatingV 1;
BA_ "SPN" SG_ 2566609150 RecommendedMinOperatingV 11249;
BA_ "SigType" SG_ 2566609150 NomV 1;
BA_ "SPN" SG_ 2566609150 NomV 11248;
BA_ "SigType" SG_ 2633717758 TotalEnergyOut 1;
BA_ "SPN" SG_ 2633717758 TotalEnergyOut 13370;
BA_ "SigType" SG_ 2633717758 TotalEnergyInput 1;
BA_ "SPN" SG_ 2633717758 TotalEnergyInput 13369;
BA_ "SigType" SG_ 2633717758 TotalAccumulatedCharge 1;
BA_ "SPN" SG_ 2633717758 TotalAccumulatedCharge 11260;
BA_ "SigType" SG_ 2633717758 TotalEnergyThroughput 1;
BA_ "SPN" SG_ 2633717758 TotalEnergyThroughput 11259;
BA_ "SigType" SG_ 2633717758 ContactorOpenUnderLoadCount 1;
BA_ "SPN" SG_ 2633717758 ContactorOpenUnderLoadCount 11258;
BA_ "SigType" SG_ 2633717758 StOfHealth 1;
BA_ "SPN" SG_ 2633717758 StOfHealth 11257;
BA_ "SPN" SG_ 2566608638 NomRatedCapacity 15259;
BA_ "SigType" SG_ 2566608638 CellMinVLmt 1;
BA_ "SPN" SG_ 2566608638 CellMinVLmt 11372;
BA_ "SigType" SG_ 2566608638 CellMaxVLmt 1;
BA_ "SPN" SG_ 2566608638 CellMaxVLmt 11371;
BA_ "SigType" SG_ 2566608638 RecommendedMinOperatingTemp 1;
BA_ "SPN" SG_ 2566608638 RecommendedMinOperatingTemp 11370;
BA_ "SigType" SG_ 2566608638 RecommendedMaxOperatingTemp 1;
BA_ "SPN" SG_ 2566608638 RecommendedMaxOperatingTemp 11369;
BA_ "SigType" SG_ 2566608638 RecommendedMaxStOfCharge 1;
BA_ "SPN" SG_ 2566608638 RecommendedMaxStOfCharge 11368;
BA_ "SigType" SG_ 2566608638 RecommendedMinStOfCharge 1;
BA_ "SPN" SG_ 2566608638 RecommendedMinStOfCharge 11367;
BA_ "SigType" SG_ 2566608638 RecommendedMaxOperatingV 1;
BA_ "SPN" SG_ 2566608638 RecommendedMaxOperatingV 11366;
BA_ "SigType" SG_ 2566608638 RecommendedMinOperatingV 1;
BA_ "SPN" SG_ 2566608638 RecommendedMinOperatingV 11365;
BA_ "SigType" SG_ 2566608638 NomV 1;
BA_ "SPN" SG_ 2566608638 NomV 11364;
BA_ "SigType" SG_ 2633717246 TotalEnergyOut 1;
BA_ "SPN" SG_ 2633717246 TotalEnergyOut 13372;
BA_ "SigType" SG_ 2633717246 TotalEnergyInput 1;
BA_ "SPN" SG_ 2633717246 TotalEnergyInput 13371;
BA_ "SigType" SG_ 2633717246 TotalAccumulatedCharge 1;
BA_ "SPN" SG_ 2633717246 TotalAccumulatedCharge 11376;
BA_ "SigType" SG_ 2633717246 TotalEnergyThroughput 1;
BA_ "SPN" SG_ 2633717246 TotalEnergyThroughput 11375;
BA_ "SigType" SG_ 2633717246 ContactorOpenUnderLoadCount 1;
BA_ "SPN" SG_ 2633717246 ContactorOpenUnderLoadCount 11374;
BA_ "SigType" SG_ 2633717246 StOfHealth 1;
BA_ "SPN" SG_ 2633717246 StOfHealth 11373;
BA_ "SPN" SG_ 2566608126 NomRatedCapacity 15258;
BA_ "SigType" SG_ 2566608126 CellMinVLmt 1;
BA_ "SPN" SG_ 2566608126 CellMinVLmt 11488;
BA_ "SigType" SG_ 2566608126 CellMaxVLmt 1;
BA_ "SPN" SG_ 2566608126 CellMaxVLmt 11487;
BA_ "SigType" SG_ 2566608126 RecommendedMinOperatingTemp 1;
BA_ "SPN" SG_ 2566608126 RecommendedMinOperatingTemp 11486;
BA_ "SigType" SG_ 2566608126 RecommendedMaxOperatingTemp 1;
BA_ "SPN" SG_ 2566608126 RecommendedMaxOperatingTemp 11485;
BA_ "SigType" SG_ 2566608126 RecommendedMaxStOfCharge 1;
BA_ "SPN" SG_ 2566608126 RecommendedMaxStOfCharge 11484;
BA_ "SigType" SG_ 2566608126 RecommendedMinStOfCharge 1;
BA_ "SPN" SG_ 2566608126 RecommendedMinStOfCharge 11483;
BA_ "SigType" SG_ 2566608126 RecommendedMaxOperatingV 1;
BA_ "SPN" SG_ 2566608126 RecommendedMaxOperatingV 11482;
BA_ "SigType" SG_ 2566608126 RecommendedMinOperatingV 1;
BA_ "SPN" SG_ 2566608126 RecommendedMinOperatingV 11481;
BA_ "SigType" SG_ 2566608126 NomV 1;
BA_ "SPN" SG_ 2566608126 NomV 11480;
BA_ "SigType" SG_ 2633716734 TotalEnergyOut 1;
BA_ "SPN" SG_ 2633716734 TotalEnergyOut 13374;
BA_ "SigType" SG_ 2633716734 TotalEnergyInput 1;
BA_ "SPN" SG_ 2633716734 TotalEnergyInput 13373;
BA_ "SigType" SG_ 2633716734 TotalAccumulatedCharge 1;
BA_ "SPN" SG_ 2633716734 TotalAccumulatedCharge 11492;
BA_ "SigType" SG_ 2633716734 TotalEnergyThroughput 1;
BA_ "SPN" SG_ 2633716734 TotalEnergyThroughput 11491;
BA_ "SigType" SG_ 2633716734 ContactorOpenUnderLoadCount 1;
BA_ "SPN" SG_ 2633716734 ContactorOpenUnderLoadCount 11490;
BA_ "SigType" SG_ 2633716734 StOfHealth 1;
BA_ "SPN" SG_ 2633716734 StOfHealth 11489;
BA_ "SPN" SG_ 2566607614 NomRatedCapacity 15257;
BA_ "SigType" SG_ 2566607614 CellMinVLmt 1;
BA_ "SPN" SG_ 2566607614 CellMinVLmt 11604;
BA_ "SigType" SG_ 2566607614 CellMaxVLmt 1;
BA_ "SPN" SG_ 2566607614 CellMaxVLmt 11603;
BA_ "SigType" SG_ 2566607614 RecommendedMinOperatingTemp 1;
BA_ "SPN" SG_ 2566607614 RecommendedMinOperatingTemp 11602;
BA_ "SigType" SG_ 2566607614 RecommendedMaxOperatingTemp 1;
BA_ "SPN" SG_ 2566607614 RecommendedMaxOperatingTemp 11601;
BA_ "SigType" SG_ 2566607614 RecommendedMaxStOfCharge 1;
BA_ "SPN" SG_ 2566607614 RecommendedMaxStOfCharge 11600;
BA_ "SigType" SG_ 2566607614 RecommendedMinStOfCharge 1;
BA_ "SPN" SG_ 2566607614 RecommendedMinStOfCharge 11599;
BA_ "SigType" SG_ 2566607614 RecommendedMaxOperatingV 1;
BA_ "SPN" SG_ 2566607614 RecommendedMaxOperatingV 11598;
BA_ "SigType" SG_ 2566607614 RecommendedMinOperatingV 1;
BA_ "SPN" SG_ 2566607614 RecommendedMinOperatingV 11597;
BA_ "SigType" SG_ 2566607614 NomV 1;
BA_ "SPN" SG_ 2566607614 NomV 11596;
BA_ "SigType" SG_ 2633716222 TotalEnergyOut 1;
BA_ "SPN" SG_ 2633716222 TotalEnergyOut 13376;
BA_ "SigType" SG_ 2633716222 TotalEnergyInput 1;
BA_ "SPN" SG_ 2633716222 TotalEnergyInput 13375;
BA_ "SigType" SG_ 2633716222 TotalAccumulatedCharge 1;
BA_ "SPN" SG_ 2633716222 TotalAccumulatedCharge 11608;
BA_ "SigType" SG_ 2633716222 TotalEnergyThroughput 1;
BA_ "SPN" SG_ 2633716222 TotalEnergyThroughput 11607;
BA_ "SigType" SG_ 2633716222 ContactorOpenUnderLoadCount 1;
BA_ "SPN" SG_ 2633716222 ContactorOpenUnderLoadCount 11606;
BA_ "SigType" SG_ 2633716222 StOfHealth 1;
BA_ "SPN" SG_ 2633716222 StOfHealth 11605;
BA_ "SPN" SG_ 2566607102 NomRatedCapacity 15256;
BA_ "SigType" SG_ 2566607102 CellMinVLmt 1;
BA_ "SPN" SG_ 2566607102 CellMinVLmt 11720;
BA_ "SigType" SG_ 2566607102 CellMaxVLmt 1;
BA_ "SPN" SG_ 2566607102 CellMaxVLmt 11719;
BA_ "SigType" SG_ 2566607102 RecommendedMinOperatingTemp 1;
BA_ "SPN" SG_ 2566607102 RecommendedMinOperatingTemp 11718;
BA_ "SigType" SG_ 2566607102 RecommendedMaxOperatingTemp 1;
BA_ "SPN" SG_ 2566607102 RecommendedMaxOperatingTemp 11717;
BA_ "SigType" SG_ 2566607102 RecommendedMaxStOfCharge 1;
BA_ "SPN" SG_ 2566607102 RecommendedMaxStOfCharge 11716;
BA_ "SigType" SG_ 2566607102 RecommendedMinStOfCharge 1;
BA_ "SPN" SG_ 2566607102 RecommendedMinStOfCharge 11715;
BA_ "SigType" SG_ 2566607102 RecommendedMaxOperatingV 1;
BA_ "SPN" SG_ 2566607102 RecommendedMaxOperatingV 11714;
BA_ "SigType" SG_ 2566607102 RecommendedMinOperatingV 1;
BA_ "SPN" SG_ 2566607102 RecommendedMinOperatingV 11713;
BA_ "SigType" SG_ 2566607102 NomV 1;
BA_ "SPN" SG_ 2566607102 NomV 11712;
BA_ "SigType" SG_ 2633715710 TotalEnergyOut 1;
BA_ "SPN" SG_ 2633715710 TotalEnergyOut 13378;
BA_ "SigType" SG_ 2633715710 TotalEnergyInput 1;
BA_ "SPN" SG_ 2633715710 TotalEnergyInput 13377;
BA_ "SigType" SG_ 2633715710 TotalAccumulatedCharge 1;
BA_ "SPN" SG_ 2633715710 TotalAccumulatedCharge 11724;
BA_ "SigType" SG_ 2633715710 TotalEnergyThroughput 1;
BA_ "SPN" SG_ 2633715710 TotalEnergyThroughput 11723;
BA_ "SigType" SG_ 2633715710 ContactorOpenUnderLoadCount 1;
BA_ "SPN" SG_ 2633715710 ContactorOpenUnderLoadCount 11722;
BA_ "SigType" SG_ 2633715710 StOfHealth 1;
BA_ "SPN" SG_ 2633715710 StOfHealth 11721;
BA_ "SigType" SG_ 2499497726 LeverDetentPosStatus 4;
BA_ "SPN" SG_ 2499497726 LeverDetentPosStatus 11728;
BA_ "SigType" SG_ 2499497726 LeverPos 1;
BA_ "GenSigStartValue" SG_ 2499497726 LeverPos 10000;
BA_ "SPN" SG_ 2499497726 LeverPos 11727;
BA_ "SigType" SG_ 2566606334 TransOIlFilterLifeRemaining 1;
BA_ "SPN" SG_ 2566606334 TransOIlFilterLifeRemaining 11744;
BA_ "SigType" SG_ 2566606334 EngOilFilterLifeRemaining 1;
BA_ "SPN" SG_ 2566606334 EngOilFilterLifeRemaining 11743;
BA_ "SigType" SG_ 2566606334 EngFuelFilterLifeRemaining11742 1;
BA_ "SPN" SG_ 2566606334 EngFuelFilterLifeRemaining11742 11742;
BA_ "SigType" SG_ 2566606334 EngFuelFilterLifeRemaining 1;
BA_ "SPN" SG_ 2566606334 EngFuelFilterLifeRemaining 11741;
BA_ "SigType" SG_ 2566606334 EngAirFilter4LifeRemaining 1;
BA_ "SPN" SG_ 2566606334 EngAirFilter4LifeRemaining 11740;
BA_ "SigType" SG_ 2566606334 EngAirFilter3LifeRemaining 1;
BA_ "SPN" SG_ 2566606334 EngAirFilter3LifeRemaining 11739;
BA_ "SigType" SG_ 2566606334 EngAirFilter2LifeRemaining 1;
BA_ "SPN" SG_ 2566606334 EngAirFilter2LifeRemaining 11738;
BA_ "SigType" SG_ 2566606334 EngAirFilter1LifeRemaining 1;
BA_ "SPN" SG_ 2566606334 EngAirFilter1LifeRemaining 11737;
BA_ "SigType" SG_ 2566606078 A_CCompressorPwr 1;
BA_ "SPN" SG_ 2566606078 A_CCompressorPwr 20464;
BA_ "SigType" SG_ 2566606078 HtrPwr 1;
BA_ "SPN" SG_ 2566606078 HtrPwr 11755;
BA_ "SPN" SG_ 2566605822 VSCtrlOpSt 21168;
BA_ "SigType" SG_ 2566605822 VSCtrlCmdFeedback 1;
BA_ "SPN" SG_ 2566605822 VSCtrlCmdFeedback 15251;
BA_ "SPN" SG_ 2566605822 SAOfCtrlDeviceForVehSpdCtrlCmd 15250;
BA_ "SigType" SG_ 2566605822 VSCtrlCmdReadinessStatus 5;
BA_ "SPN" SG_ 2566605822 VSCtrlCmdReadinessStatus 15249;
BA_ "SigType" SG_ 2566605822 TSC1CtrlPurpP7ReadinessStatus 5;
BA_ "SPN" SG_ 2566605822 TSC1CtrlPurpP7ReadinessStatus 11757;
BA_ "SPN" SG_ 2566605822 SAOfCtrlDeviceForTSC1CtrlPurpP7 11756;
BA_ "SigType" SG_ 2566605566 TrqLimDueToMachineCharacter_0001 4;
BA_ "SPN" SG_ 2566605566 TrqLimDueToMachineCharacter_0001 13052;
BA_ "SystemSignalLongSymbol" SG_ 2566605566 TrqLimDueToMachineCharacter_0001 "TrqLimDueToMachineCharacteristics";
BA_ "SigType" SG_ 2566605566 PLedDueToActiveSpdRateLmt 4;
BA_ "SPN" SG_ 2566605566 PLedDueToActiveSpdRateLmt 13051;
BA_ "SigType" SG_ 2566605566 PLedDueToActiveTrqRateLmt 4;
BA_ "SPN" SG_ 2566605566 PLedDueToActiveTrqRateLmt 13050;
BA_ "SigType" SG_ 2566605566 PLedDueToFaultCondition 4;
BA_ "SPN" SG_ 2566605566 PLedDueToFaultCondition 13049;
BA_ "SigType" SG_ 2566605566 PLedDueToMotorTemp 4;
BA_ "SPN" SG_ 2566605566 PLedDueToMotorTemp 11903;
BA_ "SigType" SG_ 2566605566 PLedDueToInvTemp 4;
BA_ "SPN" SG_ 2566605566 PLedDueToInvTemp 11902;
BA_ "SigType" SG_ 2566605566 PLedDueToSpdMin 4;
BA_ "SPN" SG_ 2566605566 PLedDueToSpdMin 11901;
BA_ "SigType" SG_ 2566605566 PLedDueToSpdMax 4;
BA_ "SPN" SG_ 2566605566 PLedDueToSpdMax 11900;
BA_ "SigType" SG_ 2566605566 PLedDueToTrqMin 4;
BA_ "SPN" SG_ 2566605566 PLedDueToTrqMin 11899;
BA_ "SigType" SG_ 2566605566 PLedDueToTrqMax 4;
BA_ "SPN" SG_ 2566605566 PLedDueToTrqMax 11898;
BA_ "SigType" SG_ 2566605566 PLedDueToDCSidePwrMin 4;
BA_ "SPN" SG_ 2566605566 PLedDueToDCSidePwrMin 11897;
BA_ "SigType" SG_ 2566605566 PLedDueToDCSidePwrMax 4;
BA_ "SPN" SG_ 2566605566 PLedDueToDCSidePwrMax 11896;
BA_ "SigType" SG_ 2566605566 PLedDueToMechPwrMin 4;
BA_ "SPN" SG_ 2566605566 PLedDueToMechPwrMin 11895;
BA_ "SigType" SG_ 2566605566 PLedDueToMechPwrMax 4;
BA_ "SPN" SG_ 2566605566 PLedDueToMechPwrMax 11894;
BA_ "SigType" SG_ 2566605566 PLedDueToDCSideVMin 4;
BA_ "SPN" SG_ 2566605566 PLedDueToDCSideVMin 11893;
BA_ "SigType" SG_ 2566605566 PLedDueToDCSideVMax 4;
BA_ "SPN" SG_ 2566605566 PLedDueToDCSideVMax 11892;
BA_ "SigType" SG_ 2566605566 PLedDueToDCSideCurMin 4;
BA_ "SPN" SG_ 2566605566 PLedDueToDCSideCurMin 11891;
BA_ "SigType" SG_ 2566605566 PLedDueToDCSideCurMax 4;
BA_ "SPN" SG_ 2566605566 PLedDueToDCSideCurMax 11890;
BA_ "SigType" SG_ 2566605566 PLedDueToUndefinedReason 4;
BA_ "SPN" SG_ 2566605566 PLedDueToUndefinedReason 11889;
BA_ "SigType" SG_ 2566605310 HVBusPassiveIsolTestResults 1;
BA_ "SPN" SG_ 2566605310 HVBusPassiveIsolTestResults 11888;
BA_ "SigType" SG_ 2566605310 HVBusActiveIsolTestResults 1;
BA_ "SPN" SG_ 2566605310 HVBusActiveIsolTestResults 11887;
BA_ "SPN" SG_ 2566605310 HVBusPassiveIsolTestStatus 11886;
BA_ "SPN" SG_ 2566605310 HVBusActiveIsolTestStatus 11885;
BA_ "SPN" SG_ 2566605310 DCSideNegToChassisGroundV 11884;
BA_ "SigType" SG_ 2566605310 Counter 11;
BA_ "SPN" SG_ 2566605310 Counter 11883;
BA_ "SigType" SG_ 2566605310 CRC 12;
BA_ "SPN" SG_ 2566605310 CRC 11882;
BA_ "SigType" SG_ 2566605054 Temp4 1;
BA_ "SPN" SG_ 2566605054 Temp4 11873;
BA_ "SigType" SG_ 2566605054 Temp3 1;
BA_ "SPN" SG_ 2566605054 Temp3 11872;
BA_ "SigType" SG_ 2566605054 Temp2 1;
BA_ "SPN" SG_ 2566605054 Temp2 11871;
BA_ "SigType" SG_ 2566605054 Temp1 1;
BA_ "SPN" SG_ 2566605054 Temp1 11802;
BA_ "SigType" SG_ 2566604798 Five 1;
BA_ "SPN" SG_ 2566604798 Five 20916;
BA_ "SigType" SG_ 2566604798 Four 1;
BA_ "SPN" SG_ 2566604798 Four 11870;
BA_ "SigType" SG_ 2566604798 Three 1;
BA_ "SPN" SG_ 2566604798 Three 11869;
BA_ "SigType" SG_ 2566604798 Two 1;
BA_ "SPN" SG_ 2566604798 Two 11868;
BA_ "SigType" SG_ 2566604798 One 1;
BA_ "SPN" SG_ 2566604798 One 11867;
BA_ "SigType" SG_ 2365277950 V 1;
BA_ "SPN" SG_ 2365277950 V 11854;
BA_ "SigType" SG_ 2365277950 Cur 1;
BA_ "SPN" SG_ 2365277950 Cur 11853;
BA_ "SigType" SG_ 2365277950 Counter 11;
BA_ "SPN" SG_ 2365277950 Counter 11852;
BA_ "SigType" SG_ 2365277950 CRC 12;
BA_ "SPN" SG_ 2365277950 CRC 11851;
BA_ "SPN" SG_ 2365277694 DCSideV 11804;
BA_ "SPN" SG_ 2365277694 DCSideCur 11826;
BA_ "SigType" SG_ 2365277694 Spd 1;
BA_ "SPN" SG_ 2365277694 Spd 11801;
BA_ "SPN" SG_ 2365277694 Trq 11803;
BA_ "SigType" SG_ 2365277694 Counter 11;
BA_ "SPN" SG_ 2365277694 Counter 11825;
BA_ "SigType" SG_ 2365277694 CRC 12;
BA_ "SPN" SG_ 2365277694 CRC 11824;
BA_ "SigType" SG_ 2365277438 Pwr 1;
BA_ "SPN" SG_ 2365277438 Pwr 11823;
BA_ "SigType" SG_ 2365277438 Spd 1;
BA_ "SPN" SG_ 2365277438 Spd 11822;
BA_ "SigType" SG_ 2365277438 Trq 1;
BA_ "SPN" SG_ 2365277438 Trq 11821;
BA_ "SigType" SG_ 2365277438 Counter 11;
BA_ "SPN" SG_ 2365277438 Counter 11820;
BA_ "SigType" SG_ 2365277438 CRC 12;
BA_ "SPN" SG_ 2365277438 CRC 11819;
BA_ "SigType" SG_ 2566603774 TrqLimDueToMachineCharacter_0002 4;
BA_ "SPN" SG_ 2566603774 TrqLimDueToMachineCharacter_0002 13056;
BA_ "SystemSignalLongSymbol" SG_ 2566603774 TrqLimDueToMachineCharacter_0002 "TrqLimDueToMachineCharacteristics";
BA_ "SigType" SG_ 2566603774 PLedDueToActiveSpdRateLmt 4;
BA_ "SPN" SG_ 2566603774 PLedDueToActiveSpdRateLmt 13055;
BA_ "SigType" SG_ 2566603774 PLedDueToActiveTrqRateLmt 4;
BA_ "SPN" SG_ 2566603774 PLedDueToActiveTrqRateLmt 13054;
BA_ "SigType" SG_ 2566603774 PLedDueToFaultCondition 4;
BA_ "SPN" SG_ 2566603774 PLedDueToFaultCondition 13053;
BA_ "SigType" SG_ 2566603774 PLedDueToMotorTemp 4;
BA_ "SPN" SG_ 2566603774 PLedDueToMotorTemp 12021;
BA_ "SigType" SG_ 2566603774 PLedDueToInvTemp 4;
BA_ "SPN" SG_ 2566603774 PLedDueToInvTemp 12020;
BA_ "SigType" SG_ 2566603774 PLedDueToSpdMin 4;
BA_ "SPN" SG_ 2566603774 PLedDueToSpdMin 12019;
BA_ "SigType" SG_ 2566603774 PLedDueToSpdMax 4;
BA_ "SPN" SG_ 2566603774 PLedDueToSpdMax 12018;
BA_ "SigType" SG_ 2566603774 PLedDueToTrqMin 4;
BA_ "SPN" SG_ 2566603774 PLedDueToTrqMin 12017;
BA_ "SigType" SG_ 2566603774 PLedDueToTrqMax 4;
BA_ "SPN" SG_ 2566603774 PLedDueToTrqMax 12016;
BA_ "SigType" SG_ 2566603774 PLedDueToDCSidePwrMin 4;
BA_ "SPN" SG_ 2566603774 PLedDueToDCSidePwrMin 12015;
BA_ "SigType" SG_ 2566603774 PLedDueToDCSidePwrMax 4;
BA_ "SPN" SG_ 2566603774 PLedDueToDCSidePwrMax 12014;
BA_ "SigType" SG_ 2566603774 PLedDueToMechPwrMin 4;
BA_ "SPN" SG_ 2566603774 PLedDueToMechPwrMin 12013;
BA_ "SigType" SG_ 2566603774 PLedDueToMechPwrMax 4;
BA_ "SPN" SG_ 2566603774 PLedDueToMechPwrMax 12012;
BA_ "SigType" SG_ 2566603774 PLedDueToDCSideVMin 4;
BA_ "SPN" SG_ 2566603774 PLedDueToDCSideVMin 12011;
BA_ "SigType" SG_ 2566603774 PLedDueToDCSideVMax 4;
BA_ "SPN" SG_ 2566603774 PLedDueToDCSideVMax 12010;
BA_ "SigType" SG_ 2566603774 PLedDueToDCSideCurMin 4;
BA_ "SPN" SG_ 2566603774 PLedDueToDCSideCurMin 12009;
BA_ "SigType" SG_ 2566603774 PLedDueToDCSideCurMax 4;
BA_ "SPN" SG_ 2566603774 PLedDueToDCSideCurMax 12008;
BA_ "SigType" SG_ 2566603774 PLedDueToUndefinedReason 4;
BA_ "SPN" SG_ 2566603774 PLedDueToUndefinedReason 12007;
BA_ "SigType" SG_ 2566603518 HVBusPassiveIsolTestResults 1;
BA_ "SPN" SG_ 2566603518 HVBusPassiveIsolTestResults 12006;
BA_ "SigType" SG_ 2566603518 HVBusActiveIsolTestResults 1;
BA_ "SPN" SG_ 2566603518 HVBusActiveIsolTestResults 12005;
BA_ "SPN" SG_ 2566603518 HVBusPassiveIsolTestStatus 12004;
BA_ "SPN" SG_ 2566603518 HVBusActiveIsolTestStatus 12003;
BA_ "SPN" SG_ 2566603518 DCSideNegToChassisGroundV 12002;
BA_ "SigType" SG_ 2566603518 Counter 11;
BA_ "SPN" SG_ 2566603518 Counter 12001;
BA_ "SigType" SG_ 2566603518 CRC 12;
BA_ "SPN" SG_ 2566603518 CRC 12000;
BA_ "SigType" SG_ 2566603262 Temp4 1;
BA_ "SPN" SG_ 2566603262 Temp4 11991;
BA_ "SigType" SG_ 2566603262 Temp3 1;
BA_ "SPN" SG_ 2566603262 Temp3 11990;
BA_ "SigType" SG_ 2566603262 Temp2 1;
BA_ "SPN" SG_ 2566603262 Temp2 11989;
BA_ "SigType" SG_ 2566603262 Temp1 1;
BA_ "SPN" SG_ 2566603262 Temp1 11920;
VAL_ 2566612990 TrqLimDueToMachineCharacter_0000 3 "Not Available" 2 "Error" 1 "Torque limited for this reason" 0 "No torque limit for this reason" ;
VAL_ 2566612990 PLedDueToActiveSpdRateLmt 3 "Not Available" 2 "Error" 1 "Power limited for this reason" 0 "No power limit for this reason" ;
VAL_ 2566612990 PLedDueToActiveTrqRateLmt 3 "Not Available" 2 "Error" 1 "Power limited for this reason" 0 "No power limit for this reason" ;
VAL_ 2566612990 PLedDueToFaultCondition 3 "Not Available" 2 "Error" 1 "Power limited for this reason" 0 "No power limit for this reason" ;
VAL_ 2566612990 PLedDueToMotorTemp 3 "Not Available" 2 "Error" 1 "Power limited for this reason" 0 "No power limit for this reason" ;
VAL_ 2566612990 PLedDueToInvTemp 3 "Not Available" 2 "Error" 1 "Power limited for this reason" 0 "No power limit for this reason" ;
VAL_ 2566612990 PLedDueToSpdMin 3 "Not Available" 2 "Error" 1 "Power limited for this reason" 0 "No power limit for this reason" ;
VAL_ 2566612990 PLedDueToSpdMax 3 "Not Available" 2 "Error" 1 "Power limited for this reason" 0 "No power limit for this reason" ;
VAL_ 2566612990 PLedDueToTrqMin 3 "Not Available" 2 "Error" 1 "Power limited for this reason" 0 "No power limit for this reason" ;
VAL_ 2566612990 PLedDueToTrqMax 3 "Not Available" 2 "Error" 1 "Power limited for this reason" 0 "No power limit for this reason" ;
VAL_ 2566612990 PLedDueToDCSidePwrMin 3 "Not Available" 2 "Error" 1 "Power limited for this reason" 0 "No power limit for this reason" ;
VAL_ 2566612990 PLedDueToDCSidePwrMax 3 "Not Available" 2 "Error" 1 "Power limited for this reason" 0 "No power limit for this reason" ;
VAL_ 2566612990 PLedDueToMechPwrMin 3 "Not Available" 2 "Error" 1 "Power limited for this reason" 0 "No power limit for this reason" ;
VAL_ 2566612990 PLedDueToMechPwrMax 3 "Not Available" 2 "Error" 1 "Power limited for this reason" 0 "No power limit for this reason" ;
VAL_ 2566612990 PLedDueToDCSideVMin 3 "Not Available" 2 "Error" 1 "Power limited for this reason" 0 "No power limit for this reason" ;
VAL_ 2566612990 PLedDueToDCSideVMax 3 "Not Available" 2 "Error" 1 "Power limited for this reason" 0 "No power limit for this reason" ;
VAL_ 2566612990 PLedDueToDCSideCurMin 3 "Not Available" 2 "Error" 1 "Power limited for this reason" 0 "No power limit for this reason" ;
VAL_ 2566612990 PLedDueToDCSideCurMax 3 "Not Available" 2 "Error" 1 "Power limited for this reason" 0 "No power limit for this reason" ;
VAL_ 2566612990 PLedDueToUndefinedReason 3 "Not Available" 2 "Error" 1 "Power limited for this reason" 0 "No power limit for this reason" ;
VAL_ 2633719550 Detector8DetectorDataSLOT 15 "Not available or not installed" 14 "SAE reserved" 13 "SAE reserved" 12 "SAE reserved" 11 "SAE reserved" 10 "SAE reserved" 9 "SAE reserved" 8 "SAE reserved" 7 "SAE reserved" 6 "SAE reserved" 5 "SAE reserved" 4 "SAE reserved" 3 "SAEpr12" 2 "SAEtp02" 1 "SAEpc07" 0 "SAEev03" ;
VAL_ 2633719550 Detector8DetectorType 15 "Not available or not installed" 14 "SAE Reserved" 13 "SAE Reserved" 12 "SAE Reserved" 11 "SAE Reserved" 10 "SAE Reserved" 9 "SAE Reserved" 8 "SAE Reserved" 7 "SAE Reserved" 6 "SAE Reserved" 5 "SAE Reserved" 4 "Manual release switch" 3 "Heat detector" 2 "Analog optical sensor" 1 "Analog gas sensor" 0 "Analog thermal sensor" ;
VAL_ 2633719550 Detector7DetectorDataSLOT 15 "Not available or not installed" 14 "SAE reserved" 13 "SAE reserved" 12 "SAE reserved" 11 "SAE reserved" 10 "SAE reserved" 9 "SAE reserved" 8 "SAE reserved" 7 "SAE reserved" 6 "SAE reserved" 5 "SAE reserved" 4 "SAE reserved" 3 "SAEpr12" 2 "SAEtp02" 1 "SAEpc07" 0 "SAEev03" ;
VAL_ 2633719550 Detector7DetectorType 15 "Not available or not installed" 14 "SAE Reserved" 13 "SAE Reserved" 12 "SAE Reserved" 11 "SAE Reserved" 10 "SAE Reserved" 9 "SAE Reserved" 8 "SAE Reserved" 7 "SAE Reserved" 6 "SAE Reserved" 5 "SAE Reserved" 4 "Manual release switch" 3 "Heat detector" 2 "Analog optical sensor" 1 "Analog gas sensor" 0 "Analog thermal sensor" ;
VAL_ 2633719550 Detector6DetectorDataSLOT 15 "Not available or not installed" 14 "SAE reserved" 13 "SAE reserved" 12 "SAE reserved" 11 "SAE reserved" 10 "SAE reserved" 9 "SAE reserved" 8 "SAE reserved" 7 "SAE reserved" 6 "SAE reserved" 5 "SAE reserved" 4 "SAE reserved" 3 "SAEpr12" 2 "SAEtp02" 1 "SAEpc07" 0 "SAEev03" ;
VAL_ 2633719550 Detector6DetectorType 15 "Not available or not installed" 14 "SAE Reserved" 13 "SAE Reserved" 12 "SAE Reserved" 11 "SAE Reserved" 10 "SAE Reserved" 9 "SAE Reserved" 8 "SAE Reserved" 7 "SAE Reserved" 6 "SAE Reserved" 5 "SAE Reserved" 4 "Manual release switch" 3 "Heat detector" 2 "Analog optical sensor" 1 "Analog gas sensor" 0 "Analog thermal sensor" ;
VAL_ 2633719550 Detector5DetectorDataSLOT 15 "Not available or not installed" 14 "SAE reserved" 13 "SAE reserved" 12 "SAE reserved" 11 "SAE reserved" 10 "SAE reserved" 9 "SAE reserved" 8 "SAE reserved" 7 "SAE reserved" 6 "SAE reserved" 5 "SAE reserved" 4 "SAE reserved" 3 "SAEpr12" 2 "SAEtp02" 1 "SAEpc07" 0 "SAEev03" ;
VAL_ 2633719550 Detector5DetectorType 15 "Not available or not installed" 14 "SAE Reserved" 13 "SAE Reserved" 12 "SAE Reserved" 11 "SAE Reserved" 10 "SAE Reserved" 9 "SAE Reserved" 8 "SAE Reserved" 7 "SAE Reserved" 6 "SAE Reserved" 5 "SAE Reserved" 4 "Manual release switch" 3 "Heat detector" 2 "Analog optical sensor" 1 "Analog gas sensor" 0 "Analog thermal sensor" ;
VAL_ 2633719550 Detector4DetectorDataSLOT 15 "Not available or not installed" 14 "SAE reserved" 13 "SAE reserved" 12 "SAE reserved" 11 "SAE reserved" 10 "SAE reserved" 9 "SAE reserved" 8 "SAE reserved" 7 "SAE reserved" 6 "SAE reserved" 5 "SAE reserved" 4 "SAE reserved" 3 "SAEpr12" 2 "SAEtp02" 1 "SAEpc07" 0 "SAEev03" ;
VAL_ 2633719550 Detector4DetectorType 15 "Not available or not installed" 14 "SAE Reserved" 13 "SAE Reserved" 12 "SAE Reserved" 11 "SAE Reserved" 10 "SAE Reserved" 9 "SAE Reserved" 8 "SAE Reserved" 7 "SAE Reserved" 6 "SAE Reserved" 5 "SAE Reserved" 4 "Manual release switch" 3 "Heat detector" 2 "Analog optical sensor" 1 "Analog gas sensor" 0 "Analog thermal sensor" ;
VAL_ 2633719550 Detector3DetectorDataSLOT 15 "Not available or not installed" 14 "SAE reserved" 13 "SAE reserved" 12 "SAE reserved" 11 "SAE reserved" 10 "SAE reserved" 9 "SAE reserved" 8 "SAE reserved" 7 "SAE reserved" 6 "SAE reserved" 5 "SAE reserved" 4 "SAE reserved" 3 "SAEpr12" 2 "SAEtp02" 1 "SAEpc07" 0 "SAEev03" ;
VAL_ 2633719550 Detector3DetectorType 15 "Not available or not installed" 14 "SAE Reserved" 13 "SAE Reserved" 12 "SAE Reserved" 11 "SAE Reserved" 10 "SAE Reserved" 9 "SAE Reserved" 8 "SAE Reserved" 7 "SAE Reserved" 6 "SAE Reserved" 5 "SAE Reserved" 4 "Manual release switch" 3 "Heat detector" 2 "Analog optical sensor" 1 "Analog gas sensor" 0 "Analog thermal sensor" ;
VAL_ 2633719550 Detector2DetectorDataSLOT 15 "Not available or not installed" 14 "SAE reserved" 13 "SAE reserved" 12 "SAE reserved" 11 "SAE reserved" 10 "SAE reserved" 9 "SAE reserved" 8 "SAE reserved" 7 "SAE reserved" 6 "SAE reserved" 5 "SAE reserved" 4 "SAE reserved" 3 "SAEpr12" 2 "SAEtp02" 1 "SAEpc07" 0 "SAEev03" ;
VAL_ 2633719550 Detector2DetectorType 15 "Not available or not installed" 14 "SAE Reserved" 13 "SAE Reserved" 12 "SAE Reserved" 11 "SAE Reserved" 10 "SAE Reserved" 9 "SAE Reserved" 8 "SAE Reserved" 7 "SAE Reserved" 6 "SAE Reserved" 5 "SAE Reserved" 4 "Manual release switch" 3 "Heat detector" 2 "Analog optical sensor" 1 "Analog gas sensor" 0 "Analog thermal sensor" ;
VAL_ 2633719550 Detector1DetectorDataSLOT 15 "Not available or not installed" 14 "SAE reserved" 13 "SAE reserved" 12 "SAE reserved" 11 "SAE reserved" 10 "SAE reserved" 9 "SAE reserved" 8 "SAE reserved" 7 "SAE reserved" 6 "SAE reserved" 5 "SAE reserved" 4 "SAE reserved" 3 "SAEpr12" 2 "SAEtp02" 1 "SAEpc07" 0 "SAEev03" ;
VAL_ 2633719550 Detector1DetectorType 15 "Not available or not installed" 14 "SAE Reserved" 13 "SAE Reserved" 12 "SAE Reserved" 11 "SAE Reserved" 10 "SAE Reserved" 9 "SAE Reserved" 8 "SAE Reserved" 7 "SAE Reserved" 6 "SAE Reserved" 5 "SAE Reserved" 4 "Manual release switch" 3 "Heat detector" 2 "Analog optical sensor" 1 "Analog gas sensor" 0 "Analog thermal sensor" ;
VAL_ 2633719294 Detector8DetectorDataSLOT 15 "Not available or not installed" 14 "SAE reserved" 13 "SAE reserved" 12 "SAE reserved" 11 "SAE reserved" 10 "SAE reserved" 9 "SAE reserved" 8 "SAE reserved" 7 "SAE reserved" 6 "SAE reserved" 5 "SAE reserved" 4 "SAE reserved" 3 "SAEpr12" 2 "SAEtp02" 1 "SAEpc07" 0 "SAEev03" ;
VAL_ 2633719294 Detector8DetectorType 15 "Not available or not installed" 14 "SAE Reserved" 13 "SAE Reserved" 12 "SAE Reserved" 11 "SAE Reserved" 10 "SAE Reserved" 9 "SAE Reserved" 8 "SAE Reserved" 7 "SAE Reserved" 6 "SAE Reserved" 5 "SAE Reserved" 4 "Manual release switch" 3 "Heat detector" 2 "Analog optical sensor" 1 "Analog gas sensor" 0 "Analog thermal sensor" ;
VAL_ 2633719294 Detector7DetectorDataSLOT 15 "Not available or not installed" 14 "SAE reserved" 13 "SAE reserved" 12 "SAE reserved" 11 "SAE reserved" 10 "SAE reserved" 9 "SAE reserved" 8 "SAE reserved" 7 "SAE reserved" 6 "SAE reserved" 5 "SAE reserved" 4 "SAE reserved" 3 "SAEpr12" 2 "SAEtp02" 1 "SAEpc07" 0 "SAEev03" ;
VAL_ 2633719294 Detector7DetectorType 15 "Not available or not installed" 14 "SAE Reserved" 13 "SAE Reserved" 12 "SAE Reserved" 11 "SAE Reserved" 10 "SAE Reserved" 9 "SAE Reserved" 8 "SAE Reserved" 7 "SAE Reserved" 6 "SAE Reserved" 5 "SAE Reserved" 4 "Manual release switch" 3 "Heat detector" 2 "Analog optical sensor" 1 "Analog gas sensor" 0 "Analog thermal sensor" ;
VAL_ 2633719294 Detector6DetectorDataSLOT 15 "Not available or not installed" 14 "SAE reserved" 13 "SAE reserved" 12 "SAE reserved" 11 "SAE reserved" 10 "SAE reserved" 9 "SAE reserved" 8 "SAE reserved" 7 "SAE reserved" 6 "SAE reserved" 5 "SAE reserved" 4 "SAE reserved" 3 "SAEpr12" 2 "SAEtp02" 1 "SAEpc07" 0 "SAEev03" ;
VAL_ 2633719294 Detector6DetectorType 15 "Not available or not installed" 14 "SAE Reserved" 13 "SAE Reserved" 12 "SAE Reserved" 11 "SAE Reserved" 10 "SAE Reserved" 9 "SAE Reserved" 8 "SAE Reserved" 7 "SAE Reserved" 6 "SAE Reserved" 5 "SAE Reserved" 4 "Manual release switch" 3 "Heat detector" 2 "Analog optical sensor" 1 "Analog gas sensor" 0 "Analog thermal sensor" ;
VAL_ 2633719294 Detector5DetectorDataSLOT 15 "Not available or not installed" 14 "SAE reserved" 13 "SAE reserved" 12 "SAE reserved" 11 "SAE reserved" 10 "SAE reserved" 9 "SAE reserved" 8 "SAE reserved" 7 "SAE reserved" 6 "SAE reserved" 5 "SAE reserved" 4 "SAE reserved" 3 "SAEpr12" 2 "SAEtp02" 1 "SAEpc07" 0 "SAEev03" ;
VAL_ 2633719294 Detector5DetectorType 15 "Not available or not installed" 14 "SAE Reserved" 13 "SAE Reserved" 12 "SAE Reserved" 11 "SAE Reserved" 10 "SAE Reserved" 9 "SAE Reserved" 8 "SAE Reserved" 7 "SAE Reserved" 6 "SAE Reserved" 5 "SAE Reserved" 4 "Manual release switch" 3 "Heat detector" 2 "Analog optical sensor" 1 "Analog gas sensor" 0 "Analog thermal sensor" ;
VAL_ 2633719294 Detector4DetectorDataSLOT 15 "Not available or not installed" 14 "SAE reserved" 13 "SAE reserved" 12 "SAE reserved" 11 "SAE reserved" 10 "SAE reserved" 9 "SAE reserved" 8 "SAE reserved" 7 "SAE reserved" 6 "SAE reserved" 5 "SAE reserved" 4 "SAE reserved" 3 "SAEpr12" 2 "SAEtp02" 1 "SAEpc07" 0 "SAEev03" ;
VAL_ 2633719294 Detector4DetectorType 15 "Not available or not installed" 14 "SAE Reserved" 13 "SAE Reserved" 12 "SAE Reserved" 11 "SAE Reserved" 10 "SAE Reserved" 9 "SAE Reserved" 8 "SAE Reserved" 7 "SAE Reserved" 6 "SAE Reserved" 5 "SAE Reserved" 4 "Manual release switch" 3 "Heat detector" 2 "Analog optical sensor" 1 "Analog gas sensor" 0 "Analog thermal sensor" ;
VAL_ 2633719294 Detector3DetectorDataSLOT 15 "Not available or not installed" 14 "SAE reserved" 13 "SAE reserved" 12 "SAE reserved" 11 "SAE reserved" 10 "SAE reserved" 9 "SAE reserved" 8 "SAE reserved" 7 "SAE reserved" 6 "SAE reserved" 5 "SAE reserved" 4 "SAE reserved" 3 "SAEpr12" 2 "SAEtp02" 1 "SAEpc07" 0 "SAEev03" ;
VAL_ 2633719294 Detector3DetectorType 15 "Not available or not installed" 14 "SAE Reserved" 13 "SAE Reserved" 12 "SAE Reserved" 11 "SAE Reserved" 10 "SAE Reserved" 9 "SAE Reserved" 8 "SAE Reserved" 7 "SAE Reserved" 6 "SAE Reserved" 5 "SAE Reserved" 4 "Manual release switch" 3 "Heat detector" 2 "Analog optical sensor" 1 "Analog gas sensor" 0 "Analog thermal sensor" ;
VAL_ 2633719294 Detector2DetectorDataSLOT 15 "Not available or not installed" 14 "SAE reserved" 13 "SAE reserved" 12 "SAE reserved" 11 "SAE reserved" 10 "SAE reserved" 9 "SAE reserved" 8 "SAE reserved" 7 "SAE reserved" 6 "SAE reserved" 5 "SAE reserved" 4 "SAE reserved" 3 "SAEpr12" 2 "SAEtp02" 1 "SAEpc07" 0 "SAEev03" ;
VAL_ 2633719294 Detector2DetectorType 15 "Not available or not installed" 14 "SAE Reserved" 13 "SAE Reserved" 12 "SAE Reserved" 11 "SAE Reserved" 10 "SAE Reserved" 9 "SAE Reserved" 8 "SAE Reserved" 7 "SAE Reserved" 6 "SAE Reserved" 5 "SAE Reserved" 4 "Manual release switch" 3 "Heat detector" 2 "Analog optical sensor" 1 "Analog gas sensor" 0 "Analog thermal sensor" ;
VAL_ 2633719294 Detector1DetectorDataSLOT 15 "Not available or not installed" 14 "SAE reserved" 13 "SAE reserved" 12 "SAE reserved" 11 "SAE reserved" 10 "SAE reserved" 9 "SAE reserved" 8 "SAE reserved" 7 "SAE reserved" 6 "SAE reserved" 5 "SAE reserved" 4 "SAE reserved" 3 "SAEpr12" 2 "SAEtp02" 1 "SAEpc07" 0 "SAEev03" ;
VAL_ 2633719294 Detector1DetectorType 15 "Not available or not installed" 14 "SAE Reserved" 13 "SAE Reserved" 12 "SAE Reserved" 11 "SAE Reserved" 10 "SAE Reserved" 9 "SAE Reserved" 8 "SAE Reserved" 7 "SAE Reserved" 6 "SAE Reserved" 5 "SAE Reserved" 4 "Manual release switch" 3 "Heat detector" 2 "Analog optical sensor" 1 "Analog gas sensor" 0 "Analog thermal sensor" ;
VAL_ 2633719038 Detector8DetectorDataSLOT 15 "Not available or not installed" 14 "SAE reserved" 13 "SAE reserved" 12 "SAE reserved" 11 "SAE reserved" 10 "SAE reserved" 9 "SAE reserved" 8 "SAE reserved" 7 "SAE reserved" 6 "SAE reserved" 5 "SAE reserved" 4 "SAE reserved" 3 "SAEpr12" 2 "SAEtp02" 1 "SAEpc07" 0 "SAEev03" ;
VAL_ 2633719038 Detector8DetectorType 15 "Not available or not installed" 14 "SAE Reserved" 13 "SAE Reserved" 12 "SAE Reserved" 11 "SAE Reserved" 10 "SAE Reserved" 9 "SAE Reserved" 8 "SAE Reserved" 7 "SAE Reserved" 6 "SAE Reserved" 5 "SAE Reserved" 4 "Manual release switch" 3 "Heat detector" 2 "Analog optical sensor" 1 "Analog gas sensor" 0 "Analog thermal sensor" ;
VAL_ 2633719038 Detector7DetectorDataSLOT 15 "Not available or not installed" 14 "SAE reserved" 13 "SAE reserved" 12 "SAE reserved" 11 "SAE reserved" 10 "SAE reserved" 9 "SAE reserved" 8 "SAE reserved" 7 "SAE reserved" 6 "SAE reserved" 5 "SAE reserved" 4 "SAE reserved" 3 "SAEpr12" 2 "SAEtp02" 1 "SAEpc07" 0 "SAEev03" ;
VAL_ 2633719038 Detector7DetectorType 15 "Not available or not installed" 14 "SAE Reserved" 13 "SAE Reserved" 12 "SAE Reserved" 11 "SAE Reserved" 10 "SAE Reserved" 9 "SAE Reserved" 8 "SAE Reserved" 7 "SAE Reserved" 6 "SAE Reserved" 5 "SAE Reserved" 4 "Manual release switch" 3 "Heat detector" 2 "Analog optical sensor" 1 "Analog gas sensor" 0 "Analog thermal sensor" ;
VAL_ 2633719038 Detector6DetectorDataSLOT 15 "Not available or not installed" 14 "SAE reserved" 13 "SAE reserved" 12 "SAE reserved" 11 "SAE reserved" 10 "SAE reserved" 9 "SAE reserved" 8 "SAE reserved" 7 "SAE reserved" 6 "SAE reserved" 5 "SAE reserved" 4 "SAE reserved" 3 "SAEpr12" 2 "SAEtp02" 1 "SAEpc07" 0 "SAEev03" ;
VAL_ 2633719038 Detector6DetectorType 15 "Not available or not installed" 14 "SAE Reserved" 13 "SAE Reserved" 12 "SAE Reserved" 11 "SAE Reserved" 10 "SAE Reserved" 9 "SAE Reserved" 8 "SAE Reserved" 7 "SAE Reserved" 6 "SAE Reserved" 5 "SAE Reserved" 4 "Manual release switch" 3 "Heat detector" 2 "Analog optical sensor" 1 "Analog gas sensor" 0 "Analog thermal sensor" ;
VAL_ 2633719038 Detector5DetectorDataSLOT 15 "Not available or not installed" 14 "SAE reserved" 13 "SAE reserved" 12 "SAE reserved" 11 "SAE reserved" 10 "SAE reserved" 9 "SAE reserved" 8 "SAE reserved" 7 "SAE reserved" 6 "SAE reserved" 5 "SAE reserved" 4 "SAE reserved" 3 "SAEpr12" 2 "SAEtp02" 1 "SAEpc07" 0 "SAEev03" ;
VAL_ 2633719038 Detector5DetectorType 15 "Not available or not installed" 14 "SAE Reserved" 13 "SAE Reserved" 12 "SAE Reserved" 11 "SAE Reserved" 10 "SAE Reserved" 9 "SAE Reserved" 8 "SAE Reserved" 7 "SAE Reserved" 6 "SAE Reserved" 5 "SAE Reserved" 4 "Manual release switch" 3 "Heat detector" 2 "Analog optical sensor" 1 "Analog gas sensor" 0 "Analog thermal sensor" ;
VAL_ 2633719038 Detector4DetectorDataSLOT 15 "Not available or not installed" 14 "SAE reserved" 13 "SAE reserved" 12 "SAE reserved" 11 "SAE reserved" 10 "SAE reserved" 9 "SAE reserved" 8 "SAE reserved" 7 "SAE reserved" 6 "SAE reserved" 5 "SAE reserved" 4 "SAE reserved" 3 "SAEpr12" 2 "SAEtp02" 1 "SAEpc07" 0 "SAEev03" ;
VAL_ 2633719038 Detector4DetectorType 15 "Not available or not installed" 14 "SAE Reserved" 13 "SAE Reserved" 12 "SAE Reserved" 11 "SAE Reserved" 10 "SAE Reserved" 9 "SAE Reserved" 8 "SAE Reserved" 7 "SAE Reserved" 6 "SAE Reserved" 5 "SAE Reserved" 4 "Manual release switch" 3 "Heat detector" 2 "Analog optical sensor" 1 "Analog gas sensor" 0 "Analog thermal sensor" ;
VAL_ 2633719038 Detector3DetectorDataSLOT 15 "Not available or not installed" 14 "SAE reserved" 13 "SAE reserved" 12 "SAE reserved" 11 "SAE reserved" 10 "SAE reserved" 9 "SAE reserved" 8 "SAE reserved" 7 "SAE reserved" 6 "SAE reserved" 5 "SAE reserved" 4 "SAE reserved" 3 "SAEpr12" 2 "SAEtp02" 1 "SAEpc07" 0 "SAEev03" ;
VAL_ 2633719038 Detector3DetectorType 15 "Not available or not installed" 14 "SAE Reserved" 13 "SAE Reserved" 12 "SAE Reserved" 11 "SAE Reserved" 10 "SAE Reserved" 9 "SAE Reserved" 8 "SAE Reserved" 7 "SAE Reserved" 6 "SAE Reserved" 5 "SAE Reserved" 4 "Manual release switch" 3 "Heat detector" 2 "Analog optical sensor" 1 "Analog gas sensor" 0 "Analog thermal sensor" ;
VAL_ 2633719038 Detector2DetectorDataSLOT 15 "Not available or not installed" 14 "SAE reserved" 13 "SAE reserved" 12 "SAE reserved" 11 "SAE reserved" 10 "SAE reserved" 9 "SAE reserved" 8 "SAE reserved" 7 "SAE reserved" 6 "SAE reserved" 5 "SAE reserved" 4 "SAE reserved" 3 "SAEpr12" 2 "SAEtp02" 1 "SAEpc07" 0 "SAEev03" ;
VAL_ 2633719038 Detector2DetectorType 15 "Not available or not installed" 14 "SAE Reserved" 13 "SAE Reserved" 12 "SAE Reserved" 11 "SAE Reserved" 10 "SAE Reserved" 9 "SAE Reserved" 8 "SAE Reserved" 7 "SAE Reserved" 6 "SAE Reserved" 5 "SAE Reserved" 4 "Manual release switch" 3 "Heat detector" 2 "Analog optical sensor" 1 "Analog gas sensor" 0 "Analog thermal sensor" ;
VAL_ 2633719038 Detector1DetectorDataSLOT 15 "Not available or not installed" 14 "SAE reserved" 13 "SAE reserved" 12 "SAE reserved" 11 "SAE reserved" 10 "SAE reserved" 9 "SAE reserved" 8 "SAE reserved" 7 "SAE reserved" 6 "SAE reserved" 5 "SAE reserved" 4 "SAE reserved" 3 "SAEpr12" 2 "SAEtp02" 1 "SAEpc07" 0 "SAEev03" ;
VAL_ 2633719038 Detector1DetectorType 15 "Not available or not installed" 14 "SAE Reserved" 13 "SAE Reserved" 12 "SAE Reserved" 11 "SAE Reserved" 10 "SAE Reserved" 9 "SAE Reserved" 8 "SAE Reserved" 7 "SAE Reserved" 6 "SAE Reserved" 5 "SAE Reserved" 4 "Manual release switch" 3 "Heat detector" 2 "Analog optical sensor" 1 "Analog gas sensor" 0 "Analog thermal sensor" ;
VAL_ 2633718782 Detector8DetectorDataSLOT 15 "Not available or not installed" 14 "SAE reserved" 13 "SAE reserved" 12 "SAE reserved" 11 "SAE reserved" 10 "SAE reserved" 9 "SAE reserved" 8 "SAE reserved" 7 "SAE reserved" 6 "SAE reserved" 5 "SAE reserved" 4 "SAE reserved" 3 "SAEpr12" 2 "SAEtp02" 1 "SAEpc07" 0 "SAEev03" ;
VAL_ 2633718782 Detector8DetectorType 15 "Not available or not installed" 14 "SAE Reserved" 13 "SAE Reserved" 12 "SAE Reserved" 11 "SAE Reserved" 10 "SAE Reserved" 9 "SAE Reserved" 8 "SAE Reserved" 7 "SAE Reserved" 6 "SAE Reserved" 5 "SAE Reserved" 4 "Manual release switch" 3 "Heat detector" 2 "Analog optical sensor" 1 "Analog gas sensor" 0 "Analog thermal sensor" ;
VAL_ 2633718782 Detector7DetectorDataSLOT 15 "Not available or not installed" 14 "SAE reserved" 13 "SAE reserved" 12 "SAE reserved" 11 "SAE reserved" 10 "SAE reserved" 9 "SAE reserved" 8 "SAE reserved" 7 "SAE reserved" 6 "SAE reserved" 5 "SAE reserved" 4 "SAE reserved" 3 "SAEpr12" 2 "SAEtp02" 1 "SAEpc07" 0 "SAEev03" ;
VAL_ 2633718782 Detector7DetectorType 15 "Not available or not installed" 14 "SAE Reserved" 13 "SAE Reserved" 12 "SAE Reserved" 11 "SAE Reserved" 10 "SAE Reserved" 9 "SAE Reserved" 8 "SAE Reserved" 7 "SAE Reserved" 6 "SAE Reserved" 5 "SAE Reserved" 4 "Manual release switch" 3 "Heat detector" 2 "Analog optical sensor" 1 "Analog gas sensor" 0 "Analog thermal sensor" ;
VAL_ 2633718782 Detector6DetectorDataSLOT 15 "Not available or not installed" 14 "SAE reserved" 13 "SAE reserved" 12 "SAE reserved" 11 "SAE reserved" 10 "SAE reserved" 9 "SAE reserved" 8 "SAE reserved" 7 "SAE reserved" 6 "SAE reserved" 5 "SAE reserved" 4 "SAE reserved" 3 "SAEpr12" 2 "SAEtp02" 1 "SAEpc07" 0 "SAEev03" ;
VAL_ 2633718782 Detector6DetectorType 15 "Not available or not installed" 14 "SAE Reserved" 13 "SAE Reserved" 12 "SAE Reserved" 11 "SAE Reserved" 10 "SAE Reserved" 9 "SAE Reserved" 8 "SAE Reserved" 7 "SAE Reserved" 6 "SAE Reserved" 5 "SAE Reserved" 4 "Manual release switch" 3 "Heat detector" 2 "Analog optical sensor" 1 "Analog gas sensor" 0 "Analog thermal sensor" ;
VAL_ 2633718782 Detector5DetectorDataSLOT 15 "Not available or not installed" 14 "SAE reserved" 13 "SAE reserved" 12 "SAE reserved" 11 "SAE reserved" 10 "SAE reserved" 9 "SAE reserved" 8 "SAE reserved" 7 "SAE reserved" 6 "SAE reserved" 5 "SAE reserved" 4 "SAE reserved" 3 "SAEpr12" 2 "SAEtp02" 1 "SAEpc07" 0 "SAEev03" ;
VAL_ 2633718782 Detector5DetectorType 15 "Not available or not installed" 14 "SAE Reserved" 13 "SAE Reserved" 12 "SAE Reserved" 11 "SAE Reserved" 10 "SAE Reserved" 9 "SAE Reserved" 8 "SAE Reserved" 7 "SAE Reserved" 6 "SAE Reserved" 5 "SAE Reserved" 4 "Manual release switch" 3 "Heat detector" 2 "Analog optical sensor" 1 "Analog gas sensor" 0 "Analog thermal sensor" ;
VAL_ 2633718782 Detector4DetectorDataSLOT 15 "Not available or not installed" 14 "SAE reserved" 13 "SAE reserved" 12 "SAE reserved" 11 "SAE reserved" 10 "SAE reserved" 9 "SAE reserved" 8 "SAE reserved" 7 "SAE reserved" 6 "SAE reserved" 5 "SAE reserved" 4 "SAE reserved" 3 "SAEpr12" 2 "SAEtp02" 1 "SAEpc07" 0 "SAEev03" ;
VAL_ 2633718782 Detector4DetectorType 15 "Not available or not installed" 14 "SAE Reserved" 13 "SAE Reserved" 12 "SAE Reserved" 11 "SAE Reserved" 10 "SAE Reserved" 9 "SAE Reserved" 8 "SAE Reserved" 7 "SAE Reserved" 6 "SAE Reserved" 5 "SAE Reserved" 4 "Manual release switch" 3 "Heat detector" 2 "Analog optical sensor" 1 "Analog gas sensor" 0 "Analog thermal sensor" ;
VAL_ 2633718782 Detector3DetectorDataSLOT 15 "Not available or not installed" 14 "SAE reserved" 13 "SAE reserved" 12 "SAE reserved" 11 "SAE reserved" 10 "SAE reserved" 9 "SAE reserved" 8 "SAE reserved" 7 "SAE reserved" 6 "SAE reserved" 5 "SAE reserved" 4 "SAE reserved" 3 "SAEpr12" 2 "SAEtp02" 1 "SAEpc07" 0 "SAEev03" ;
VAL_ 2633718782 Detector3DetectorType 15 "Not available or not installed" 14 "SAE Reserved" 13 "SAE Reserved" 12 "SAE Reserved" 11 "SAE Reserved" 10 "SAE Reserved" 9 "SAE Reserved" 8 "SAE Reserved" 7 "SAE Reserved" 6 "SAE Reserved" 5 "SAE Reserved" 4 "Manual release switch" 3 "Heat detector" 2 "Analog optical sensor" 1 "Analog gas sensor" 0 "Analog thermal sensor" ;
VAL_ 2633718782 Detector2DetectorDataSLOT 15 "Not available or not installed" 14 "SAE reserved" 13 "SAE reserved" 12 "SAE reserved" 11 "SAE reserved" 10 "SAE reserved" 9 "SAE reserved" 8 "SAE reserved" 7 "SAE reserved" 6 "SAE reserved" 5 "SAE reserved" 4 "SAE reserved" 3 "SAEpr12" 2 "SAEtp02" 1 "SAEpc07" 0 "SAEev03" ;
VAL_ 2633718782 Detector2DetectorType 15 "Not available or not installed" 14 "SAE Reserved" 13 "SAE Reserved" 12 "SAE Reserved" 11 "SAE Reserved" 10 "SAE Reserved" 9 "SAE Reserved" 8 "SAE Reserved" 7 "SAE Reserved" 6 "SAE Reserved" 5 "SAE Reserved" 4 "Manual release switch" 3 "Heat detector" 2 "Analog optical sensor" 1 "Analog gas sensor" 0 "Analog thermal sensor" ;
VAL_ 2633718782 Detector1DetectorDataSLOT 15 "Not available or not installed" 14 "SAE reserved" 13 "SAE reserved" 12 "SAE reserved" 11 "SAE reserved" 10 "SAE reserved" 9 "SAE reserved" 8 "SAE reserved" 7 "SAE reserved" 6 "SAE reserved" 5 "SAE reserved" 4 "SAE reserved" 3 "SAEpr12" 2 "SAEtp02" 1 "SAEpc07" 0 "SAEev03" ;
VAL_ 2633718782 Detector1DetectorType 15 "Not available or not installed" 14 "SAE Reserved" 13 "SAE Reserved" 12 "SAE Reserved" 11 "SAE Reserved" 10 "SAE Reserved" 9 "SAE Reserved" 8 "SAE Reserved" 7 "SAE Reserved" 6 "SAE Reserved" 5 "SAE Reserved" 4 "Manual release switch" 3 "Heat detector" 2 "Analog optical sensor" 1 "Analog gas sensor" 0 "Analog thermal sensor" ;
VAL_ 2499497726 LeverDetentPosStatus 3 "Not Available" 2 "Error Indicator" 1 "In the Detent Position" 0 "Not in the Detent Position" ;
VAL_ 2566605822 VSCtrlOpSt 7 "Not Available" 6 "Reserved" 5 "Reserved" 4 "Reserved" 3 "Maximum Retarder Torque" 2 "Normal Mode" 1 "Maximum Positive Torque" 0 "ADS Vehicle Speed Control Command Not Active" ;
VAL_ 2566605822 VSCtrlCmdReadinessStatus 3 "Not Available" 2 "Error" 1 "Ready" 0 "Not Ready" ;
VAL_ 2566605822 TSC1CtrlPurpP7ReadinessStatus 3 "Not Available/Not Supported." 2 "Error" 1 "Ready" 0 "Not Ready" ;
VAL_ 2566605566 TrqLimDueToMachineCharacter_0001 3 "Not Available" 2 "Error" 1 "Torque limited for this reason" 0 "No torque limit for this reason" ;
VAL_ 2566605566 PLedDueToActiveSpdRateLmt 3 "Not Available" 2 "Error" 1 "Power limited for this reason" 0 "No power limit for this reason" ;
VAL_ 2566605566 PLedDueToActiveTrqRateLmt 3 "Not Available" 2 "Error" 1 "Power limited for this reason" 0 "No power limit for this reason" ;
VAL_ 2566605566 PLedDueToFaultCondition 3 "Not Available" 2 "Error" 1 "Power limited for this reason" 0 "No power limit for this reason" ;
VAL_ 2566605566 PLedDueToMotorTemp 3 "Not Available" 2 "Error" 1 "Power limited for this reason" 0 "No power limit for this reason" ;
VAL_ 2566605566 PLedDueToInvTemp 3 "Not Available" 2 "Error" 1 "Power limited for this reason" 0 "No power limit for this reason" ;
VAL_ 2566605566 PLedDueToSpdMin 3 "Not Available" 2 "Error" 1 "Power limited for this reason" 0 "No power limit for this reason" ;
VAL_ 2566605566 PLedDueToSpdMax 3 "Not Available" 2 "Error" 1 "Power limited for this reason" 0 "No power limit for this reason" ;
VAL_ 2566605566 PLedDueToTrqMin 3 "Not Available" 2 "Error" 1 "Power limited for this reason" 0 "No power limit for this reason" ;
VAL_ 2566605566 PLedDueToTrqMax 3 "Not Available" 2 "Error" 1 "Power limited for this reason" 0 "No power limit for this reason" ;
VAL_ 2566605566 PLedDueToDCSidePwrMin 3 "Not Available" 2 "Error" 1 "Power limited for this reason" 0 "No power limit for this reason" ;
VAL_ 2566605566 PLedDueToDCSidePwrMax 3 "Not Available" 2 "Error" 1 "Power limited for this reason" 0 "No power limit for this reason" ;
VAL_ 2566605566 PLedDueToMechPwrMin 3 "Not Available" 2 "Error" 1 "Power limited for this reason" 0 "No power limit for this reason" ;
VAL_ 2566605566 PLedDueToMechPwrMax 3 "Not Available" 2 "Error" 1 "Power limited for this reason" 0 "No power limit for this reason" ;
VAL_ 2566605566 PLedDueToDCSideVMin 3 "Not Available" 2 "Error" 1 "Power limited for this reason" 0 "No power limit for this reason" ;
VAL_ 2566605566 PLedDueToDCSideVMax 3 "Not Available" 2 "Error" 1 "Power limited for this reason" 0 "No power limit for this reason" ;
VAL_ 2566605566 PLedDueToDCSideCurMin 3 "Not Available" 2 "Error" 1 "Power limited for this reason" 0 "No power limit for this reason" ;
VAL_ 2566605566 PLedDueToDCSideCurMax 3 "Not Available" 2 "Error" 1 "Power limited for this reason" 0 "No power limit for this reason" ;
VAL_ 2566605566 PLedDueToUndefinedReason 3 "Not Available" 2 "Error" 1 "Power limited for this reason" 0 "No power limit for this reason" ;
VAL_ 2566605310 HVBusPassiveIsolTestStatus 15 "Not available" 14 "Error" 13 "Reserved" 12 "Reserved" 11 "Reserved" 10 "Reserved" 9 "Reserved" 8 "Reserved" 7 "Reserved" 6 "Passive Isolation Test Inhibited" 5 "Test complete,  isolation fault" 4 "Test complete,  isolation marginal" 3 "Test complete,  isolation acceptable" 2 "Test in process" 1 "Test requested but not yet in process" 0 "No test requested / No test in process" ;
VAL_ 2566605310 HVBusActiveIsolTestStatus 15 "Not available" 14 "Error" 13 "Reserved" 12 "Reserved" 11 "Reserved" 10 "Reserved" 9 "Reserved" 8 "Reserved" 7 "Reserved" 6 "Active Isolation Test Inhibited" 5 "Test complete,  isolation fault" 4 "Test complete,  isolation marginal" 3 "Test complete,  isolation acceptable" 2 "Test in process" 1 "Test requested but not yet in process" 0 "No test requested / No test in process" ;
VAL_ 2566603774 TrqLimDueToMachineCharacter_0002 3 "Not Available" 2 "Error" 1 "Torque limited for this reason" 0 "No torque limit for this reason" ;
VAL_ 2566603774 PLedDueToActiveSpdRateLmt 3 "Not Available" 2 "Error" 1 "Power limited for this reason" 0 "No power limit for this reason" ;
VAL_ 2566603774 PLedDueToActiveTrqRateLmt 3 "Not Available" 2 "Error" 1 "Power limited for this reason" 0 "No power limit for this reason" ;
VAL_ 2566603774 PLedDueToFaultCondition 3 "Not Available" 2 "Error" 1 "Power limited for this reason" 0 "No power limit for this reason" ;
VAL_ 2566603774 PLedDueToMotorTemp 3 "Not Available" 2 "Error" 1 "Power limited for this reason" 0 "No power limit for this reason" ;
VAL_ 2566603774 PLedDueToInvTemp 3 "Not Available" 2 "Error" 1 "Power limited for this reason" 0 "No power limit for this reason" ;
VAL_ 2566603774 PLedDueToSpdMin 3 "Not Available" 2 "Error" 1 "Power limited for this reason" 0 "No power limit for this reason" ;
VAL_ 2566603774 PLedDueToSpdMax 3 "Not Available" 2 "Error" 1 "Power limited for this reason" 0 "No power limit for this reason" ;
VAL_ 2566603774 PLedDueToTrqMin 3 "Not Available" 2 "Error" 1 "Power limited for this reason" 0 "No power limit for this reason" ;
VAL_ 2566603774 PLedDueToTrqMax 3 "Not Available" 2 "Error" 1 "Power limited for this reason" 0 "No power limit for this reason" ;
VAL_ 2566603774 PLedDueToDCSidePwrMin 3 "Not Available" 2 "Error" 1 "Power limited for this reason" 0 "No power limit for this reason" ;
VAL_ 2566603774 PLedDueToDCSidePwrMax 3 "Not Available" 2 "Error" 1 "Power limited for this reason" 0 "No power limit for this reason" ;
VAL_ 2566603774 PLedDueToMechPwrMin 3 "Not Available" 2 "Error" 1 "Power limited for this reason" 0 "No power limit for this reason" ;
VAL_ 2566603774 PLedDueToMechPwrMax 3 "Not Available" 2 "Error" 1 "Power limited for this reason" 0 "No power limit for this reason" ;
VAL_ 2566603774 PLedDueToDCSideVMin 3 "Not Available" 2 "Error" 1 "Power limited for this reason" 0 "No power limit for this reason" ;
VAL_ 2566603774 PLedDueToDCSideVMax 3 "Not Available" 2 "Error" 1 "Power limited for this reason" 0 "No power limit for this reason" ;
VAL_ 2566603774 PLedDueToDCSideCurMin 3 "Not Available" 2 "Error" 1 "Power limited for this reason" 0 "No power limit for this reason" ;
VAL_ 2566603774 PLedDueToDCSideCurMax 3 "Not Available" 2 "Error" 1 "Power limited for this reason" 0 "No power limit for this reason" ;
VAL_ 2566603774 PLedDueToUndefinedReason 3 "Not Available" 2 "Error" 1 "Power limited for this reason" 0 "No power limit for this reason" ;
VAL_ 2566603518 HVBusPassiveIsolTestStatus 15 "Not available" 14 "Error" 13 "Reserved" 12 "Reserved" 11 "Reserved" 10 "Reserved" 9 "Reserved" 8 "Reserved" 7 "Reserved" 6 "Passive Isolation Test Inhibited" 5 "Test complete,  isolation fault" 4 "Test complete,  isolation marginal" 3 "Test complete,  isolation acceptable" 2 "Test in process" 1 "Test requested but not yet in process" 0 "No test requested / No test in process" ;
VAL_ 2566603518 HVBusActiveIsolTestStatus 15 "Not available" 14 "Error" 13 "Reserved" 12 "Reserved" 11 "Reserved" 10 "Reserved" 9 "Reserved" 8 "Reserved" 7 "Reserved" 6 "Active Isolation Test Inhibited" 5 "Test complete,  isolation fault" 4 "Test complete,  isolation marginal" 3 "Test complete,  isolation acceptable" 2 "Test in process" 1 "Test requested but not yet in process" 0 "No test requested / No test in process" ;
